VERSION ""

NS_ :

BS_:

BU_: WCM4 WCM3 WCM2 WCM VPM VLM VKM VICM VECM VDM VCU_RTOS_ETH VCU_ENTRY_ETH VCU_AGVM_ETH VCU UVM UPM TIM TEST_TOOL_1 TCP_ETH TCP TCM TCCM SRR_SRR_ETH SRR_SRR SRR_SLR_ETH SRR_SLR SRR_RR SRR_RF_ETH SRR_RF SRR_LR_CR SRR_LF_ETH SRR_LF SIB SDM SCL SBZA_R SBZA_L SBM SAM_RR SAM_RF SAM_LR SAM_LF SAM_BH SADS RadioLow_ETH RadioLow RSI_RTOS_ETH RSI RDCM PTM PLCM PFCM PDR_ETH PDR PCM PA ODS2 ODS NVM MTCM_R MTCM_L MSM_RR MSM_P MSM_LR MSM_D MSB2 MSB1 MRCM_R MRCM_L MFC LRR_RR_ETH LRR_LR_ETH LRR_CF_ETH LRR LRL_CF_ETH LIB_48V LIB1 IPC_INT IPC_GP IPC ICS_Info ICCM HVAC_FP_R HVAC_FP_F HUD_CAN HDLM FPI_RTOS_ETH FPI FOPM FCM_LC FCM EPSb EPS_1 EPSRAb EPSRAa EPS EOCM_HC_Superset EOCM_HCP2 EOCM ELM ECP_X1 ECP_S2 ECP_S ECP_MC ECP_H3 ECP_H2 ECP_H1 ECP_E ECM EBCM DMS DEFC DCM CSM_ETH CSM_AV CSM CGM_OTA_ETH CGM BSM_MH BSM_HEV BSM BCM ARS ARB APA AOS AMP ALC AHS AHL_AFL ADIMb ADIMa ACP2_MCU

BO_ 1416 Isolated_GWCGM_PDU04: 6 CGM
 SG_ TrffcLgtAsstWrnChmEvntStat : 1|2@0+ (1,0) [0|3] "" IPC,IPC_INT,VCU
 SG_ TrffcLgtAsstCstCurrSetVal : 4|3@0+ (1,0) [0|7] "" RadioLow,CSM,CSM_AV,VCU
 SG_ GlrFrHgBmRspTypCstCurSetVal : 7|3@0+ (1,0) [0|7] "" RadioLow,CSM,CSM_AV,VCU
 SG_ GlrFrHgBmRspTypCstAvlFlg7 : 8|1@0+ (1,0) [0|1] "" RadioLow,CSM,CSM_AV,VCU
 SG_ GlrFrHgBmRspTypCstAvlFlg6 : 9|1@0+ (1,0) [0|1] "" RadioLow,CSM,CSM_AV,VCU
 SG_ GlrFrHgBmRspTypCstAvlFlg5 : 10|1@0+ (1,0) [0|1] "" RadioLow,CSM,CSM_AV,VCU
 SG_ GlrFrHgBmRspTypCstAvlFlg4 : 11|1@0+ (1,0) [0|1] "" RadioLow,CSM,CSM_AV,VCU
 SG_ GlrFrHgBmRspTypCstAvlFlg3 : 12|1@0+ (1,0) [0|1] "" RadioLow,CSM,CSM_AV,VCU
 SG_ GlrFrHgBmRspTypCstAvlFlg2 : 13|1@0+ (1,0) [0|1] "" RadioLow,CSM,CSM_AV,VCU
 SG_ GlrFrHgBmRspTypCstAvlFlg1 : 14|1@0+ (1,0) [0|1] "" RadioLow,CSM,CSM_AV,VCU
 SG_ AutoHgBmCtrlIO : 15|1@0+ (1,0) [0|1] "" CSM,CSM_AV,IPC,IPC_INT,VCU
 SG_ TrffcLgtAsstCstAvlFlg7 : 16|1@0+ (1,0) [0|1] "" RadioLow,CSM,CSM_AV,VCU
 SG_ TrffcLgtAsstCstAvlFlg6 : 17|1@0+ (1,0) [0|1] "" RadioLow,CSM,CSM_AV,VCU
 SG_ TrffcLgtAsstCstAvlFlg5 : 18|1@0+ (1,0) [0|1] "" RadioLow,CSM,CSM_AV,VCU
 SG_ TrffcLgtAsstCstAvlFlg4 : 19|1@0+ (1,0) [0|1] "" RadioLow,CSM,CSM_AV,VCU
 SG_ TrffcLgtAsstCstAvlFlg3 : 20|1@0+ (1,0) [0|1] "" RadioLow,CSM,CSM_AV,VCU
 SG_ TrffcLgtAsstCstAvlFlg2 : 21|1@0+ (1,0) [0|1] "" RadioLow,CSM,CSM_AV,VCU
 SG_ TrffcLgtAsstCstAvlFlg1 : 22|1@0+ (1,0) [0|1] "" RadioLow,CSM,CSM_AV,VCU
 SG_ GlrFrHgBmRspTypCstStAvl : 23|1@0+ (1,0) [0|1] "" RadioLow,CSM,CSM_AV,VCU
 SG_ TrffcLgtAsstCstSetAval : 31|1@0+ (1,0) [0|1] "" RadioLow,CSM,CSM_AV,VCU

BO_ 1811 Isolated_GWCGM_PDU05: 8 CGM
 SG_ TSMCurrSpdLim : 7|8@0+ (1,0) [0|255] "" CSM,CSM_AV,IPC,IPC_INT,VCU
 SG_ TSMEurDispSgn2Mn : 9|6@0+ (1,0) [0|54] "" IPC,IPC_INT,VCU
 SG_ TSMEurDispSgn1Mn : 15|6@0+ (1,0) [0|54] "" IPC,IPC_INT,VCU
 SG_ TSMUSAndCADispSgn1Mn : 19|6@0+ (1,0) [0|45] "" CSM,CSM_AV,IPC,IPC_INT,VCU
 SG_ TSMUSAndCADispSgn2Mn : 29|6@0+ (1,0) [0|45] "" CSM,CSM_AV,IPC,IPC_INT,VCU
 SG_ TSMEurDispSgn2AddOn : 35|4@0+ (1,0) [0|15] "" IPC,IPC_INT,VCU
 SG_ TSMEurDispSgn1AddOn : 39|4@0+ (1,0) [0|15] "" IPC,IPC_INT,VCU
 SG_ FrwdVsFlDtcnIndOn : 40|1@0+ (1,0) [0|1] "" CSM,CSM_AV,IPC,IPC_INT,VCU
 SG_ FrwdVsAdvWthrIndOn : 41|1@0+ (1,0) [0|1] "" CSM,CSM_AV,IPC,IPC_INT,VCU
 SG_ TSMUSAndCADispSgn2AddOn : 44|3@0+ (1,0) [0|5] "" CSM,CSM_AV,IPC,IPC_INT,VCU
 SG_ TSMUSAndCADispSgn1AddOn : 47|3@0+ (1,0) [0|5] "" CSM,CSM_AV,IPC,IPC_INT,VCU
 SG_ TrffcLgtAsstHUDWrnIndOn : 48|1@0+ (1,0) [0|1] "" IPC,IPC_INT,VCU
 SG_ TrffcLgtAsstClstrWrnIndOn : 49|1@0+ (1,0) [0|1] "" IPC,IPC_INT,VCU
 SG_ TSMSgnNtfnIndOn : 50|1@0+ (1,0) [0|1] "" IPC,IPC_INT,VCU
 SG_ TSMPDAMnSgnFlshgReq : 51|1@0+ (1,0) [0|1] "" IPC,IPC_INT,VCU
 SG_ TSMNoEntryIndOn : 52|1@0+ (1,0) [0|1] "" IPC,IPC_INT,VCU
 SG_ TSMIcePsblIndOn : 53|1@0+ (1,0) [0|1] "" IPC,IPC_INT,VCU
 SG_ TSMAddTrfSgnAvIndOn : 54|1@0+ (1,0) [0|1] "" IPC,IPC_INT,VCU
 SG_ FrwdVsFllBlckIndOn : 55|1@0+ (1,0) [0|1] "" CSM,CSM_AV,IPC,IPC_INT,VCU
 SG_ TrffcLgtAsstRLADWrnIndOn : 63|1@0+ (1,0) [0|1] "" IPC,IPC_INT,VCU

BO_ 1510 Isolated_GWCGM_PDU06: 6 CGM
 SG_ SBZALCAVisIndStatLt : 7|2@0+ (1,0) [0|2] "" CSM,CSM_AV,VCU

BO_ 1511 Isolated_GWCGM_PDU07: 6 CGM
 SG_ SBZALCAVisIndStatRt : 7|2@0+ (1,0) [0|2] "" CSM,CSM_AV,VCU

BO_ 1429 Isolated_GWCGM_PDU08: 6 CSM
 SG_ HtchVwAutoElecPrkBrkAppReqd : 7|1@0+ (1,0) [0|1] "" Vector__XXX

BO_ 1512 Isolated_GWCGM_PDU10: 6 CGM
 SG_ AutoHgBmActReq : 7|1@0+ (1,0) [0|1] "" CSM,CSM_AV,VCU

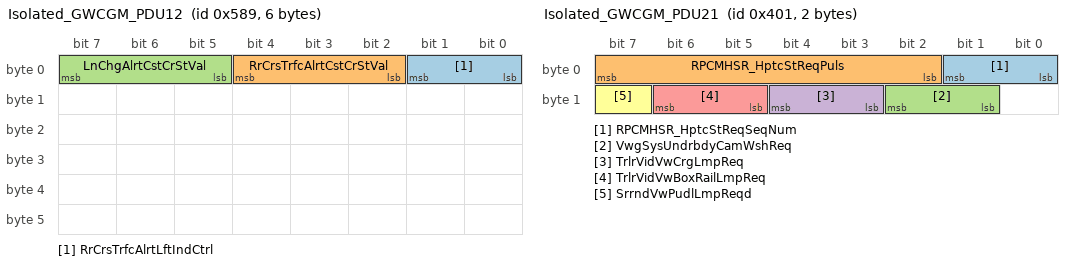
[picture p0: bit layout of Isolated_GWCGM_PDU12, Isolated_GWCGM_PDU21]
BO_ 1417 Isolated_GWCGM_PDU12: 6 CGM
 SG_ RrCrsTrfcAlrtLftIndCtrl : 1|2@0+ (1,0) [0|2] "" RadioLow,CSM,CSM_AV,VCU
 SG_ RrCrsTrfcAlrtCstCrStVal : 4|3@0+ (1,0) [0|7] "" RadioLow,CSM,CSM_AV,VCU
 SG_ LnChgAlrtCstCrStVal : 7|3@0+ (1,0) [0|7] "" RadioLow,TCP,CSM,CSM_AV,VCU

BO_ 1418 Isolated_GWCGM_PDU15: 8 CGM
 SG_ SBZAlrtCstCrStVal : 1|3@0+ (1,0) [0|7] "" RadioLow,CSM,CSM_AV,VCU
 SG_ ByclDtnCstCurrSetVal : 4|3@0+ (1,0) [0|2] "" VCU
 SG_ ByclDtnArbdIndStat : 7|3@0+ (1,0) [0|7] "" VCU
 SG_ ByclDtnCstAvlFlg1 : 8|1@0+ (1,0) [0|1] "" VCU
 SG_ RrCrsTrfcAlrtLtSdChmEvntStat : 10|2@0+ (1,0) [0|2] "" CSM,CSM_AV,IPC,IPC_INT,VCU
 SG_ ByclDtnArbdLvl2ChmEvntStat : 12|2@0+ (1,0) [0|2] "" VCU
 SG_ ByclDtnArbdLvl1ChmEvntStat : 14|2@0+ (1,0) [0|2] "" VCU
 SG_ LnChgAlrtCstAvlFlg1 : 16|1@0+ (1,0) [0|1] "" RadioLow,TCP,CSM,CSM_AV,VCU
 SG_ ByclDtnCstSetAval : 17|1@0+ (1,0) [0|1] "" VCU
 SG_ ByclDtnCstAvlFlg7 : 18|1@0+ (1,0) [0|1] "" VCU
 SG_ ByclDtnCstAvlFlg6 : 19|1@0+ (1,0) [0|1] "" VCU
 SG_ ByclDtnCstAvlFlg5 : 20|1@0+ (1,0) [0|1] "" VCU
 SG_ ByclDtnCstAvlFlg4 : 21|1@0+ (1,0) [0|1] "" VCU
 SG_ ByclDtnCstAvlFlg3 : 22|1@0+ (1,0) [0|1] "" VCU
 SG_ ByclDtnCstAvlFlg2 : 23|1@0+ (1,0) [0|1] "" VCU
 SG_ LnChgAlrtSysOffIndOn : 24|1@0+ (1,0) [0|1] "" TCP,IPC,IPC_INT,VCU
 SG_ LnChgAlrtCstStAvl : 25|1@0+ (1,0) [0|1] "" RadioLow,TCP,CSM,CSM_AV,VCU
 SG_ LnChgAlrtCstAvlFlg7 : 26|1@0+ (1,0) [0|1] "" RadioLow,TCP,CSM,CSM_AV,VCU
 SG_ LnChgAlrtCstAvlFlg6 : 27|1@0+ (1,0) [0|1] "" RadioLow,TCP,CSM,CSM_AV,VCU
 SG_ LnChgAlrtCstAvlFlg5 : 28|1@0+ (1,0) [0|1] "" RadioLow,TCP,CSM,CSM_AV,VCU
 SG_ LnChgAlrtCstAvlFlg4 : 29|1@0+ (1,0) [0|1] "" RadioLow,TCP,CSM,CSM_AV,VCU
 SG_ LnChgAlrtCstAvlFlg3 : 30|1@0+ (1,0) [0|1] "" RadioLow,TCP,CSM,CSM_AV,VCU
 SG_ LnChgAlrtCstAvlFlg2 : 31|1@0+ (1,0) [0|1] "" RadioLow,TCP,CSM,CSM_AV,VCU
 SG_ RrCrsTrfcAlrtCstStAvl : 32|1@0+ (1,0) [0|1] "" RadioLow,CSM,CSM_AV,VCU
 SG_ RrCrsTrfcAlrtCstAvlFlg7 : 33|1@0+ (1,0) [0|1] "" RadioLow,CSM,CSM_AV,VCU
 SG_ RrCrsTrfcAlrtCstAvlFlg6 : 34|1@0+ (1,0) [0|1] "" RadioLow,CSM,CSM_AV,VCU
 SG_ RrCrsTrfcAlrtCstAvlFlg5 : 35|1@0+ (1,0) [0|1] "" RadioLow,CSM,CSM_AV,VCU
 SG_ RrCrsTrfcAlrtCstAvlFlg4 : 36|1@0+ (1,0) [0|1] "" RadioLow,CSM,CSM_AV,VCU
 SG_ RrCrsTrfcAlrtCstAvlFlg3 : 37|1@0+ (1,0) [0|1] "" RadioLow,CSM,CSM_AV,VCU
 SG_ RrCrsTrfcAlrtCstAvlFlg2 : 38|1@0+ (1,0) [0|1] "" RadioLow,CSM,CSM_AV,VCU
 SG_ RrCrsTrfcAlrtCstAvlFlg1 : 39|1@0+ (1,0) [0|1] "" RadioLow,CSM,CSM_AV,VCU
 SG_ RrCrsTrfcBrkgAutoBrkgRelIndOn : 45|1@0+ (1,0) [0|1] "" IPC,IPC_INT,VCU
 SG_ RrCrsTrfcAutoBrkgOffIndOn : 46|1@0+ (1,0) [0|1] "" IPC,IPC_INT,VCU
 SG_ RrCrsTrfcAlrtOffIndOn : 47|1@0+ (1,0) [0|1] "" IPC,IPC_INT,VCU

BO_ 1419 Isolated_GWCGM_PDU17: 6 CGM
 SG_ RrCrsTrfcAlrtRtSdChmEvntStat : 5|2@0+ (1,0) [0|2] "" CSM,CSM_AV,IPC,IPC_INT,VCU
 SG_ RrCrsTrfcAlrtRgIndCtrl : 7|2@0+ (1,0) [0|2] "" RadioLow,CSM,CSM_AV,VCU

BO_ 1025 Isolated_GWCGM_PDU21: 2 VCU
 SG_ RPCMHSR_HptcStReqSeqNum : 1|2@0+ (1,0) [0|3] "Count" CGM
 SG_ RPCMHSR_HptcStReqPuls : 7|6@0+ (1,0) [0|63] "pulses" CGM
 SG_ VwgSysUndrbdyCamWshReq : 10|2@0+ (1,0) [0|2] "" CGM
 SG_ TrlrVidVwCrgLmpReq : 12|2@0+ (1,0) [0|2] "" CGM
 SG_ TrlrVidVwBoxRailLmpReq : 14|2@0+ (1,0) [0|2] "" CGM
 SG_ SrrndVwPudlLmpReqd : 15|1@0+ (1,0) [0|1] "" CGM

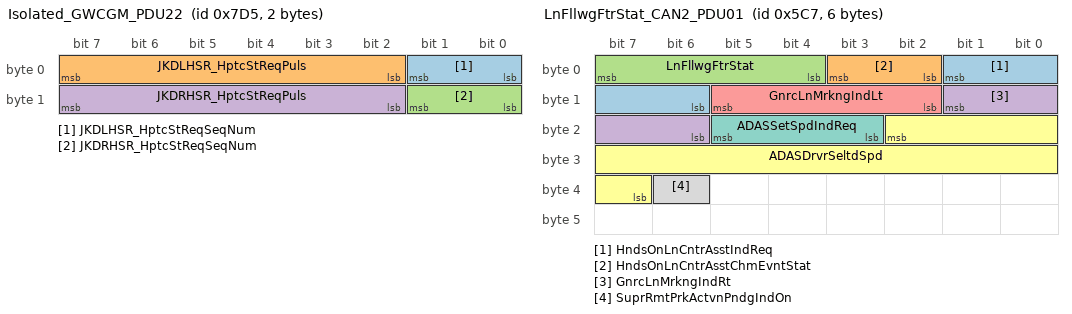
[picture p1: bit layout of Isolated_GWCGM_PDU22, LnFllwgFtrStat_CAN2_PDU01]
BO_ 2005 Isolated_GWCGM_PDU22: 2 VCU
 SG_ JKDLHSR_HptcStReqSeqNum : 1|2@0+ (1,0) [0|3] "counts" CGM
 SG_ JKDLHSR_HptcStReqPuls : 7|6@0+ (1,0) [0|63] "pulses" CGM
 SG_ JKDRHSR_HptcStReqSeqNum : 9|2@0+ (1,0) [0|3] "counts" CGM
 SG_ JKDRHSR_HptcStReqPuls : 15|6@0+ (1,0) [0|63] "pulses" CGM

BO_ 1479 LnFllwgFtrStat_CAN2_PDU01: 6 CGM
 SG_ HndsOnLnCntrAsstIndReq : 1|4@0+ (1,0) [0|7] "" IPC,IPC_INT,VCU
 SG_ HndsOnLnCntrAsstChmEvntStat : 3|2@0+ (1,0) [0|2] "" IPC,IPC_INT,VCU
 SG_ LnFllwgFtrStat : 7|4@0+ (1,0) [0|10] "" TCP
 SG_ GnrcLnMrkngIndRt : 9|4@0+ (1,0) [0|7] "" IPC,IPC_INT,VCU
 SG_ GnrcLnMrkngIndLt : 13|4@0+ (1,0) [0|7] "" IPC,IPC_INT,VCU
 SG_ ADASDrvrSeltdSpd : 18|12@0+ (0.0625,0) [0|255.938] "km/h" VCU
 SG_ ADASSetSpdIndReq : 21|3@0+ (1,0) [0|5] "" VCU
 SG_ SuprRmtPrkActvnPndgIndOn : 38|1@0+ (1,0) [0|1] "" VCU

BO_ 397 MFC_NM_PDU_On_CAN_5_Cluster: 8 MFC
 SG_ ISignal_MFC_CAN_5_Cluster : 23|48@0+ (1,0) [0|281474976710655] "" AMP,CGM,FPI,HVAC_FP_F,HVAC_FP_R,ICS_Info,PDR,PLCM,RSI,RadioLow,TCP,VKM,CSM,CSM_AV,IPC,IPC_INT,VCU,WCM,WCM2,WCM3,WCM4

BO_ 1883 PDU_1048: 8 CGM
 SG_ InvsblTrlrAux1CamPlcmtFdbkPtch : 7|12@0+ (0.1,-180) [-180|229.5] "degrees" CSM,CSM_AV,VCU
 SG_ InvsblTrlrAux1CamPlcmtFdbkRoll : 11|12@0+ (0.1,-180) [-180|229.5] "degrees" CSM,CSM_AV,VCU
 SG_ InvsblTrlrAux1CamPlcmtFdbkX : 31|12@0+ (0.1,-150) [-150|259.5] "cm" CSM,CSM_AV,VCU
 SG_ InvsblTrlrAux1CamPlcmtFdbkY : 35|12@0+ (0.1,-200) [-200|209.5] "cm" CSM,CSM_AV,VCU
 SG_ JckKnfDtnCstAvlFlg1 : 48|1@0+ (1,0) [0|1] "" RadioLow,CSM,CSM_AV,VCU
 SG_ CrgBedVwAutoLgtCstAvlFlg7 : 49|1@0+ (1,0) [0|1] "" RadioLow,CSM,CSM_AV,VCU
 SG_ CrgBedVwAutoLgtCstAvlFlg6 : 50|1@0+ (1,0) [0|1] "" RadioLow,CSM,CSM_AV,VCU
 SG_ CrgBedVwAutoLgtCstAvlFlg5 : 51|1@0+ (1,0) [0|1] "" RadioLow,CSM,CSM_AV,VCU
 SG_ CrgBedVwAutoLgtCstAvlFlg4 : 52|1@0+ (1,0) [0|1] "" RadioLow,CSM,CSM_AV,VCU
 SG_ CrgBedVwAutoLgtCstAvlFlg3 : 53|1@0+ (1,0) [0|1] "" RadioLow,CSM,CSM_AV,VCU
 SG_ CrgBedVwAutoLgtCstAvlFlg2 : 54|1@0+ (1,0) [0|1] "" RadioLow,CSM,CSM_AV,VCU
 SG_ CrgBedVwAutoLgtCstAvlFlg1 : 55|1@0+ (1,0) [0|1] "" RadioLow,CSM,CSM_AV,VCU
 SG_ JckKnfDtnCstAvlFlg7 : 58|1@0+ (1,0) [0|1] "" RadioLow,CSM,CSM_AV,VCU
 SG_ JckKnfDtnCstAvlFlg6 : 59|1@0+ (1,0) [0|1] "" RadioLow,CSM,CSM_AV,VCU
 SG_ JckKnfDtnCstAvlFlg5 : 60|1@0+ (1,0) [0|1] "" RadioLow,CSM,CSM_AV,VCU
 SG_ JckKnfDtnCstAvlFlg4 : 61|1@0+ (1,0) [0|1] "" RadioLow,CSM,CSM_AV,VCU
 SG_ JckKnfDtnCstAvlFlg3 : 62|1@0+ (1,0) [0|1] "" RadioLow,CSM,CSM_AV,VCU
 SG_ JckKnfDtnCstAvlFlg2 : 63|1@0+ (1,0) [0|1] "" RadioLow,CSM,CSM_AV,VCU

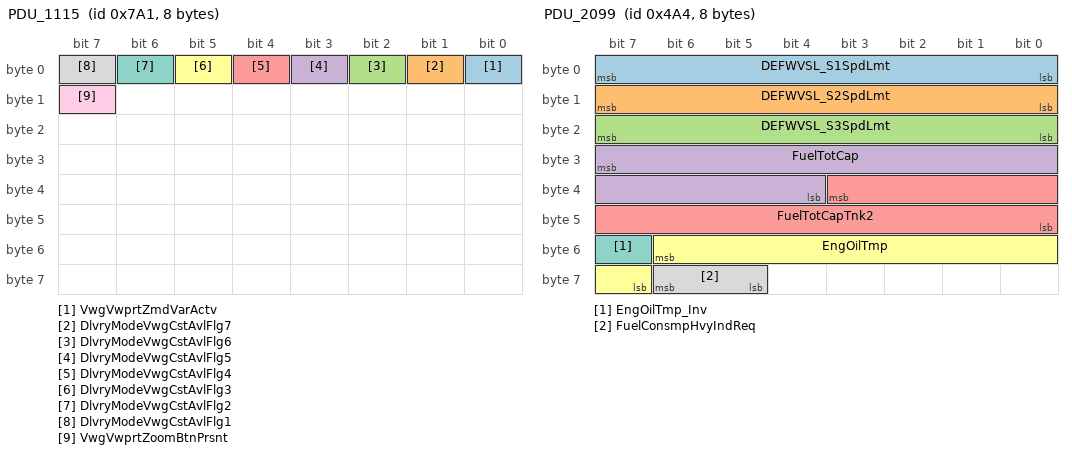
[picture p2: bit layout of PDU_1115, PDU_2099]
BO_ 1953 PDU_1115: 8 CGM
 SG_ VwgVwprtZmdVarActv : 0|1@0+ (1,0) [0|1] "" RadioLow,CSM,CSM_AV,VCU
 SG_ DlvryModeVwgCstAvlFlg7 : 1|1@0+ (1,0) [0|1] "" VCU
 SG_ DlvryModeVwgCstAvlFlg6 : 2|1@0+ (1,0) [0|1] "" VCU
 SG_ DlvryModeVwgCstAvlFlg5 : 3|1@0+ (1,0) [0|1] "" VCU
 SG_ DlvryModeVwgCstAvlFlg4 : 4|1@0+ (1,0) [0|1] "" VCU
 SG_ DlvryModeVwgCstAvlFlg3 : 5|1@0+ (1,0) [0|1] "" VCU
 SG_ DlvryModeVwgCstAvlFlg2 : 6|1@0+ (1,0) [0|1] "" VCU
 SG_ DlvryModeVwgCstAvlFlg1 : 7|1@0+ (1,0) [0|1] "" VCU
 SG_ VwgVwprtZoomBtnPrsnt : 15|1@0+ (1,0) [0|1] "" RadioLow,CSM,CSM_AV,VCU

BO_ 1114 PDU_1116: 8 CGM
 SG_ VwgCtlBtnPrsncBedHtch : 0|1@0+ (1,0) [0|1] "" RadioLow,CSM,CSM_AV,VCU
 SG_ VwgCtlBtnAvlUndrBdyFwdStActv : 1|1@0+ (1,0) [0|1] "" RadioLow,CSM,CSM_AV,VCU
 SG_ VwgCtlBtnAvlUndrBdyFwdRwdStActv : 2|1@0+ (1,0) [0|1] "" RadioLow,CSM,CSM_AV,VCU
 SG_ VwgCtlBtnAvlTopDnVwActv : 3|1@0+ (1,0) [0|1] "" RadioLow,CSM,CSM_AV,VCU
 SG_ DlvryModeVwgCstSetAval : 4|1@0+ (1,0) [0|1] "" VCU
 SG_ DlvryModeVwgCstCurrSetVal : 7|3@0+ (1,0) [0|2] "" VCU
 SG_ VwgCtlBtnPrsncFrtPrspctv : 8|1@0+ (1,0) [0|1] "" RadioLow,CSM,CSM_AV,VCU
 SG_ VwgCtlBtnPrsncFrtOvrhd : 9|1@0+ (1,0) [0|1] "" RadioLow,CSM,CSM_AV,VCU
 SG_ VwgCtlBtnPrsncFrtJnctn : 10|1@0+ (1,0) [0|1] "" RadioLow,CSM,CSM_AV,VCU
 SG_ VwgCtlBtnPrsncDynGdlns : 11|1@0+ (1,0) [0|1] "" RadioLow,CSM,CSM_AV,VCU
 SG_ VwgCtlBtnPrsncCurbOvrhd : 12|1@0+ (1,0) [0|1] "" RadioLow,CSM,CSM_AV,VCU
 SG_ VwgCtlBtnPrsncCurb : 13|1@0+ (1,0) [0|1] "" RadioLow,CSM,CSM_AV,VCU
 SG_ VwgCtlBtnPrsncCrgBed : 14|1@0+ (1,0) [0|1] "" RadioLow,CSM,CSM_AV,VCU
 SG_ VwgCtlBtnPrsncBowl : 15|1@0+ (1,0) [0|1] "" RadioLow,CSM,CSM_AV,VCU
 SG_ VwgCtlBtnPrsncSdRwd : 16|1@0+ (1,0) [0|1] "" RadioLow,CSM,CSM_AV,VCU
 SG_ VwgCtlBtnPrsncSdFwd : 17|1@0+ (1,0) [0|1] "" RadioLow,CSM,CSM_AV,VCU
 SG_ VwgCtlBtnPrsncRrPrspctv : 18|1@0+ (1,0) [0|1] "" RadioLow,CSM,CSM_AV,VCU
 SG_ VwgCtlBtnPrsncRrOvrhd : 19|1@0+ (1,0) [0|1] "" RadioLow,CSM,CSM_AV,VCU
 SG_ VwgCtlBtnPrsncRrJnctn : 20|1@0+ (1,0) [0|1] "" RadioLow,CSM,CSM_AV,VCU
 SG_ VwgCtlBtnPrsncRrHtch : 21|1@0+ (1,0) [0|1] "" RadioLow,CSM,CSM_AV,VCU
 SG_ VwgCtlBtnPrsncJP : 22|1@0+ (1,0) [0|1] "" RadioLow,CSM,CSM_AV,VCU
 SG_ VwgCtlBtnPrsncInvsblTrlr : 23|1@0+ (1,0) [0|1] "" RadioLow,CSM,CSM_AV,VCU
 SG_ VwgCtlBtnPrsncUndrBdyFwdRwdSt : 24|1@0+ (1,0) [0|1] "" RadioLow,CSM,CSM_AV,VCU
 SG_ VwgCtlBtnPrsncUndrBdyFwd : 25|1@0+ (1,0) [0|1] "" RadioLow,CSM,CSM_AV,VCU
 SG_ VwgCtlBtnPrsncTrlrTowMir : 26|1@0+ (1,0) [0|1] "" RadioLow,CSM,CSM_AV,VCU
 SG_ VwgCtlBtnPrsncTrlrGdlns : 27|1@0+ (1,0) [0|1] "" RadioLow,CSM,CSM_AV,VCU
 SG_ VwgCtlBtnPrsncTrlrAux1Cmbd : 28|1@0+ (1,0) [0|1] "" RadioLow,CSM,CSM_AV,VCU
 SG_ VwgCtlBtnPrsncTrlrAux1 : 29|1@0+ (1,0) [0|1] "" RadioLow,CSM,CSM_AV,VCU
 SG_ VwgCtlBtnPrsncTransparentHood : 30|1@0+ (1,0) [0|1] "" RadioLow,CSM,CSM_AV,VCU
 SG_ VwgCtlBtnPrsncTopDnSrrndVw : 31|1@0+ (1,0) [0|1] "" RadioLow,CSM,CSM_AV,VCU
 SG_ TrlrCamCalPrgs : 33|7@0+ (1,0) [0|127] "" CSM,CSM_AV,VCU
 SG_ VwgVwprtStsTopDnVwActv : 34|1@0+ (1,0) [0|1] "" RadioLow,CSM,CSM_AV,VCU
 SG_ VwgVwprtNtfnActv : 35|1@0+ (1,0) [0|1] "" RadioLow,CSM,CSM_AV,VCU
 SG_ VwgCtlBtnPrsncTrlrAux2 : 36|1@0+ (1,0) [0|1] "" RadioLow,CSM,CSM_AV,VCU
 SG_ VwgCtlBtnPrsncZmdBowl : 37|1@0+ (1,0) [0|1] "" RadioLow,CSM,CSM_AV,VCU
 SG_ VwgCtlBtnPrsncUndrBdyRwd : 38|1@0+ (1,0) [0|1] "" RadioLow,CSM,CSM_AV,VCU
 SG_ VwgCtlBtnPrsncUndrBdyFwdSt : 39|1@0+ (1,0) [0|1] "" RadioLow,CSM,CSM_AV,VCU
 SG_ TrlrJckKnfVisAlrtReq : 41|2@0+ (1,0) [0|3] "" CSM,CSM_AV,VCU
 SG_ TrlrCamCalPrgs_Inv : 42|1@0+ (1,0) [0|1] "" CSM,CSM_AV,VCU

BO_ 1984 PDU_1117: 8 CGM
 SG_ DMPDAutoClsTmLFCstSetAval : 0|1@0+ (1,0) [0|1] "" VCU
 SG_ DMPDAutoClsTmLFCstAvlFlg7 : 1|1@0+ (1,0) [0|1] "" VCU
 SG_ DMPDAutoClsTmLFCstAvlFlg6 : 2|1@0+ (1,0) [0|1] "" VCU
 SG_ DMPDAutoClsTmLFCstAvlFlg5 : 3|1@0+ (1,0) [0|1] "" VCU
 SG_ DMPDAutoClsTmLFCstAvlFlg4 : 4|1@0+ (1,0) [0|1] "" VCU
 SG_ DMPDAutoClsTmLFCstAvlFlg3 : 5|1@0+ (1,0) [0|1] "" VCU
 SG_ DMPDAutoClsTmLFCstAvlFlg2 : 6|1@0+ (1,0) [0|1] "" VCU
 SG_ DMPDAutoClsTmLFCstAvlFlg1 : 7|1@0+ (1,0) [0|1] "" VCU
 SG_ DMPDClsOutofPrkLFCstSetAval : 8|1@0+ (1,0) [0|1] "" VCU
 SG_ DMPDClsOutofPrkLFCstAvlFlg7 : 9|1@0+ (1,0) [0|1] "" VCU
 SG_ DMPDClsOutofPrkLFCstAvlFlg6 : 10|1@0+ (1,0) [0|1] "" VCU
 SG_ DMPDClsOutofPrkLFCstAvlFlg5 : 11|1@0+ (1,0) [0|1] "" VCU
 SG_ DMPDClsOutofPrkLFCstAvlFlg4 : 12|1@0+ (1,0) [0|1] "" VCU
 SG_ DMPDClsOutofPrkLFCstAvlFlg3 : 13|1@0+ (1,0) [0|1] "" VCU
 SG_ DMPDClsOutofPrkLFCstAvlFlg2 : 14|1@0+ (1,0) [0|1] "" VCU
 SG_ DMPDClsOutofPrkLFCstAvlFlg1 : 15|1@0+ (1,0) [0|1] "" VCU
 SG_ DMPDDOBlkhdDrOpnLFCstSetAval : 16|1@0+ (1,0) [0|1] "" VCU
 SG_ DMPDDOBlkhdDrOpnLFCstAvlFlg7 : 17|1@0+ (1,0) [0|1] "" VCU
 SG_ DMPDDOBlkhdDrOpnLFCstAvlFlg6 : 18|1@0+ (1,0) [0|1] "" VCU
 SG_ DMPDDOBlkhdDrOpnLFCstAvlFlg5 : 19|1@0+ (1,0) [0|1] "" VCU
 SG_ DMPDDOBlkhdDrOpnLFCstAvlFlg4 : 20|1@0+ (1,0) [0|1] "" VCU
 SG_ DMPDDOBlkhdDrOpnLFCstAvlFlg3 : 21|1@0+ (1,0) [0|1] "" VCU
 SG_ DMPDDOBlkhdDrOpnLFCstAvlFlg2 : 22|1@0+ (1,0) [0|1] "" VCU
 SG_ DMPDDOBlkhdDrOpnLFCstAvlFlg1 : 23|1@0+ (1,0) [0|1] "" VCU
 SG_ SCAOOAByKeyFobLFCstSetAval : 24|1@0+ (1,0) [0|1] "" VCU
 SG_ SCAOOAByKeyFobLFCstAvlFlg7 : 25|1@0+ (1,0) [0|1] "" VCU
 SG_ SCAOOAByKeyFobLFCstAvlFlg6 : 26|1@0+ (1,0) [0|1] "" VCU
 SG_ SCAOOAByKeyFobLFCstAvlFlg5 : 27|1@0+ (1,0) [0|1] "" VCU
 SG_ SCAOOAByKeyFobLFCstAvlFlg4 : 28|1@0+ (1,0) [0|1] "" VCU
 SG_ SCAOOAByKeyFobLFCstAvlFlg3 : 29|1@0+ (1,0) [0|1] "" VCU
 SG_ SCAOOAByKeyFobLFCstAvlFlg2 : 30|1@0+ (1,0) [0|1] "" VCU
 SG_ SCAOOAByKeyFobLFCstAvlFlg1 : 31|1@0+ (1,0) [0|1] "" VCU
 SG_ SCAOOAByVirtKeyLFCstSetAval : 32|1@0+ (1,0) [0|1] "" VCU
 SG_ SCAOOAByVirtKeyLFCstAvlFlg7 : 33|1@0+ (1,0) [0|1] "" VCU
 SG_ SCAOOAByVirtKeyLFCstAvlFlg6 : 34|1@0+ (1,0) [0|1] "" VCU
 SG_ SCAOOAByVirtKeyLFCstAvlFlg5 : 35|1@0+ (1,0) [0|1] "" VCU
 SG_ SCAOOAByVirtKeyLFCstAvlFlg4 : 36|1@0+ (1,0) [0|1] "" VCU
 SG_ SCAOOAByVirtKeyLFCstAvlFlg3 : 37|1@0+ (1,0) [0|1] "" VCU
 SG_ SCAOOAByVirtKeyLFCstAvlFlg2 : 38|1@0+ (1,0) [0|1] "" VCU
 SG_ SCAOOAByVirtKeyLFCstAvlFlg1 : 39|1@0+ (1,0) [0|1] "" VCU
 SG_ SCAPDBrktoClsLFCstSetAval : 40|1@0+ (1,0) [0|1] "" VCU
 SG_ SCAPDBrktoClsLFCstAvlFlg7 : 41|1@0+ (1,0) [0|1] "" VCU
 SG_ SCAPDBrktoClsLFCstAvlFlg6 : 42|1@0+ (1,0) [0|1] "" VCU
 SG_ SCAPDBrktoClsLFCstAvlFlg5 : 43|1@0+ (1,0) [0|1] "" VCU
 SG_ SCAPDBrktoClsLFCstAvlFlg4 : 44|1@0+ (1,0) [0|1] "" VCU
 SG_ SCAPDBrktoClsLFCstAvlFlg3 : 45|1@0+ (1,0) [0|1] "" VCU
 SG_ SCAPDBrktoClsLFCstAvlFlg2 : 46|1@0+ (1,0) [0|1] "" VCU
 SG_ SCAPDBrktoClsLFCstAvlFlg1 : 47|1@0+ (1,0) [0|1] "" VCU
 SG_ SCAPDOpnMaxTrvlCstSetAval : 48|1@0+ (1,0) [0|1] "" VCU
 SG_ SCAPDOpnMaxTrvlCstAvlFlg7 : 49|1@0+ (1,0) [0|1] "" VCU
 SG_ SCAPDOpnMaxTrvlCstAvlFlg6 : 50|1@0+ (1,0) [0|1] "" VCU
 SG_ SCAPDOpnMaxTrvlCstAvlFlg5 : 51|1@0+ (1,0) [0|1] "" VCU
 SG_ SCAPDOpnMaxTrvlCstAvlFlg4 : 52|1@0+ (1,0) [0|1] "" VCU
 SG_ SCAPDOpnMaxTrvlCstAvlFlg3 : 53|1@0+ (1,0) [0|1] "" VCU
 SG_ SCAPDOpnMaxTrvlCstAvlFlg2 : 54|1@0+ (1,0) [0|1] "" VCU
 SG_ SCAPDOpnMaxTrvlCstAvlFlg1 : 55|1@0+ (1,0) [0|1] "" VCU
 SG_ DMPDClsOutofPrkLFCstCurrSetVal : 59|3@0+ (1,0) [0|2] "" VCU
 SG_ DMPDAutoClsTmLFCstCurrSetVal : 62|3@0+ (1,0) [0|3] "" VCU
 SG_ SCAPwrDrMtnLFVirtCtlAval : 63|1@0+ (1,0) [0|1] "" VCU

BO_ 1060 PDU_1118: 8 CGM
 SG_ PwrSdClsrLFBlckdIndOn : 0|1@0+ (1,0) [0|1] "" VCU
 SG_ PwrSdClsrLFServIndOn : 15|1@0+ (1,0) [0|1] "" VCU

BO_ 1059 PDU_1119: 8 CGM
 SG_ PwrSdClsrLRBlckdIndOn : 0|1@0+ (1,0) [0|1] "" VCU
 SG_ PwrSdClsrLRServIndOn : 15|1@0+ (1,0) [0|1] "" VCU

BO_ 1188 PDU_2099: 8 CGM
 SG_ DEFWVSL_S1SpdLmt : 7|8@0+ (1,0) [0|255] "km / h" IPC,IPC_INT,VCU
 SG_ DEFWVSL_S2SpdLmt : 15|8@0+ (1,0) [0|255] "km / h" IPC,IPC_INT,VCU
 SG_ DEFWVSL_S3SpdLmt : 23|8@0+ (1,0) [0|255] "km / h" IPC,IPC_INT,VCU
 SG_ FuelTotCap : 31|12@0+ (0.125,0) [0|511.875] "liters" TCP,CSM,CSM_AV,IPC,IPC_INT,VCU
 SG_ FuelTotCapTnk2 : 35|12@0+ (0.125,0) [0|511.875] "liters" CSM,CSM_AV,IPC,IPC_INT,VCU
 SG_ EngOilTmp : 54|8@0+ (1,-40) [-40|215] "deg C" PDR,TCP,CSM,CSM_AV,IPC,IPC_INT,VCU
 SG_ EngOilTmp_Inv : 55|1@0+ (1,0) [0|1] "" PDR,CSM,CSM_AV,IPC,IPC_INT,VCU
 SG_ FuelConsmpHvyIndReq : 62|2@0+ (1,0) [0|2] "" IPC,IPC_INT,VCU

BO_ 1792 PDU_2100: 8 CGM
 SG_ DslExFldTpWrngIndRq : 3|4@0+ (1,0) [0|15] "" IPC,IPC_INT,VCU
 SG_ DslExFldCnWrngIndRq : 7|4@0+ (1,0) [0|15] "" IPC,IPC_INT,VCU
 SG_ DslExhFldQlyWrngIReq : 11|4@0+ (1,0) [0|15] "" IPC,IPC_INT,VCU
 SG_ DslExNxEmWrngIndRq : 15|4@0+ (1,0) [0|15] "" IPC,IPC_INT,VCU
 SG_ DslExhFldRmnDist : 23|15@0+ (2,0) [0|65534] "km" TCP,CSM,CSM_AV,IPC,IPC_INT,VCU
 SG_ DslExhFldRmnDist_Inv : 24|1@0+ (1,0) [0|1] "" TCP,CSM,CSM_AV,IPC,IPC_INT,VCU
 SG_ DslExhFluidDistTIndcmt : 35|15@0+ (2,0) [0|65534] "km" IPC,IPC_INT,VCU
 SG_ DslExhFldWrngIdRqER : 39|4@0+ (1,0) [0|15] "" TCP,IPC,IPC_INT,VCU
 SG_ ASIRI_Ind05 : 48|1@0+ (1,0) [0|1] "" TCP,CSM,CSM_AV,VCU
 SG_ ASIRI_Ind04 : 49|1@0+ (1,0) [0|1] "" TCP,CSM,CSM_AV,VCU
 SG_ ASIRI_Ind03 : 50|1@0+ (1,0) [0|1] "" TCP,CSM,CSM_AV,VCU
 SG_ ASIRI_Ind02 : 51|1@0+ (1,0) [0|1] "" TCP,CSM,CSM_AV,VCU
 SG_ ASIRI_Ind01 : 52|1@0+ (1,0) [0|1] "" TCP,CSM,CSM_AV,VCU
 SG_ FstIdlModeIndReq : 57|2@0+ (1,0) [0|3] "" IPC,IPC_INT,VCU
 SG_ CkFlFilrCapIO : 58|1@0+ (1,0) [0|1] "" CSM,CSM_AV,IPC,IPC_INT,VCU
 SG_ CbnHtrWrmUpIndOn : 59|1@0+ (1,0) [0|1] "" IPC,IPC_INT,VCU
 SG_ AppCltchAutSrtIO : 60|1@0+ (1,0) [0|1] "" CSM,CSM_AV,IPC,IPC_INT,VCU
 SG_ ASIRI_Ind08 : 61|1@0+ (1,0) [0|1] "" TCP,CSM,CSM_AV,VCU
 SG_ ASIRI_Ind07 : 62|1@0+ (1,0) [0|1] "" TCP,CSM,CSM_AV,VCU
 SG_ ASIRI_Ind06 : 63|1@0+ (1,0) [0|1] "" TCP,CSM,CSM_AV,VCU

BO_ 1273 PDU_2101: 8 CGM
 SG_ PTOSet1SpdCstCurrSetVal : 3|4@0+ (1,0) [0|15] "" RadioLow,CSM,CSM_AV,VCU
 SG_ PTOEngRunTmrCstCurrSetVal : 7|4@0+ (1,0) [0|15] "" RadioLow,CSM,CSM_AV,VCU
 SG_ MnlTrnsIndReq : 8|3@0+ (1,0) [0|3] "" IPC,IPC_INT,VCU
 SG_ EngAirFiltMonSts : 11|3@0+ (1,0) [0|5] "" CSM,CSM_AV,IPC,IPC_INT,VCU
 SG_ PTOSet2SpdCstCurrSetVal : 15|4@0+ (1,0) [0|15] "" RadioLow,CSM,CSM_AV,VCU
 SG_ PTOTpStpSpdCstCurrSetVal : 18|3@0+ (1,0) [0|7] "" RadioLow,CSM,CSM_AV,VCU
 SG_ PTOStndbySpdCstCurrSetVal : 21|3@0+ (1,0) [0|7] "" RadioLow,CSM,CSM_AV,VCU
 SG_ EngHtStpEngIO : 24|1@0+ (1,0) [0|1] "" TCP,CSM,CSM_AV,IPC,IPC_INT,VCU
 SG_ EngHtFlEnrchmntIO : 25|1@0+ (1,0) [0|1] "" TCP,CSM,CSM_AV,IPC,IPC_INT,VCU
 SG_ PTOModeCstCurrSetVal : 27|2@0+ (1,0) [0|2] "" RadioLow,CSM,CSM_AV,VCU
 SG_ PTOEngmntStsInd : 29|2@0+ (1,0) [0|3] "" IPC,IPC_INT,VCU
 SG_ PTOEngSpdTypCstCurrSetVal : 31|2@0+ (1,0) [0|2] "" RadioLow,CSM,CSM_AV,VCU
 SG_ EngWtrInFlIO : 32|1@0+ (1,0) [0|1] "" TCP,CSM,CSM_AV,IPC,IPC_INT,VCU
 SG_ EngSpdLmtnMdAct : 33|1@0+ (1,0) [0|1] "" CSM,CSM_AV,IPC,IPC_INT,VCU
 SG_ EngShtdwnPndgIO : 34|1@0+ (1,0) [0|1] "" TCP,CSM,CSM_AV,IPC,IPC_INT,VCU
 SG_ EngOilStrvtnIO : 35|1@0+ (1,0) [0|1] "" CSM,CSM_AV,IPC,IPC_INT,VCU
 SG_ EngOilPrsLwIO : 36|1@0+ (1,0) [0|1] "" TCP,CSM,CSM_AV,IPC,IPC_INT,VCU
 SG_ EngOilLvlLwIO : 37|1@0+ (1,0) [0|1] "" RadioLow,TCP,VKM,CSM,CSM_AV,IPC,IPC_INT,VCU
 SG_ EngOilHotIO : 38|1@0+ (1,0) [0|1] "" CSM,CSM_AV,IPC,IPC_INT,VCU
 SG_ EngOilChngIO : 39|1@0+ (1,0) [0|1] "" RadioLow,TCP,VKM,CSM,CSM_AV,IPC,IPC_INT,VCU
 SG_ PTOMblModeTransInGrIndOn : 40|1@0+ (1,0) [0|1] "" IPC,IPC_INT,VCU
 SG_ PTOEngUpnBrkRelIndOn : 41|1@0+ (1,0) [0|1] "" IPC,IPC_INT,VCU
 SG_ PTOEngSpdTypCstSetAval : 42|1@0+ (1,0) [0|1] "" RadioLow,CSM,CSM_AV,VCU
 SG_ PTOEngRunTmrCstSetAval : 43|1@0+ (1,0) [0|1] "" RadioLow,CSM,CSM_AV,VCU
 SG_ PTODisengCruzCtlIndOn : 44|1@0+ (1,0) [0|1] "" IPC,IPC_INT,VCU
 SG_ PTOAccelUpnBrkRelIndOn : 45|1@0+ (1,0) [0|1] "" IPC,IPC_INT,VCU
 SG_ PTExPrtclFltrWrnIO : 46|1@0+ (1,0) [0|1] "" TCP,CSM,CSM_AV,IPC,IPC_INT,VCU
 SG_ PTExPrtclFltrWrn2IO : 47|1@0+ (1,0) [0|1] "" TCP,CSM,CSM_AV,IPC,IPC_INT,VCU
 SG_ PTOSet2SpdCstSetAval : 48|1@0+ (1,0) [0|1] "" RadioLow,CSM,CSM_AV,VCU
 SG_ PTOSet1SpdCstSetAval : 49|1@0+ (1,0) [0|1] "" RadioLow,CSM,CSM_AV,VCU
 SG_ PTOServIndOn : 50|1@0+ (1,0) [0|1] "" IPC,IPC_INT,VCU
 SG_ PTORelBrkPedIndOn : 51|1@0+ (1,0) [0|1] "" IPC,IPC_INT,VCU
 SG_ PTORelAccelPedIndOn : 52|1@0+ (1,0) [0|1] "" IPC,IPC_INT,VCU
 SG_ PTORdcEngSpdIndOn : 53|1@0+ (1,0) [0|1] "" IPC,IPC_INT,VCU
 SG_ PTOPrssAndRelBrkPedIndOn : 54|1@0+ (1,0) [0|1] "" IPC,IPC_INT,VCU
 SG_ PTOModeCstSetAval : 55|1@0+ (1,0) [0|1] "" RadioLow,CSM,CSM_AV,VCU
 SG_ TrnsSkpShftIO : 57|1@0+ (1,0) [0|1] "" CSM,CSM_AV,IPC,IPC_INT,VCU
 SG_ ServFuelSysTrnsfrPmpIO : 58|1@0+ (1,0) [0|1] "" IPC,IPC_INT,VCU
 SG_ PTWrmgWtToShftIO : 59|1@0+ (1,0) [0|1] "" CSM,CSM_AV,VCU
 SG_ PTOTransInGrIndOn : 60|1@0+ (1,0) [0|1] "" IPC,IPC_INT,VCU
 SG_ PTOTpStpSpdCstSetAval : 61|1@0+ (1,0) [0|1] "" RadioLow,CSM,CSM_AV,VCU
 SG_ PTOStndbySpdCstSetAval : 62|1@0+ (1,0) [0|1] "" RadioLow,CSM,CSM_AV,VCU
 SG_ PTOSetPrkBrkIndOn : 63|1@0+ (1,0) [0|1] "" IPC,IPC_INT,VCU

BO_ 1187 PDU_2107: 6 CGM
 SG_ OTARC_RejCrdntnECP_X1 : 0|1@0+ (1,0) [0|1] "" HVAC_FP_F
 SG_ OTARC_RejCrdntnECP_S : 1|1@0+ (1,0) [0|1] "" HVAC_FP_F
 SG_ OTARC_RejCrdntnECP_MC : 2|1@0+ (1,0) [0|1] "" HVAC_FP_F
 SG_ OTARC_RejCrdntnECM : 3|1@0+ (1,0) [0|1] "" HVAC_FP_F
 SG_ OTARC_RejCrdntnEBCM : 4|1@0+ (1,0) [0|1] "" HVAC_FP_F
 SG_ OTARC_RejCrdntnBSM_MH : 5|1@0+ (1,0) [0|1] "" HVAC_FP_F
 SG_ OTARC_RejCrdntnBSM : 6|1@0+ (1,0) [0|1] "" HVAC_FP_F
 SG_ OTARC_RejCrdntnBCM : 7|1@0+ (1,0) [0|1] "" HVAC_FP_F
 SG_ OTARC_RejCrdntnLIB_48V : 8|1@0+ (1,0) [0|1] "" HVAC_FP_F
 SG_ OTARC_RejCrdntnECP_E : 9|1@0+ (1,0) [0|1] "" HVAC_FP_F
 SG_ OTARC_RejCrdntnVECM : 10|1@0+ (1,0) [0|1] "" HVAC_FP_F
 SG_ OTARC_RejCrdntnECP_S2 : 11|1@0+ (1,0) [0|1] "" HVAC_FP_F
 SG_ OTARC_RejCrdntnVICM : 12|1@0+ (1,0) [0|1] "" HVAC_FP_F
 SG_ OTARC_RejCrdntnSBM : 13|1@0+ (1,0) [0|1] "" HVAC_FP_F
 SG_ OTARC_RejCrdntnCGM : 14|1@0+ (1,0) [0|1] "" HVAC_FP_F
 SG_ OTARC_RejCrdntnECP_X2 : 15|1@0+ (1,0) [0|1] "" HVAC_FP_F
 SG_ OTARC_RejCrdntnECU_27 : 16|1@0+ (1,0) [0|1] "" HVAC_FP_F
 SG_ OTARC_RejCrdntnECU_26 : 17|1@0+ (1,0) [0|1] "" HVAC_FP_F
 SG_ OTARC_RejCrdntnECU_25 : 18|1@0+ (1,0) [0|1] "" HVAC_FP_F
 SG_ OTARC_RejCrdntnECU_24 : 19|1@0+ (1,0) [0|1] "" HVAC_FP_F
 SG_ OTARC_RejCrdntnECU_23 : 20|1@0+ (1,0) [0|1] "" HVAC_FP_F
 SG_ OTARC_RejCrdntnECU_22 : 21|1@0+ (1,0) [0|1] "" HVAC_FP_F
 SG_ OTARC_RejCrdntnECU_21 : 22|1@0+ (1,0) [0|1] "" HVAC_FP_F
 SG_ OTARC_RejCrdntnECU_20 : 23|1@0+ (1,0) [0|1] "" HVAC_FP_F
 SG_ OTARC_RejCrdntnTCM : 24|1@0+ (1,0) [0|1] "" HVAC_FP_F
 SG_ OTARC_RejCrdntnICCM : 25|1@0+ (1,0) [0|1] "" HVAC_FP_F
 SG_ OTARC_RejCrdntnFICM : 26|1@0+ (1,0) [0|1] "" HVAC_FP_F
 SG_ OTARC_RejCrdntnECU_32 : 27|1@0+ (1,0) [0|1] "" HVAC_FP_F
 SG_ OTARC_RejCrdntnECU_31 : 28|1@0+ (1,0) [0|1] "" HVAC_FP_F
 SG_ OTARC_RejCrdntnECU_30 : 29|1@0+ (1,0) [0|1] "" HVAC_FP_F
 SG_ OTARC_RejCrdntnECU_29 : 30|1@0+ (1,0) [0|1] "" HVAC_FP_F
 SG_ OTARC_RejCrdntnECU_28 : 31|1@0+ (1,0) [0|1] "" HVAC_FP_F

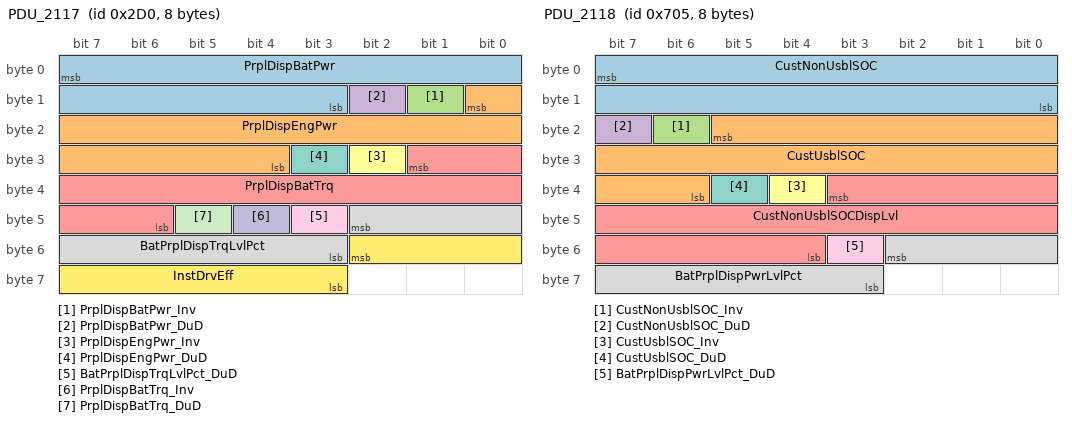
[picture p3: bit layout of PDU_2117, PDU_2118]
BO_ 720 PDU_2117: 8 CGM
 SG_ PrplDispBatPwr : 7|13@0+ (0.5,-1000) [-1000|3095.5] "" PDR,CSM,CSM_AV,IPC,IPC_INT,VCU
 SG_ PrplDispEngPwr : 8|13@0+ (0.5,-325) [-325|3770.5] "" PDR,CSM,CSM_AV,VCU
 SG_ PrplDispBatPwr_Inv : 9|1@0+ (1,0) [0|1] "" CSM,CSM_AV,IPC,IPC_INT,VCU
 SG_ PrplDispBatPwr_DuD : 10|1@0+ (1,0) [0|1] "" CSM,CSM_AV,IPC,IPC_INT,VCU
 SG_ PrplDispBatTrq : 25|12@0+ (0.5,-848) [-848|1199.5] "Nm" PDR,CSM,CSM_AV,VCU
 SG_ PrplDispEngPwr_Inv : 26|1@0+ (1,0) [0|1] "" CSM,CSM_AV,VCU
 SG_ PrplDispEngPwr_DuD : 27|1@0+ (1,0) [0|1] "" CSM,CSM_AV,VCU
 SG_ BatPrplDispTrqLvlPct : 42|8@0- (1,0) [-128|127] "%" CSM,CSM_AV,VCU
 SG_ BatPrplDispTrqLvlPct_DuD : 43|1@0+ (1,0) [0|1] "" CSM,CSM_AV,VCU
 SG_ PrplDispBatTrq_Inv : 44|1@0+ (1,0) [0|1] "" CSM,CSM_AV,VCU
 SG_ PrplDispBatTrq_DuD : 45|1@0+ (1,0) [0|1] "" CSM,CSM_AV,VCU
 SG_ InstDrvEff : 50|8@0- (0.78125,0) [-100|99.2188] "%" CSM,CSM_AV,IPC,IPC_INT,VCU

BO_ 1797 PDU_2118: 8 CGM
 SG_ CustNonUsblSOC : 7|16@0+ (0.00152588,0) [0|99.9985] "%" CSM,CSM_AV,IPC,IPC_INT,VCU
 SG_ CustUsblSOC : 21|16@0+ (0.00152588,0) [0|99.9985] "%" FPI,PDR,RSI,TCP,CSM,CSM_AV,IPC,IPC_INT,VCU
 SG_ CustNonUsblSOC_Inv : 22|1@0+ (1,0) [0|1] "" CSM,CSM_AV,IPC,IPC_INT,VCU
 SG_ CustNonUsblSOC_DuD : 23|1@0+ (1,0) [0|1] "" CSM,CSM_AV,IPC,IPC_INT,VCU
 SG_ CustNonUsblSOCDispLvl : 35|16@0+ (0.00152588,0) [0|99.9985] "%" IPC,IPC_INT,VCU
 SG_ CustUsblSOC_Inv : 36|1@0+ (1,0) [0|1] "" FPI,RSI,CSM,CSM_AV,IPC,IPC_INT,VCU
 SG_ CustUsblSOC_DuD : 37|1@0+ (1,0) [0|1] "" FPI,PDR,RSI,CSM,CSM_AV,IPC,IPC_INT,VCU
 SG_ BatPrplDispPwrLvlPct : 50|8@0- (1,0) [-128|127] "%" PDR,CSM,CSM_AV,IPC,IPC_INT,VCU
 SG_ BatPrplDispPwrLvlPct_DuD : 51|1@0+ (1,0) [0|1] "" CSM,CSM_AV,IPC,IPC_INT,VCU

BO_ 1497 PDU_2119: 8 CGM
 SG_ EAWDMPTR_Secs : 0|6@0+ (1,0) [0|63] "seconds" CSM,CSM_AV,VCU
 SG_ EAWDMPTR_Mins : 7|7@0+ (1,0) [0|127] "minutes" CSM,CSM_AV,VCU
 SG_ ElecMtrATach : 10|9@0- (100,0) [-25600|25500] "rpm" CSM,CSM_AV,VCU
 SG_ ElecMtrATach_Inv : 16|1@0+ (1,0) [0|1] "" CSM,CSM_AV,VCU
 SG_ ElecMtrATach_DuD : 17|1@0+ (1,0) [0|1] "" CSM,CSM_AV,VCU
 SG_ HiVltgBatAvgTemp_DuD : 24|1@0+ (1,0) [0|1] "" CSM,CSM_AV,IPC,IPC_INT,VCU
 SG_ HiVltgBatAvgTemp : 31|7@0+ (1,-40) [-40|87] "deg C" PDR,TCP,CSM,CSM_AV,IPC,IPC_INT,VCU
 SG_ DischrgPwrLtdDispPct : 38|8@0- (1,0) [-128|127] "%" IPC,IPC_INT,VCU
 SG_ HiVltgBatAvgTemp_Inv : 39|1@0+ (1,0) [0|1] "" PDR,CSM,CSM_AV,IPC,IPC_INT,VCU
 SG_ EngPrplDispPwrLvlPct : 45|7@0+ (1,0) [0|127] "%" PDR,CSM,CSM_AV,IPC,IPC_INT,VCU
 SG_ EngPrplDispPwrLvlPct_DuD : 46|1@0+ (1,0) [0|1] "" CSM,CSM_AV,VCU
 SG_ EstdEleclPrplCpblty : 54|7@0+ (1,0) [0|127] "%" CSM,CSM_AV,IPC,IPC_INT,VCU
 SG_ EngRnngDueToVehSpdIndOn : 58|1@0+ (1,0) [0|1] "" IPC,IPC_INT,VCU
 SG_ ElecAllWhlDrvIndOn : 59|1@0+ (1,0) [0|1] "" PDR,IPC,IPC_INT,VCU
 SG_ DischrgPwrLtdIndOn : 60|1@0+ (1,0) [0|1] "" IPC,IPC_INT,VCU
 SG_ DischrgPwrLtdDispPctVsbl : 61|1@0+ (1,0) [0|1] "" IPC,IPC_INT,VCU
 SG_ HiVltgBatLmtnDueToTempInd : 63|2@0+ (1,0) [0|2] "" IPC,IPC_INT,VCU

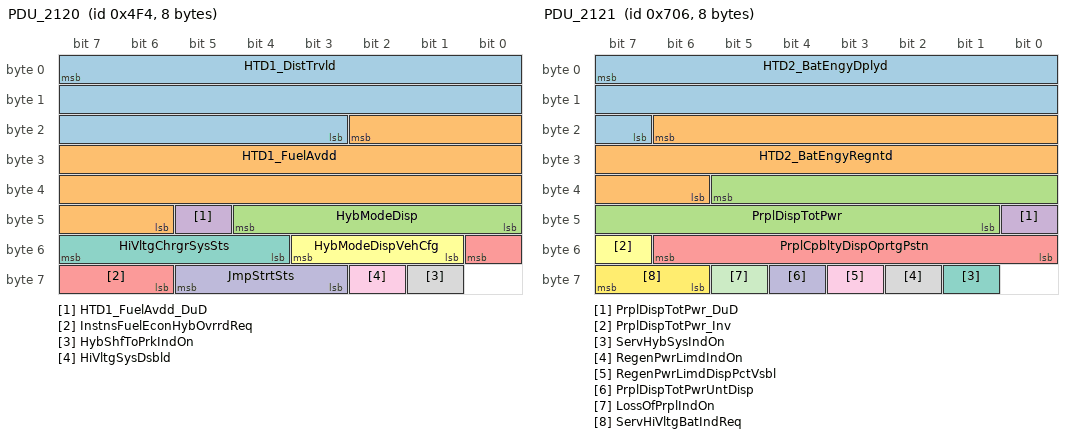
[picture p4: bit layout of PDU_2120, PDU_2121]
BO_ 1268 PDU_2120: 8 CGM
 SG_ HTD1_DistTrvld : 7|21@0+ (0.1,0) [0|209715] "Km" CSM,CSM_AV,VCU
 SG_ HTD1_FuelAvdd : 18|21@0+ (0.0378541,0) [0|79385.8] "liters" CSM,CSM_AV,VCU
 SG_ HybModeDisp : 44|5@0+ (1,0) [0|16] "" CSM,CSM_AV,VCU
 SG_ HTD1_FuelAvdd_DuD : 45|1@0+ (1,0) [0|1] "" CSM,CSM_AV,VCU
 SG_ InstnsFuelEconHybOvrrdReq : 48|3@0+ (1,0) [0|4] "" IPC,IPC_INT,VCU
 SG_ HybModeDispVehCfg : 51|3@0+ (1,0) [0|4] "" CSM,CSM_AV,VCU
 SG_ HiVltgChrgrSysSts : 55|4@0+ (1,0) [0|11] "" FPI,RSI,TCP,VKM,CSM,CSM_AV,IPC,IPC_INT,VCU
 SG_ HybShfToPrkIndOn : 57|1@0+ (1,0) [0|1] "" IPC,IPC_INT,VCU
 SG_ HiVltgSysDsbld : 58|1@0+ (1,0) [0|1] "" TCP
 SG_ JmpStrtSts : 61|3@0+ (1,0) [0|4] "" IPC,IPC_INT,VCU

BO_ 1798 PDU_2121: 8 CGM
 SG_ HTD2_BatEngyDplyd : 7|17@0+ (0.1,0) [0|13107.1] "kWh" CSM,CSM_AV,VCU
 SG_ HTD2_BatEngyRegntd : 22|17@0+ (0.1,0) [0|13107.1] "kWh" CSM,CSM_AV,VCU
 SG_ PrplDispTotPwr : 37|13@0+ (0.5,-1000) [-1000|3095.5] "" PDR,CSM,CSM_AV,IPC,IPC_INT,VCU
 SG_ PrplDispTotPwr_DuD : 40|1@0+ (1,0) [0|1] "" IPC,IPC_INT,VCU
 SG_ PrplCpbltyDispOprtgPstn : 54|7@0+ (1,0) [0|127] "%" CSM,CSM_AV,IPC,IPC_INT,VCU
 SG_ PrplDispTotPwr_Inv : 55|1@0+ (1,0) [0|1] "" IPC,IPC_INT,VCU
 SG_ ServHybSysIndOn : 57|1@0+ (1,0) [0|1] "" IPC,IPC_INT,VCU
 SG_ RegenPwrLimdIndOn : 58|1@0+ (1,0) [0|1] "" PDR,IPC,IPC_INT,VCU
 SG_ RegenPwrLimdDispPctVsbl : 59|1@0+ (1,0) [0|1] "" PDR,IPC,IPC_INT,VCU
 SG_ PrplDispTotPwrUntDisp : 60|1@0+ (1,0) [0|1] "" PDR,CSM,CSM_AV,IPC,IPC_INT,VCU
 SG_ LossOfPrplIndOn : 61|1@0+ (1,0) [0|1] "" IPC,IPC_INT,VCU
 SG_ ServHiVltgBatIndReq : 63|2@0+ (1,0) [0|2] "" IPC,IPC_INT,VCU

BO_ 1267 PDU_2124: 8 CGM
 SG_ BrkPadLifeFrtDistRmn : 7|8@0+ (100,0) [0|25500] "counts" CSM,CSM_AV,IPC,IPC_INT,VCU
 SG_ BrkPadLifeRrDistRmn : 13|8@0+ (100,0) [0|25500] "counts" CSM,CSM_AV,IPC,IPC_INT,VCU
 SG_ BrkPadLifeFrtDistWrnIndReq : 15|2@0+ (1,0) [0|2] "" IPC,IPC_INT,VCU
 SG_ ESCSpdLtdCntdwnVal : 16|6@0+ (1,0) [0|63] "Trips" IPC,IPC_INT,VCU
 SG_ BrkPadLifeStsIndReq : 19|3@0+ (1,0) [0|6] "" PDR,TCP,CSM,CSM_AV,IPC,IPC_INT,VCU
 SG_ BrkPadLifeRrDistWrnIndReq : 21|2@0+ (1,0) [0|2] "" IPC,IPC_INT,VCU
 SG_ ESCVehTopSpdLimDispVal : 24|7@0+ (1,0) [0|127] "kph" IPC,IPC_INT,VCU
 SG_ ESCSpdLtdIndReq : 26|2@0+ (1,0) [0|2] "" IPC,IPC_INT,VCU
 SG_ HillDscntCtlRdcVehSpdIndOn : 32|1@0+ (1,0) [0|1] "" IPC,IPC_INT,VCU
 SG_ HillDscntCtlDispActvIndOn : 33|1@0+ (1,0) [0|1] "" IPC,IPC_INT,VCU
 SG_ HillDscntCtlTgtSetSpd : 47|10@0+ (0.1,0) [0|102.3] "km/h" IPC,IPC_INT,VCU
 SG_ BrkPadLifeFrtCnfrmRplcmtIndOn : 48|1@0+ (1,0) [0|1] "" IPC,IPC_INT,VCU
 SG_ BrkOvrhtdIndOn : 49|1@0+ (1,0) [0|1] "" IPC,IPC_INT,VCU
 SG_ AllWhlDrvRcmndIndOn : 50|1@0+ (1,0) [0|1] "" IPC,IPC_INT,VCU
 SG_ CrwlModeDndRsnIndReq : 53|3@0+ (1,0) [0|4] "" IPC,IPC_INT,VCU
 SG_ BrksOvrht : 59|1@0+ (1,0) [0|1] "" TCP,CSM,CSM_AV,VCU
 SG_ BrkSysTwoFtdDrvDtdIndOn : 60|1@0+ (1,0) [0|1] "" IPC,IPC_INT,VCU
 SG_ BrkSysHillStrtAsstAvl : 61|1@0+ (1,0) [0|1] "" CSM,CSM_AV,VCU
 SG_ BrkPadWrnIO : 62|1@0+ (1,0) [0|1] "" TCP,CSM,CSM_AV,IPC,IPC_INT,VCU
 SG_ BrkPadLifeRrCnfrmRplcmtIndOn : 63|1@0+ (1,0) [0|1] "" IPC,IPC_INT,VCU

BO_ 1799 PDU_2125: 8 CGM
 SG_ LnchCtlWhlSlSts : 1|5@0+ (1,0) [0|21] "" IPC,IPC_INT,VCU
 SG_ LnchCtlEngRPMSts : 7|6@0+ (1,0) [0|38] "" IPC,IPC_INT,VCU
 SG_ LnchCtlBrkPresVal : 8|4@0+ (10,0) [0|150] "%" IPC,IPC_INT,VCU
 SG_ DrvModeVisScreenSts : 12|4@0+ (1,0) [0|13] "" RadioLow,CSM,CSM_AV,VCU
 SG_ EngSndPerfModeReq : 16|3@0+ (1,0) [0|7] "" AMP,VCU
 SG_ LnchCtlLineLckTmrVal : 20|4@0+ (1,0) [0|15] "sec" IPC,IPC_INT,VCU
 SG_ PerfTracMgmtMode : 26|3@0+ (1,0) [0|7] "" PDR,IPC,IPC_INT,VCU
 SG_ HillDscntCtlSysSts : 29|3@0+ (1,0) [0|4] "" CSM,CSM_AV,IPC,IPC_INT,VCU
 SG_ SprtModeDrvlineVisDispVal : 33|3@0+ (1,0) [0|7] "" RadioLow,CSM,CSM_AV,VCU
 SG_ SprtModeBrkPedVisDispVal : 36|3@0+ (1,0) [0|7] "" RadioLow,CSM,CSM_AV,VCU
 SG_ SprtModeActvAeroVisDispVal : 39|3@0+ (1,0) [0|7] "" RadioLow,CSM,CSM_AV,VCU
 SG_ SprtModeRideHghtVisDispVal : 40|3@0+ (1,0) [0|7] "" RadioLow,CSM,CSM_AV,VCU
 SG_ SprtModePwrtrnVisDispVal : 43|3@0+ (1,0) [0|7] "" RadioLow,CSM,CSM_AV,VCU
 SG_ SprtModeESCVisDispVal : 46|3@0+ (1,0) [0|7] "" RadioLow,CSM,CSM_AV,VCU
 SG_ SprtModeSpnsnVisDispVal : 50|3@0+ (1,0) [0|7] "" RadioLow,CSM,CSM_AV,VCU
 SG_ SprtModeSndVisDispVal : 53|3@0+ (1,0) [0|7] "" RadioLow,CSM,CSM_AV,VCU
 SG_ ShfToPrkBfrExtIndOn : 56|1@0+ (1,0) [0|1] "" IPC,IPC_INT,VCU
 SG_ HillDscntCtlVirtSwAvl : 57|1@0+ (1,0) [0|1] "" VCU
 SG_ WthrSnwModeStrgVisDispVal : 60|3@0+ (1,0) [0|7] "" RadioLow,CSM,CSM_AV,VCU
 SG_ SprtModeStrgVisDispVal : 63|3@0+ (1,0) [0|7] "" RadioLow,CSM,CSM_AV,VCU

BO_ 1266 PDU_2126: 8 CGM
 SG_ TkModeBrkPedVisDispVal : 1|3@0+ (1,0) [0|7] "" RadioLow,CSM,CSM_AV,VCU
 SG_ TkModeActvAeroVisDispVal : 4|3@0+ (1,0) [0|7] "" RadioLow,CSM,CSM_AV,VCU
 SG_ TireTrdTempSts : 7|3@0+ (1,0) [0|5] "" VKM,CSM,CSM_AV,IPC,IPC_INT,VCU
 SG_ TkModePwrtrnVisDispVal : 8|3@0+ (1,0) [0|7] "" RadioLow,CSM,CSM_AV,VCU
 SG_ TkModeESCVisDispVal : 11|3@0+ (1,0) [0|7] "" RadioLow,CSM,CSM_AV,VCU
 SG_ TkModeDrvlineVisDispVal : 14|3@0+ (1,0) [0|7] "" RadioLow,CSM,CSM_AV,VCU
 SG_ TkModeSndVisDispVal : 18|3@0+ (1,0) [0|7] "" RadioLow,CSM,CSM_AV,VCU
 SG_ TkModeRideHghtVisDispVal : 21|3@0+ (1,0) [0|7] "" RadioLow,CSM,CSM_AV,VCU
 SG_ TourModeActvAeroVisDispVal : 25|3@0+ (1,0) [0|7] "" RadioLow,CSM,CSM_AV,VCU
 SG_ TkModeStrgVisDispVal : 28|3@0+ (1,0) [0|7] "" RadioLow,CSM,CSM_AV,VCU
 SG_ TkModeSpnsnVisDispVal : 31|3@0+ (1,0) [0|7] "" RadioLow,CSM,CSM_AV,VCU
 SG_ TourModeESCVisDispVal : 32|3@0+ (1,0) [0|7] "" RadioLow,CSM,CSM_AV,VCU
 SG_ TourModeDrvlineVisDispVal : 35|3@0+ (1,0) [0|7] "" RadioLow,CSM,CSM_AV,VCU
 SG_ TourModeBrkPedVisDispVal : 38|3@0+ (1,0) [0|7] "" RadioLow,CSM,CSM_AV,VCU
 SG_ TourModeRideHghtVisDispVal : 42|3@0+ (1,0) [0|7] "" RadioLow,CSM,CSM_AV,VCU
 SG_ TourModePwrtrnVisDispVal : 45|3@0+ (1,0) [0|7] "" RadioLow,CSM,CSM_AV,VCU
 SG_ TourModeStrgVisDispVal : 49|3@0+ (1,0) [0|7] "" RadioLow,CSM,CSM_AV,VCU
 SG_ TourModeSpnsnVisDispVal : 52|3@0+ (1,0) [0|7] "" RadioLow,CSM,CSM_AV,VCU
 SG_ TourModeSndVisDispVal : 55|3@0+ (1,0) [0|7] "" RadioLow,CSM,CSM_AV,VCU
 SG_ TrlrStbAsstActIO : 56|1@0+ (1,0) [0|1] "" IPC,IPC_INT,VCU
 SG_ TrcCntrlOnIO : 57|1@0+ (1,0) [0|1] "" TCP,CSM,CSM_AV,IPC,IPC_INT,VCU
 SG_ TrcCntrlOffIO : 58|1@0+ (1,0) [0|1] "" TCP,CSM,CSM_AV,IPC,IPC_INT,VCU
 SG_ TnDrvTrCtrlOffUnvIndOn : 59|1@0+ (1,0) [0|1] "" IPC,IPC_INT,VCU
 SG_ SrBkLwBkFlDrVisMsgRqOn : 60|1@0+ (1,0) [0|1] "" TCP,IPC,IPC_INT,VCU
 SG_ TrcStbScrConfig : 62|2@0+ (1,0) [0|3] "" IPC,IPC_INT,VCU

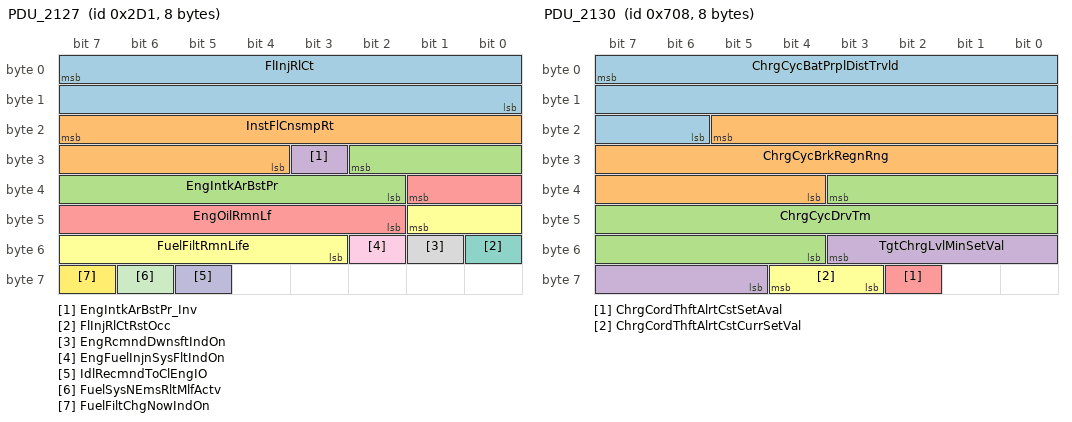
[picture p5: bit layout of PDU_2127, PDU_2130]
BO_ 721 PDU_2127: 8 CGM
 SG_ FlInjRlCt : 7|16@0+ (3.05176e-05,0) [0|1.99997] "liters" TCP,CSM,CSM_AV,IPC,IPC_INT,VCU
 SG_ InstFlCnsmpRt : 23|12@0+ (0.025,0) [0|102.375] "ltrs/hr" CSM,CSM_AV,IPC,IPC_INT,VCU
 SG_ EngIntkArBstPr : 26|9@0+ (1,-110) [-110|401] "kPa" PDR,CSM,CSM_AV,IPC,IPC_INT,VCU
 SG_ EngIntkArBstPr_Inv : 27|1@0+ (1,0) [0|1] "" PDR,CSM,CSM_AV,IPC,IPC_INT,VCU
 SG_ EngOilRmnLf : 33|8@0+ (0.392157,0) [0|100] "%" RadioLow,TCP,VKM,CSM,CSM_AV,IPC,IPC_INT,VCU
 SG_ FuelFiltRmnLife : 41|7@0+ (1,0) [0|127] "%" CSM,CSM_AV,IPC,IPC_INT,VCU
 SG_ FlInjRlCtRstOcc : 48|1@0+ (1,0) [0|1] "" TCP,CSM,CSM_AV,IPC,IPC_INT,VCU
 SG_ EngRcmndDwnsftIndOn : 49|1@0+ (1,0) [0|1] "" IPC,IPC_INT,VCU
 SG_ EngFuelInjnSysFltIndOn : 50|1@0+ (1,0) [0|1] "" IPC,IPC_INT,VCU
 SG_ IdlRecmndToClEngIO : 61|1@0+ (1,0) [0|1] "" IPC,IPC_INT,VCU
 SG_ FuelSysNEmsRltMlfActv : 62|1@0+ (1,0) [0|1] "" IPC,IPC_INT,VCU
 SG_ FuelFiltChgNowIndOn : 63|1@0+ (1,0) [0|1] "" IPC,IPC_INT,VCU

BO_ 1800 PDU_2130: 8 CGM
 SG_ ChrgCycBatPrplDistTrvld : 7|18@0+ (0.1,0) [0|26214.3] "km" CSM,CSM_AV,IPC,IPC_INT,VCU
 SG_ ChrgCycBrkRegnRng : 21|18@0+ (0.1,0) [0|26214.3] "km" CSM,CSM_AV,IPC,IPC_INT,VCU
 SG_ ChrgCycDrvTm : 35|16@0+ (1,0) [0|65535] "min" CSM,CSM_AV,IPC,IPC_INT,VCU
 SG_ TgtChrgLvlMinSetVal : 51|7@0+ (1,0) [0|127] "%" CSM,CSM_AV,VCU
 SG_ ChrgCordThftAlrtCstSetAval : 58|1@0+ (1,0) [0|1] "" CSM,CSM_AV,VCU
 SG_ ChrgCordThftAlrtCstCurrSetVal : 60|2@0+ (1,0) [0|2] "" CSM,CSM_AV,VCU

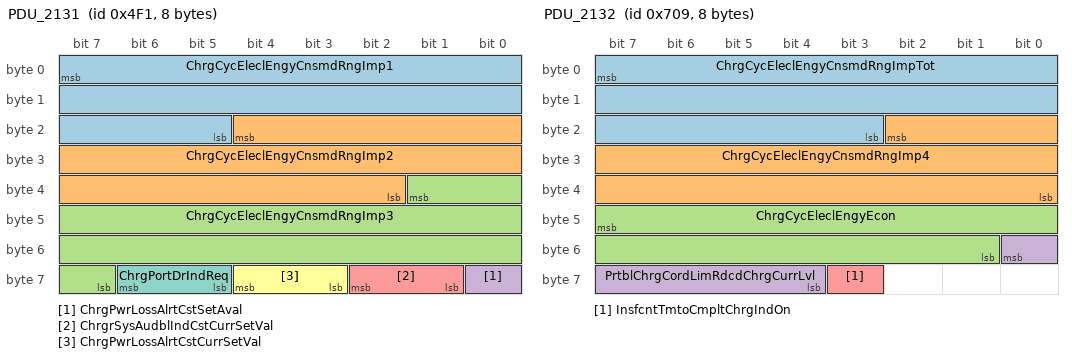
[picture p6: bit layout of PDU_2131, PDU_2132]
BO_ 1265 PDU_2131: 8 CGM
 SG_ ChrgCycEleclEngyCnsmdRngImp1 : 7|19@0- (0.1,0) [-26214.4|26214.3] "km" CSM,CSM_AV,IPC,IPC_INT,VCU
 SG_ ChrgCycEleclEngyCnsmdRngImp2 : 20|19@0- (0.1,0) [-26214.4|26214.3] "km" CSM,CSM_AV,IPC,IPC_INT,VCU
 SG_ ChrgCycEleclEngyCnsmdRngImp3 : 33|19@0- (0.1,0) [-26214.4|26214.3] "km" CSM,CSM_AV,IPC,IPC_INT,VCU
 SG_ ChrgPwrLossAlrtCstSetAval : 56|1@0+ (1,0) [0|1] "" CSM,CSM_AV,VCU
 SG_ ChrgrSysAudblIndCstCurrSetVal : 58|2@0+ (1,0) [0|2] "" CSM,CSM_AV,VCU
 SG_ ChrgPwrLossAlrtCstCurrSetVal : 60|2@0+ (1,0) [0|2] "" CSM,CSM_AV,VCU
 SG_ ChrgPortDrIndReq : 62|2@0+ (1,0) [0|3] "" TCP,IPC,IPC_INT,VCU

BO_ 1801 PDU_2132: 8 CGM
 SG_ ChrgCycEleclEngyCnsmdRngImpTot : 7|21@0- (0.1,0) [-104858|104858] "km" CSM,CSM_AV,IPC,IPC_INT,VCU
 SG_ ChrgCycEleclEngyCnsmdRngImp4 : 18|19@0- (0.1,0) [-26214.4|26214.3] "km" CSM,CSM_AV,IPC,IPC_INT,VCU
 SG_ ChrgCycEleclEngyEcon : 47|15@0- (0.1,0) [-1638.4|1638.3] "" CSM,CSM_AV,IPC,IPC_INT,VCU
 SG_ PrtblChrgCordLimRdcdChrgCurrLvl : 48|5@0+ (1,0) [0|31] "A" CSM,CSM_AV,VCU
 SG_ InsfcntTmtoCmpltChrgIndOn : 59|1@0+ (1,0) [0|1] "" CSM,CSM_AV,VCU

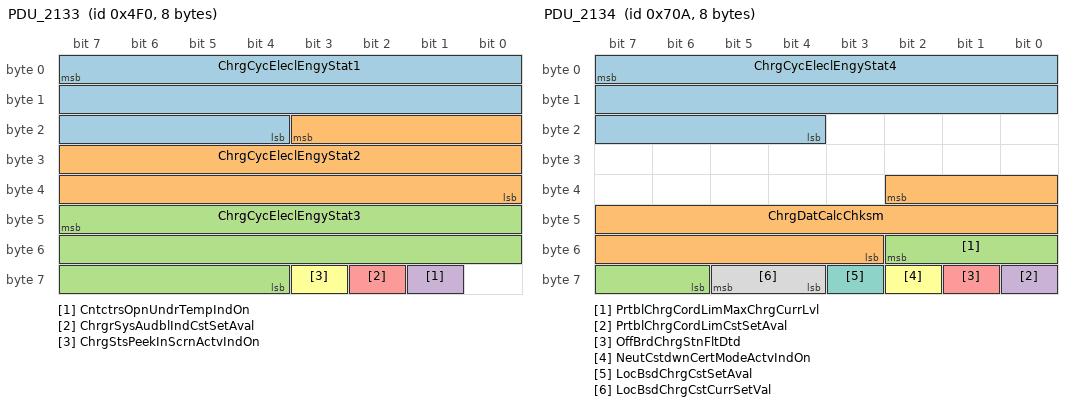
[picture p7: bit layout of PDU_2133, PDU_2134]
BO_ 1264 PDU_2133: 8 CGM
 SG_ ChrgCycEleclEngyStat1 : 7|20@0+ (0.01,0) [0|10485.8] "kWh" CSM,CSM_AV,VCU
 SG_ ChrgCycEleclEngyStat2 : 19|20@0+ (0.01,0) [0|10485.8] "kWh" CSM,CSM_AV,VCU
 SG_ ChrgCycEleclEngyStat3 : 47|20@0+ (0.01,0) [0|10485.8] "kWh" CSM,CSM_AV,VCU
 SG_ CntctrsOpnUndrTempIndOn : 57|1@0+ (1,0) [0|1] "" IPC,IPC_INT,VCU
 SG_ ChrgrSysAudblIndCstSetAval : 58|1@0+ (1,0) [0|1] "" CSM,CSM_AV,VCU
 SG_ ChrgStsPeekInScrnActvIndOn : 59|1@0+ (1,0) [0|1] "" IPC,IPC_INT,VCU

BO_ 1802 PDU_2134: 8 CGM
 SG_ ChrgCycEleclEngyStat4 : 7|20@0+ (0.01,0) [0|10485.8] "kWh" CSM,CSM_AV,VCU
 SG_ ChrgDatCalcChksm : 34|16@0+ (1,0) [0|65535] "" CSM,CSM_AV,VCU
 SG_ PrtblChrgCordLimMaxChrgCurrLvl : 50|5@0+ (1,0) [0|31] "A" CSM,CSM_AV,VCU
 SG_ PrtblChrgCordLimCstSetAval : 56|1@0+ (1,0) [0|1] "" CSM,CSM_AV,VCU
 SG_ OffBrdChrgStnFltDtd : 57|1@0+ (1,0) [0|1] "" IPC,IPC_INT,VCU
 SG_ NeutCstdwnCertModeActvIndOn : 58|1@0+ (1,0) [0|1] "" IPC,IPC_INT,VCU
 SG_ LocBsdChrgCstSetAval : 59|1@0+ (1,0) [0|1] "" CSM,CSM_AV,VCU
 SG_ LocBsdChrgCstCurrSetVal : 61|2@0+ (1,0) [0|2] "" TCP,CSM,CSM_AV,VCU

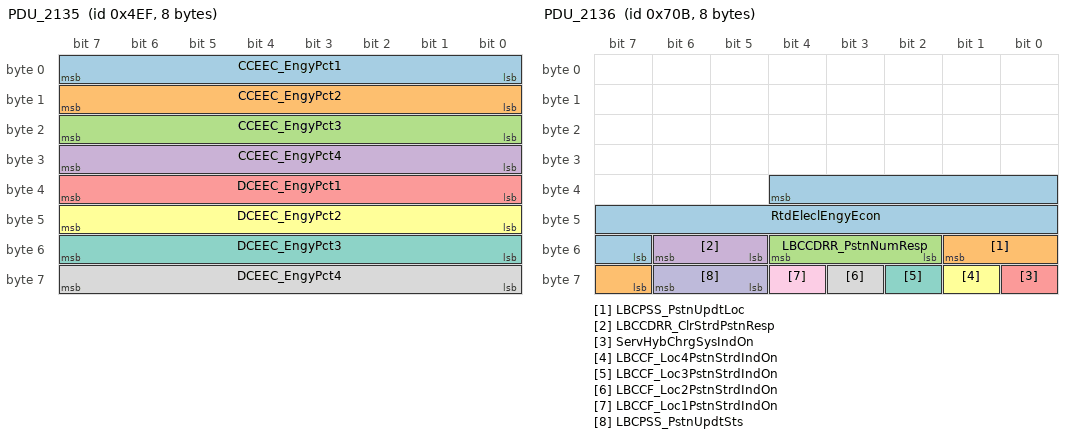
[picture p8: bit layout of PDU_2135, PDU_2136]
BO_ 1263 PDU_2135: 8 CGM
 SG_ CCEEC_EngyPct1 : 7|8@0+ (0.392157,0) [0|100] "%" CSM,CSM_AV,IPC,IPC_INT,VCU
 SG_ CCEEC_EngyPct2 : 15|8@0+ (0.392157,0) [0|100] "%" CSM,CSM_AV,IPC,IPC_INT,VCU
 SG_ CCEEC_EngyPct3 : 23|8@0+ (0.392157,0) [0|100] "%" CSM,CSM_AV,IPC,IPC_INT,VCU
 SG_ CCEEC_EngyPct4 : 31|8@0+ (0.392157,0) [0|100] "%" CSM,CSM_AV,IPC,IPC_INT,VCU
 SG_ DCEEC_EngyPct1 : 39|8@0+ (0.392157,0) [0|100] "%" FPI,RSI,CSM,CSM_AV,IPC,IPC_INT,VCU
 SG_ DCEEC_EngyPct2 : 47|8@0+ (0.392157,0) [0|100] "%" FPI,RSI,CSM,CSM_AV,IPC,IPC_INT,VCU
 SG_ DCEEC_EngyPct3 : 55|8@0+ (0.392157,0) [0|100] "%" CSM,CSM_AV,IPC,IPC_INT,VCU
 SG_ DCEEC_EngyPct4 : 63|8@0+ (0.392157,0) [0|100] "%" FPI,RSI,CSM,CSM_AV,IPC,IPC_INT,VCU

BO_ 1803 PDU_2136: 8 CGM
 SG_ RtdEleclEngyEcon : 36|14@0+ (0.1,0) [0|1638.3] "" CSM,CSM_AV,VCU
 SG_ LBCPSS_PstnUpdtLoc : 49|3@0+ (1,0) [0|4] "" CSM,CSM_AV,VCU
 SG_ LBCCDRR_PstnNumResp : 52|3@0+ (1,0) [0|4] "" CSM,CSM_AV,VCU
 SG_ LBCCDRR_ClrStrdPstnResp : 54|2@0+ (1,0) [0|2] "" CSM,CSM_AV,VCU
 SG_ ServHybChrgSysIndOn : 56|1@0+ (1,0) [0|1] "" IPC,IPC_INT,VCU
 SG_ LBCCF_Loc4PstnStrdIndOn : 57|1@0+ (1,0) [0|1] "" CSM,CSM_AV,VCU
 SG_ LBCCF_Loc3PstnStrdIndOn : 58|1@0+ (1,0) [0|1] "" CSM,CSM_AV,VCU
 SG_ LBCCF_Loc2PstnStrdIndOn : 59|1@0+ (1,0) [0|1] "" CSM,CSM_AV,VCU
 SG_ LBCCF_Loc1PstnStrdIndOn : 60|1@0+ (1,0) [0|1] "" CSM,CSM_AV,VCU
 SG_ LBCPSS_PstnUpdtSts : 62|2@0+ (1,0) [0|2] "" CSM,CSM_AV,VCU

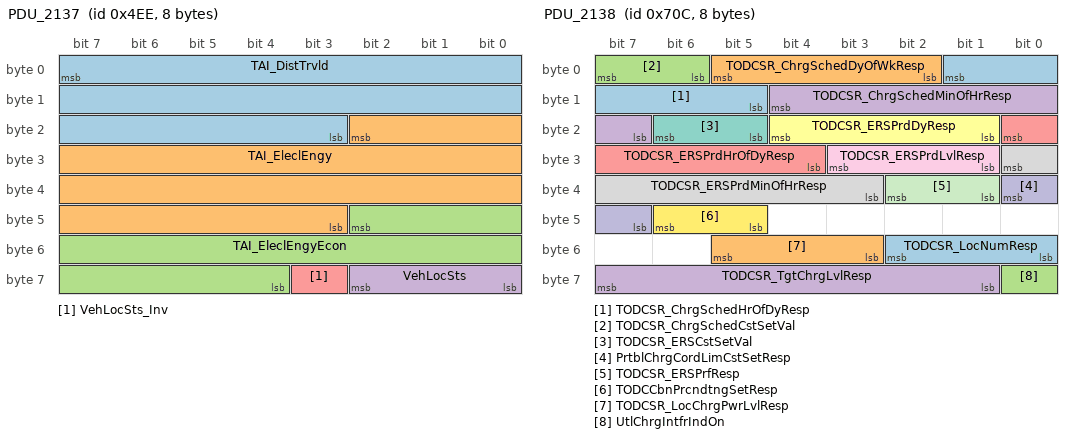
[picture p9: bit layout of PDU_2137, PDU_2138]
BO_ 1262 PDU_2137: 8 CGM
 SG_ TAI_DistTrvld : 7|21@0+ (0.1,0) [0|209715] "km" FPI,RSI,IPC,IPC_INT,VCU
 SG_ TAI_EleclEngy : 18|24@0+ (0.1,0) [0|1.67772e+006] "kWh" IPC,IPC_INT,VCU
 SG_ TAI_EleclEngyEcon : 42|15@0- (0.1,0) [-1638.4|1638.3] "" FPI,RSI,IPC,IPC_INT,VCU
 SG_ VehLocSts : 58|3@0+ (1,0) [0|4] "" TCP,CSM,CSM_AV,VCU
 SG_ VehLocSts_Inv : 59|1@0+ (1,0) [0|1] "" CSM,CSM_AV,VCU

BO_ 1804 PDU_2138: 8 CGM
 SG_ TODCSR_ChrgSchedHrOfDyResp : 1|5@0+ (1,0) [0|31] "h" CSM,CSM_AV,VCU
 SG_ TODCSR_ChrgSchedDyOfWkResp : 5|4@0+ (1,0) [0|10] "" CSM,CSM_AV,VCU
 SG_ TODCSR_ChrgSchedCstSetVal : 7|2@0+ (1,0) [0|2] "" CSM,CSM_AV,VCU
 SG_ TODCSR_ChrgSchedMinOfHrResp : 12|6@0+ (1,0) [0|63] "min" CSM,CSM_AV,VCU
 SG_ TODCSR_ERSPrdHrOfDyResp : 16|5@0+ (1,0) [0|31] "h" CSM,CSM_AV,VCU
 SG_ TODCSR_ERSPrdDyResp : 20|4@0+ (1,0) [0|10] "" CSM,CSM_AV,VCU
 SG_ TODCSR_ERSCstSetVal : 22|2@0+ (1,0) [0|2] "" CSM,CSM_AV,VCU
 SG_ TODCSR_ERSPrdMinOfHrResp : 24|6@0+ (1,0) [0|63] "min" CSM,CSM_AV,VCU
 SG_ TODCSR_ERSPrdLvlResp : 27|3@0+ (1,0) [0|5] "" CSM,CSM_AV,VCU
 SG_ PrtblChrgCordLimCstSetResp : 32|2@0+ (1,0) [0|2] "" CSM,CSM_AV,VCU
 SG_ TODCSR_ERSPrfResp : 34|2@0+ (1,0) [0|3] "" CSM,CSM_AV,VCU
 SG_ TODCCbnPrcndtngSetResp : 46|2@0+ (1,0) [0|2] "" CSM,CSM_AV,VCU
 SG_ TODCSR_LocNumResp : 50|3@0+ (1,0) [0|5] "" CSM,CSM_AV,VCU
 SG_ TODCSR_LocChrgPwrLvlResp : 53|3@0+ (1,0) [0|4] "" CSM,CSM_AV,VCU
 SG_ UtlChrgIntfrIndOn : 56|1@0+ (1,0) [0|1] "" IPC,IPC_INT,VCU
 SG_ TODCSR_TgtChrgLvlResp : 63|7@0+ (1,0) [0|127] "%" CSM,CSM_AV,VCU

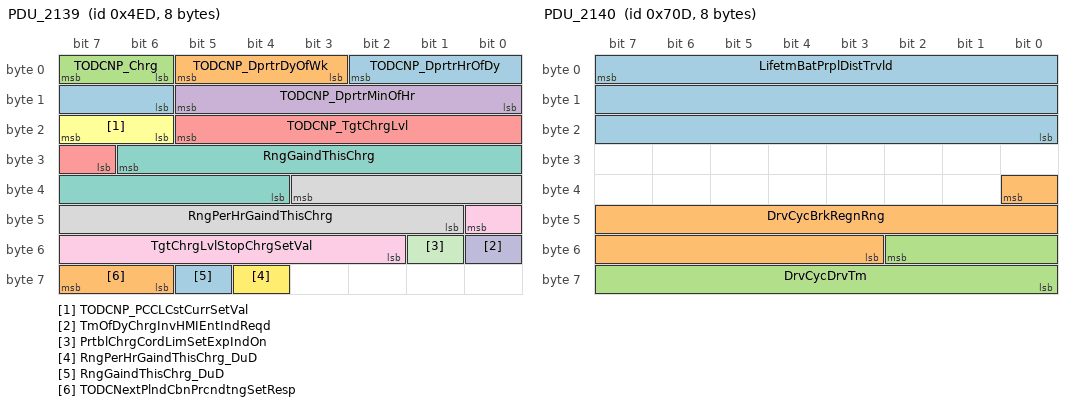
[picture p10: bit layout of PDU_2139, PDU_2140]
BO_ 1261 PDU_2139: 8 CGM
 SG_ TODCNP_DprtrHrOfDy : 2|5@0+ (1,0) [0|31] "h" CSM,CSM_AV,IPC,IPC_INT,VCU
 SG_ TODCNP_DprtrDyOfWk : 5|3@0+ (1,0) [0|7] "" CSM,CSM_AV,IPC,IPC_INT,VCU
 SG_ TODCNP_Chrg : 7|2@0+ (1,0) [0|3] "" TCP,CSM,CSM_AV,IPC,IPC_INT,VCU
 SG_ TODCNP_DprtrMinOfHr : 13|6@0+ (1,0) [0|63] "min" CSM,CSM_AV,IPC,IPC_INT,VCU
 SG_ TODCNP_TgtChrgLvl : 21|7@0+ (1,0) [0|127] "%" TCP,CSM,CSM_AV,IPC,IPC_INT,VCU
 SG_ TODCNP_PCCLCstCurrSetVal : 23|2@0+ (1,0) [0|2] "" TCP,CSM,CSM_AV,IPC,IPC_INT,VCU
 SG_ RngGaindThisChrg : 30|11@0+ (1,0) [0|2047] "km" CSM,CSM_AV,IPC,IPC_INT,VCU
 SG_ RngPerHrGaindThisChrg : 35|11@0+ (1,0) [0|2047] "km/h" CSM,CSM_AV,IPC,IPC_INT,VCU
 SG_ TgtChrgLvlStopChrgSetVal : 40|7@0+ (1,0) [0|127] "%" CSM,CSM_AV,VCU
 SG_ TmOfDyChrgInvHMIEntIndReqd : 48|1@0+ (1,0) [0|1] "" CSM,CSM_AV,VCU
 SG_ PrtblChrgCordLimSetExpIndOn : 49|1@0+ (1,0) [0|1] "" CSM,CSM_AV,VCU
 SG_ RngPerHrGaindThisChrg_DuD : 60|1@0+ (1,0) [0|1] "" CSM,CSM_AV,IPC,IPC_INT,VCU
 SG_ RngGaindThisChrg_DuD : 61|1@0+ (1,0) [0|1] "" CSM,CSM_AV,IPC,IPC_INT,VCU
 SG_ TODCNextPlndCbnPrcndtngSetResp : 63|2@0+ (1,0) [0|2] "" CSM,CSM_AV,VCU

BO_ 1805 PDU_2140: 8 CGM
 SG_ LifetmBatPrplDistTrvld : 7|24@0+ (0.1,0) [0|1.67772e+006] "km" CSM,CSM_AV,VCU
 SG_ DrvCycBrkRegnRng : 32|14@0+ (0.1,0) [0|1638.3] "km" CSM,CSM_AV,IPC,IPC_INT,VCU
 SG_ DrvCycDrvTm : 50|11@0+ (1,0) [0|2047] "min" CSM,CSM_AV,IPC,IPC_INT,VCU

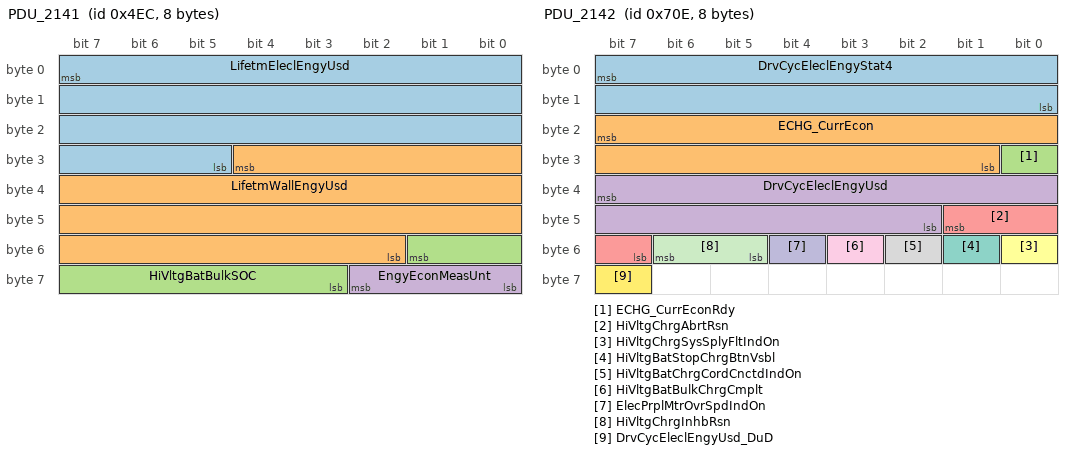
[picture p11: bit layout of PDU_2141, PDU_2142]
BO_ 1260 PDU_2141: 8 CGM
 SG_ LifetmEleclEngyUsd : 7|27@0+ (0.1,0) [0|1.34218e+007] "kWh" CSM,CSM_AV,VCU
 SG_ LifetmWallEngyUsd : 28|27@0+ (0.1,0) [0|1.34218e+007] "kWh" TCP,CSM,CSM_AV,VCU
 SG_ HiVltgBatBulkSOC : 49|7@0+ (1,0) [0|127] "%" CSM,CSM_AV,IPC,IPC_INT,VCU
 SG_ EngyEconMeasUnt : 58|3@0+ (1,0) [0|5] "" FPI,RSI,TCP,CSM,CSM_AV,IPC,IPC_INT,VCU

BO_ 1806 PDU_2142: 8 CGM
 SG_ DrvCycEleclEngyStat4 : 7|16@0+ (0.01,0) [0|655.35] "kWh" FPI,RSI,CSM,CSM_AV,VCU
 SG_ ECHG_CurrEcon : 23|15@0- (0.1,0) [-1638.4|1638.3] "" CSM,CSM_AV,VCU
 SG_ ECHG_CurrEconRdy : 24|1@0+ (1,0) [0|1] "" CSM,CSM_AV,VCU
 SG_ DrvCycEleclEngyUsd : 39|14@0+ (0.1,0) [0|1638.3] "kWh" FPI,RSI,CSM,CSM_AV,IPC,IPC_INT,VCU
 SG_ HiVltgChrgAbrtRsn : 41|3@0+ (1,0) [0|6] "" TCP,CSM,CSM_AV,IPC,IPC_INT,VCU
 SG_ HiVltgChrgSysSplyFltIndOn : 48|1@0+ (1,0) [0|1] "" IPC,IPC_INT,VCU
 SG_ HiVltgBatStopChrgBtnVsbl : 49|1@0+ (1,0) [0|1] "" CSM,CSM_AV,VCU
 SG_ HiVltgBatChrgCordCnctdIndOn : 50|1@0+ (1,0) [0|1] "" TCP,VKM,IPC,IPC_INT,VCU
 SG_ HiVltgBatBulkChrgCmplt : 51|1@0+ (1,0) [0|1] "" CSM,CSM_AV,IPC,IPC_INT,VCU
 SG_ ElecPrplMtrOvrSpdIndOn : 52|1@0+ (1,0) [0|1] "" IPC,IPC_INT,VCU
 SG_ HiVltgChrgInhbRsn : 54|2@0+ (1,0) [0|3] "" TCP,CSM,CSM_AV,IPC,IPC_INT,VCU
 SG_ DrvCycEleclEngyUsd_DuD : 63|1@0+ (1,0) [0|1] "" FPI,RSI,CSM,CSM_AV,IPC,IPC_INT,VCU

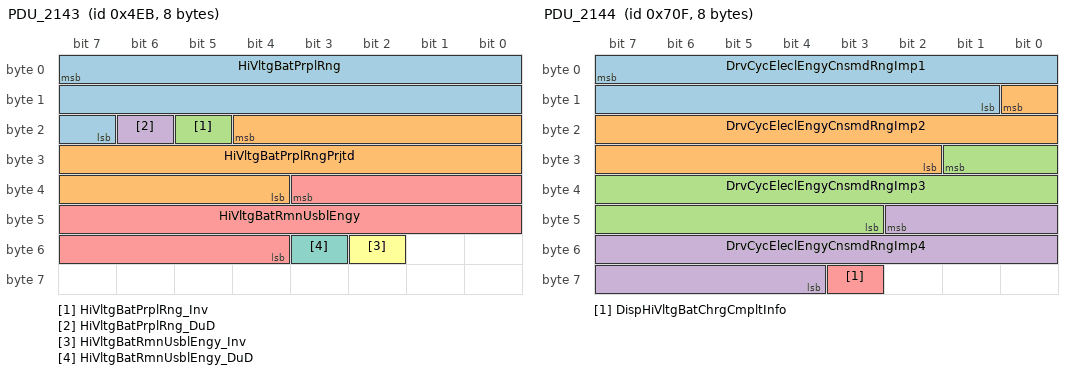
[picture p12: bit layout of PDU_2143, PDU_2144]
BO_ 1259 PDU_2143: 8 CGM
 SG_ HiVltgBatPrplRng : 7|17@0+ (0.015625,0) [0|2047.98] "km" FPI,RSI,TCP,VKM,CSM,CSM_AV,IPC,IPC_INT,VCU
 SG_ HiVltgBatPrplRngPrjtd : 20|17@0+ (0.015625,0) [0|2047.98] "km" CSM,CSM_AV,VCU
 SG_ HiVltgBatPrplRng_Inv : 21|1@0+ (1,0) [0|1] "" FPI,RSI,TCP,VKM,CSM,CSM_AV,IPC,IPC_INT,VCU
 SG_ HiVltgBatPrplRng_DuD : 22|1@0+ (1,0) [0|1] "" FPI,RSI,VKM,CSM,CSM_AV,IPC,IPC_INT,VCU
 SG_ HiVltgBatRmnUsblEngy : 35|16@0+ (0.01,0) [0|655.35] "kWh" TCP,CSM,CSM_AV,VCU
 SG_ HiVltgBatRmnUsblEngy_Inv : 50|1@0+ (1,0) [0|1] "" CSM,CSM_AV,VCU
 SG_ HiVltgBatRmnUsblEngy_DuD : 51|1@0+ (1,0) [0|1] "" CSM,CSM_AV,VCU

BO_ 1807 PDU_2144: 8 CGM
 SG_ DrvCycEleclEngyCnsmdRngImp1 : 7|15@0- (0.1,0) [-1638.4|1638.3] "km" CSM,CSM_AV,IPC,IPC_INT,VCU
 SG_ DrvCycEleclEngyCnsmdRngImp2 : 8|15@0- (0.1,0) [-1638.4|1638.3] "km" CSM,CSM_AV,IPC,IPC_INT,VCU
 SG_ DrvCycEleclEngyCnsmdRngImp3 : 25|15@0- (0.1,0) [-1638.4|1638.3] "km" CSM,CSM_AV,IPC,IPC_INT,VCU
 SG_ DrvCycEleclEngyCnsmdRngImp4 : 42|15@0- (0.1,0) [-1638.4|1638.3] "km" CSM,CSM_AV,IPC,IPC_INT,VCU
 SG_ DispHiVltgBatChrgCmpltInfo : 59|1@0+ (1,0) [0|1] "" CSM,CSM_AV,IPC,IPC_INT,VCU

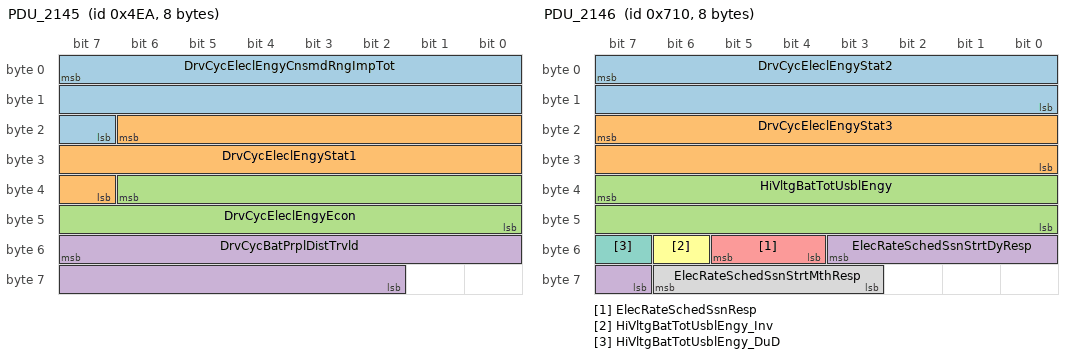
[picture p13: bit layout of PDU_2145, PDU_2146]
BO_ 1258 PDU_2145: 8 CGM
 SG_ DrvCycEleclEngyCnsmdRngImpTot : 7|17@0- (0.1,0) [-6553.6|6553.5] "km" CSM,CSM_AV,IPC,IPC_INT,VCU
 SG_ DrvCycEleclEngyStat1 : 22|16@0+ (0.01,0) [0|655.35] "kWh" FPI,RSI,CSM,CSM_AV,VCU
 SG_ DrvCycEleclEngyEcon : 38|15@0- (0.1,0) [-1638.4|1638.3] "" TCP,CSM,CSM_AV,IPC,IPC_INT,VCU
 SG_ DrvCycBatPrplDistTrvld : 55|14@0+ (0.1,0) [0|1638.3] "km" FPI,RSI,CSM,CSM_AV,IPC,IPC_INT,VCU

BO_ 1808 PDU_2146: 8 CGM
 SG_ DrvCycEleclEngyStat2 : 7|16@0+ (0.01,0) [0|655.35] "kWh" FPI,RSI,CSM,CSM_AV,VCU
 SG_ DrvCycEleclEngyStat3 : 23|16@0+ (0.01,0) [0|655.35] "kWh" CSM,CSM_AV,VCU
 SG_ HiVltgBatTotUsblEngy : 39|16@0+ (0.01,0) [0|655.35] "kWh" TCP,CSM,CSM_AV,VCU
 SG_ ElecRateSchedSsnStrtDyResp : 51|5@0+ (1,0) [0|31] "day" CSM,CSM_AV,VCU
 SG_ ElecRateSchedSsnResp : 53|2@0+ (1,0) [0|3] "" CSM,CSM_AV,VCU
 SG_ HiVltgBatTotUsblEngy_Inv : 54|1@0+ (1,0) [0|1] "" CSM,CSM_AV,VCU
 SG_ HiVltgBatTotUsblEngy_DuD : 55|1@0+ (1,0) [0|1] "" CSM,CSM_AV,VCU
 SG_ ElecRateSchedSsnStrtMthResp : 62|4@0+ (1,0) [0|12] "" CSM,CSM_AV,VCU

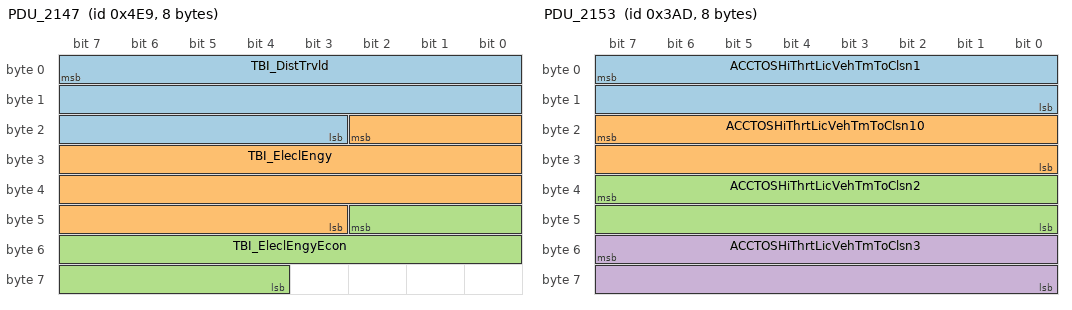
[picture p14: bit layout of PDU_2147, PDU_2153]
BO_ 1257 PDU_2147: 8 CGM
 SG_ TBI_DistTrvld : 7|21@0+ (0.1,0) [0|209715] "km" FPI,RSI,IPC,IPC_INT,VCU
 SG_ TBI_EleclEngy : 18|24@0+ (0.1,0) [0|1.67772e+006] "kWh" IPC,IPC_INT,VCU
 SG_ TBI_EleclEngyEcon : 42|15@0- (0.1,0) [-1638.4|1638.3] "" FPI,RSI,IPC,IPC_INT,VCU

BO_ 941 PDU_2153: 8 CGM
 SG_ ACCTOSHiThrtLicVehTmToClsn1 : 7|16@0+ (0.001,0) [0|65.535] "s" TCP
 SG_ ACCTOSHiThrtLicVehTmToClsn10 : 23|16@0+ (0.001,0) [0|65.535] "s" TCP
 SG_ ACCTOSHiThrtLicVehTmToClsn2 : 39|16@0+ (0.001,0) [0|65.535] "s" TCP
 SG_ ACCTOSHiThrtLicVehTmToClsn3 : 55|16@0+ (0.001,0) [0|65.535] "s" TCP

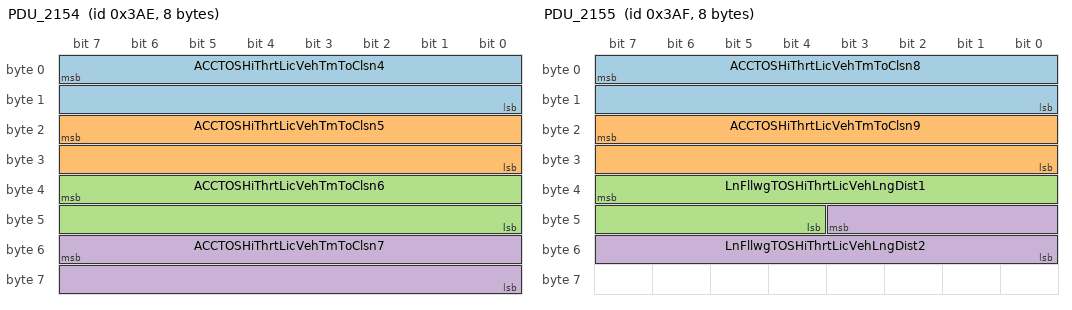
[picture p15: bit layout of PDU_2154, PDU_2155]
BO_ 942 PDU_2154: 8 CGM
 SG_ ACCTOSHiThrtLicVehTmToClsn4 : 7|16@0+ (0.001,0) [0|65.535] "s" TCP
 SG_ ACCTOSHiThrtLicVehTmToClsn5 : 23|16@0+ (0.001,0) [0|65.535] "s" TCP
 SG_ ACCTOSHiThrtLicVehTmToClsn6 : 39|16@0+ (0.001,0) [0|65.535] "s" TCP
 SG_ ACCTOSHiThrtLicVehTmToClsn7 : 55|16@0+ (0.001,0) [0|65.535] "s" TCP

BO_ 943 PDU_2155: 8 CGM
 SG_ ACCTOSHiThrtLicVehTmToClsn8 : 7|16@0+ (0.001,0) [0|65.535] "s" TCP
 SG_ ACCTOSHiThrtLicVehTmToClsn9 : 23|16@0+ (0.001,0) [0|65.535] "s" TCP
 SG_ LnFllwgTOSHiThrtLicVehLngDist1 : 39|12@0- (0.125,0) [-256|255.875] "m" TCP
 SG_ LnFllwgTOSHiThrtLicVehLngDist2 : 43|12@0- (0.125,0) [-256|255.875] "m" TCP

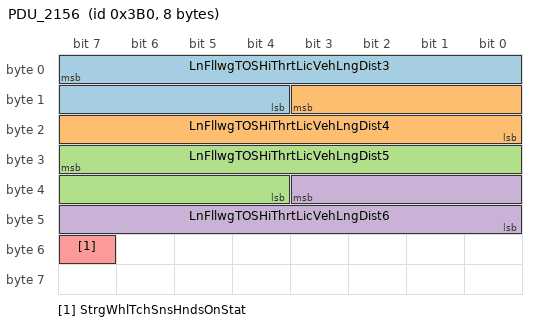
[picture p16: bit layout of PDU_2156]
BO_ 944 PDU_2156: 8 CGM
 SG_ LnFllwgTOSHiThrtLicVehLngDist3 : 7|12@0- (0.125,0) [-256|255.875] "m" TCP
 SG_ LnFllwgTOSHiThrtLicVehLngDist4 : 11|12@0- (0.125,0) [-256|255.875] "m" TCP
 SG_ LnFllwgTOSHiThrtLicVehLngDist5 : 31|12@0- (0.125,0) [-256|255.875] "m" TCP
 SG_ LnFllwgTOSHiThrtLicVehLngDist6 : 35|12@0- (0.125,0) [-256|255.875] "m" TCP
 SG_ StrgWhlTchSnsHndsOnStat : 55|1@0+ (1,0) [0|1] "" TCP

BA_DEF_ SG_  "SignalType" STRING ;
BA_DEF_ SG_  "SignalLongName" STRING ;
BA_DEF_ BO_  "GenMsgCycleTime" INT 0 10000;
BA_DEF_ BO_  "GenMsgSendType" ENUM "cyclicX","spontanX","cyclicIfActiveX","spontanWithDelay","cyclicAndSpontanX","cyclicAndSpontanWithDelay","spontanWithRepetition","cyclicIfActiveAndSpontanWD";
BA_DEF_DEF_  "SignalType" "";
BA_DEF_DEF_  "SignalLongName" "";
BA_DEF_DEF_  "GenMsgCycleTime" 0;
BA_DEF_DEF_  "GenMsgSendType" "cyclicX";
BA_ "GenMsgCycleTime" BO_ 1416 1000;
BA_ "GenMsgCycleTime" BO_ 1811 1000;
BA_ "GenMsgCycleTime" BO_ 1510 1000;
BA_ "GenMsgCycleTime" BO_ 1511 1000;
BA_ "GenMsgCycleTime" BO_ 1429 1000;
BA_ "GenMsgCycleTime" BO_ 1512 1000;
BA_ "GenMsgCycleTime" BO_ 1417 1000;
BA_ "GenMsgCycleTime" BO_ 1418 1000;
BA_ "GenMsgCycleTime" BO_ 1419 1000;
BA_ "GenMsgCycleTime" BO_ 1025 100;
BA_ "GenMsgCycleTime" BO_ 2005 1000;
BA_ "GenMsgCycleTime" BO_ 1479 1000;
BA_ "GenMsgCycleTime" BO_ 1883 1000;
BA_ "GenMsgCycleTime" BO_ 1953 1000;
BA_ "GenMsgCycleTime" BO_ 1114 1000;
BA_ "GenMsgCycleTime" BO_ 1984 1000;
BA_ "GenMsgCycleTime" BO_ 1060 1000;
BA_ "GenMsgCycleTime" BO_ 1059 1000;
BA_ "GenMsgCycleTime" BO_ 1188 1000;
BA_ "GenMsgCycleTime" BO_ 1792 1000;
BA_ "GenMsgCycleTime" BO_ 1273 1000;
BA_ "GenMsgCycleTime" BO_ 1187 1000;
BA_ "GenMsgCycleTime" BO_ 720 100;
BA_ "GenMsgCycleTime" BO_ 1797 1000;
BA_ "GenMsgCycleTime" BO_ 1497 1000;
BA_ "GenMsgCycleTime" BO_ 1268 1000;
BA_ "GenMsgCycleTime" BO_ 1798 1000;
BA_ "GenMsgCycleTime" BO_ 1267 1000;
BA_ "GenMsgCycleTime" BO_ 1799 1000;
BA_ "GenMsgCycleTime" BO_ 1266 1000;
BA_ "GenMsgCycleTime" BO_ 721 100;
BA_ "GenMsgCycleTime" BO_ 1800 1000;
BA_ "GenMsgCycleTime" BO_ 1265 1000;
BA_ "GenMsgCycleTime" BO_ 1801 1000;
BA_ "GenMsgCycleTime" BO_ 1264 1000;
BA_ "GenMsgCycleTime" BO_ 1802 1000;
BA_ "GenMsgCycleTime" BO_ 1263 1000;
BA_ "GenMsgCycleTime" BO_ 1803 1000;
BA_ "GenMsgCycleTime" BO_ 1262 1000;
BA_ "GenMsgCycleTime" BO_ 1804 1000;
BA_ "GenMsgCycleTime" BO_ 1261 1000;
BA_ "GenMsgCycleTime" BO_ 1805 1000;
BA_ "GenMsgCycleTime" BO_ 1260 1000;
BA_ "GenMsgCycleTime" BO_ 1806 1000;
BA_ "GenMsgCycleTime" BO_ 1259 1000;
BA_ "GenMsgCycleTime" BO_ 1807 1000;
BA_ "GenMsgCycleTime" BO_ 1258 1000;
BA_ "GenMsgCycleTime" BO_ 1808 1000;
BA_ "GenMsgCycleTime" BO_ 1257 1000;
BA_ "GenMsgCycleTime" BO_ 941 500;
BA_ "GenMsgCycleTime" BO_ 942 500;
BA_ "GenMsgCycleTime" BO_ 943 500;
BA_ "GenMsgCycleTime" BO_ 944 500;
BA_ "SignalType" SG_ 1416 TrffcLgtAsstWrnChmEvntStat "ENM";
BA_ "SignalLongName" SG_ 1416 TrffcLgtAsstWrnChmEvntStat "Traffic Light Assist Warning Chime Event State";
BA_ "SignalType" SG_ 1416 TrffcLgtAsstCstCurrSetVal "ENM";
BA_ "SignalLongName" SG_ 1416 TrffcLgtAsstCstCurrSetVal "Traffic Light Assist Customization Current Setting Value";
BA_ "SignalType" SG_ 1416 GlrFrHgBmRspTypCstCurSetVal "ENM";
BA_ "SignalLongName" SG_ 1416 GlrFrHgBmRspTypCstCurSetVal "Glare Free High Beam Response Type Customization Current Setting Value";
BA_ "SignalType" SG_ 1416 GlrFrHgBmRspTypCstAvlFlg7 "ENM";
BA_ "SignalLongName" SG_ 1416 GlrFrHgBmRspTypCstAvlFlg7 "Glare Free High Beam Response Type Customization Availability Flag7";
BA_ "SignalType" SG_ 1416 GlrFrHgBmRspTypCstAvlFlg6 "ENM";
BA_ "SignalLongName" SG_ 1416 GlrFrHgBmRspTypCstAvlFlg6 "Glare Free High Beam Response Type Customization Availability Flag6";
BA_ "SignalType" SG_ 1416 GlrFrHgBmRspTypCstAvlFlg5 "ENM";
BA_ "SignalLongName" SG_ 1416 GlrFrHgBmRspTypCstAvlFlg5 "Glare Free High Beam Response Type Customization Availability Flag5";
BA_ "SignalType" SG_ 1416 GlrFrHgBmRspTypCstAvlFlg4 "ENM";
BA_ "SignalLongName" SG_ 1416 GlrFrHgBmRspTypCstAvlFlg4 "Glare Free High Beam Response Type Customization Availability Flag4";
BA_ "SignalType" SG_ 1416 GlrFrHgBmRspTypCstAvlFlg3 "ENM";
BA_ "SignalLongName" SG_ 1416 GlrFrHgBmRspTypCstAvlFlg3 "Glare Free High Beam Response Type Customization Availability Flag3";
BA_ "SignalType" SG_ 1416 GlrFrHgBmRspTypCstAvlFlg2 "ENM";
BA_ "SignalLongName" SG_ 1416 GlrFrHgBmRspTypCstAvlFlg2 "Glare Free High Beam Response Type Customization Availability Flag2";
BA_ "SignalType" SG_ 1416 GlrFrHgBmRspTypCstAvlFlg1 "ENM";
BA_ "SignalLongName" SG_ 1416 GlrFrHgBmRspTypCstAvlFlg1 "Glare Free High Beam Response Type Customization Availability Flag1";
BA_ "SignalType" SG_ 1416 AutoHgBmCtrlIO "ENM";
BA_ "SignalLongName" SG_ 1416 AutoHgBmCtrlIO "Auto High Beam Control Indication On";
BA_ "SignalType" SG_ 1416 TrffcLgtAsstCstAvlFlg7 "ENM";
BA_ "SignalLongName" SG_ 1416 TrffcLgtAsstCstAvlFlg7 "Traffic Light Assist Customization Availability Flag 7";
BA_ "SignalType" SG_ 1416 TrffcLgtAsstCstAvlFlg6 "ENM";
BA_ "SignalLongName" SG_ 1416 TrffcLgtAsstCstAvlFlg6 "Traffic Light Assist Customization Availability Flag 6";
BA_ "SignalType" SG_ 1416 TrffcLgtAsstCstAvlFlg5 "ENM";
BA_ "SignalLongName" SG_ 1416 TrffcLgtAsstCstAvlFlg5 "Traffic Light Assist Customization Availability Flag 5";
BA_ "SignalType" SG_ 1416 TrffcLgtAsstCstAvlFlg4 "ENM";
BA_ "SignalLongName" SG_ 1416 TrffcLgtAsstCstAvlFlg4 "Traffic Light Assist Customization Availability Flag 4";
BA_ "SignalType" SG_ 1416 TrffcLgtAsstCstAvlFlg3 "ENM";
BA_ "SignalLongName" SG_ 1416 TrffcLgtAsstCstAvlFlg3 "Traffic Light Assist Customization Availability Flag 3";
BA_ "SignalType" SG_ 1416 TrffcLgtAsstCstAvlFlg2 "ENM";
BA_ "SignalLongName" SG_ 1416 TrffcLgtAsstCstAvlFlg2 "Traffic Light Assist Customization Availability Flag 2";
BA_ "SignalType" SG_ 1416 TrffcLgtAsstCstAvlFlg1 "ENM";
BA_ "SignalLongName" SG_ 1416 TrffcLgtAsstCstAvlFlg1 "Traffic Light Assist Customization Availability Flag 1";
BA_ "SignalType" SG_ 1416 GlrFrHgBmRspTypCstStAvl "ENM";
BA_ "SignalLongName" SG_ 1416 GlrFrHgBmRspTypCstStAvl "Glare Free High Beam Response Type Customization Setting Available";
BA_ "SignalType" SG_ 1416 TrffcLgtAsstCstSetAval "ENM";
BA_ "SignalLongName" SG_ 1416 TrffcLgtAsstCstSetAval "Traffic Light Assist Customization Setting Available";
BA_ "SignalLongName" SG_ 1811 TSMCurrSpdLim "Traffic Sign Memory Current Speed Limit";
BA_ "SignalType" SG_ 1811 TSMEurDispSgn2Mn "ENM";
BA_ "SignalLongName" SG_ 1811 TSMEurDispSgn2Mn "Traffic Sign Memory Europe Display Europe Sign 2 Main";
BA_ "SignalType" SG_ 1811 TSMEurDispSgn1Mn "ENM";
BA_ "SignalLongName" SG_ 1811 TSMEurDispSgn1Mn "Traffic Sign Memory Europe Display Sign 1 Main";
BA_ "SignalType" SG_ 1811 TSMUSAndCADispSgn1Mn "ENM";
BA_ "SignalLongName" SG_ 1811 TSMUSAndCADispSgn1Mn "Traffic Sign Memory US and Canada Display Sign 1 Main";
BA_ "SignalType" SG_ 1811 TSMUSAndCADispSgn2Mn "ENM";
BA_ "SignalLongName" SG_ 1811 TSMUSAndCADispSgn2Mn "Traffic Sign Memory US and Canada Display Sign 2 Main";
BA_ "SignalType" SG_ 1811 TSMEurDispSgn2AddOn "ENM";
BA_ "SignalLongName" SG_ 1811 TSMEurDispSgn2AddOn "Traffic Sign Memory Display Sign 2 Add-On";
BA_ "SignalType" SG_ 1811 TSMEurDispSgn1AddOn "ENM";
BA_ "SignalLongName" SG_ 1811 TSMEurDispSgn1AddOn "Traffic Sign Memory Europe Display Sign 1 Add-On";
BA_ "SignalType" SG_ 1811 FrwdVsFlDtcnIndOn "ENM";
BA_ "SignalLongName" SG_ 1811 FrwdVsFlDtcnIndOn "Front Vision Failure Detection Indication On";
BA_ "SignalType" SG_ 1811 FrwdVsAdvWthrIndOn "ENM";
BA_ "SignalLongName" SG_ 1811 FrwdVsAdvWthrIndOn "Front Vision Adverse Weather Indication On";
BA_ "SignalType" SG_ 1811 TSMUSAndCADispSgn2AddOn "ENM";
BA_ "SignalLongName" SG_ 1811 TSMUSAndCADispSgn2AddOn "Traffic Sign Memory US and Canada Display Sign 2 Add On";
BA_ "SignalType" SG_ 1811 TSMUSAndCADispSgn1AddOn "ENM";
BA_ "SignalLongName" SG_ 1811 TSMUSAndCADispSgn1AddOn "Traffic Sign Memory US and Canada Display Sign 1 Add On";
BA_ "SignalType" SG_ 1811 TrffcLgtAsstHUDWrnIndOn "ENM";
BA_ "SignalLongName" SG_ 1811 TrffcLgtAsstHUDWrnIndOn "Traffic Light Assist Heads up Display Warning Indication On";
BA_ "SignalType" SG_ 1811 TrffcLgtAsstClstrWrnIndOn "ENM";
BA_ "SignalLongName" SG_ 1811 TrffcLgtAsstClstrWrnIndOn "Traffic Light Assist Cluster Warning Indication On";
BA_ "SignalType" SG_ 1811 TSMSgnNtfnIndOn "ENM";
BA_ "SignalLongName" SG_ 1811 TSMSgnNtfnIndOn "Traffic Sign Memory Sign Notification Indication On";
BA_ "SignalType" SG_ 1811 TSMPDAMnSgnFlshgReq "ENM";
BA_ "SignalLongName" SG_ 1811 TSMPDAMnSgnFlshgReq "Traffic Sign Memory PDA Main Sign Flashing Request";
BA_ "SignalType" SG_ 1811 TSMNoEntryIndOn "ENM";
BA_ "SignalLongName" SG_ 1811 TSMNoEntryIndOn "Traffic Sign Memory No Entry Indication On";
BA_ "SignalType" SG_ 1811 TSMIcePsblIndOn "ENM";
BA_ "SignalLongName" SG_ 1811 TSMIcePsblIndOn "Traffic Sign Memory Ice Possible Indication On";
BA_ "SignalType" SG_ 1811 TSMAddTrfSgnAvIndOn "ENM";
BA_ "SignalLongName" SG_ 1811 TSMAddTrfSgnAvIndOn "Traffic Sign Memory Additional Traffic Signs Available Indication On";
BA_ "SignalType" SG_ 1811 FrwdVsFllBlckIndOn "ENM";
BA_ "SignalLongName" SG_ 1811 FrwdVsFllBlckIndOn "Front Vision Full Blockage Indication On";
BA_ "SignalType" SG_ 1811 TrffcLgtAsstRLADWrnIndOn "ENM";
BA_ "SignalLongName" SG_ 1811 TrffcLgtAsstRLADWrnIndOn "Traffic Light Assist Reflective Light Auxiliary Display Warning Indication On";
BA_ "SignalType" SG_ 1510 SBZALCAVisIndStatLt "ENM";
BA_ "SignalLongName" SG_ 1510 SBZALCAVisIndStatLt "SBZA - LCA Visual Indication State Left";
BA_ "SignalType" SG_ 1511 SBZALCAVisIndStatRt "ENM";
BA_ "SignalLongName" SG_ 1511 SBZALCAVisIndStatRt "SBZA - LCA Visual Indication State Right";
BA_ "SignalType" SG_ 1429 HtchVwAutoElecPrkBrkAppReqd "ENM";
BA_ "SignalLongName" SG_ 1429 HtchVwAutoElecPrkBrkAppReqd "Hitch View Autonomous Electric Park Brake Apply Requested";
BA_ "SignalType" SG_ 1512 AutoHgBmActReq "ENM";
BA_ "SignalLongName" SG_ 1512 AutoHgBmActReq "Auto High Beam Activation Request";
BA_ "SignalType" SG_ 1417 RrCrsTrfcAlrtLftIndCtrl "ENM";
BA_ "SignalLongName" SG_ 1417 RrCrsTrfcAlrtLftIndCtrl "Rear Cross Traffic Alert Left Indication Control";
BA_ "SignalType" SG_ 1417 RrCrsTrfcAlrtCstCrStVal "ENM";
BA_ "SignalLongName" SG_ 1417 RrCrsTrfcAlrtCstCrStVal "Rear Cross Traffic Alert Customization Current Setting Value";
BA_ "SignalType" SG_ 1417 LnChgAlrtCstCrStVal "ENM";
BA_ "SignalLongName" SG_ 1417 LnChgAlrtCstCrStVal "Lane Change Alert Customization Current Setting Value";
BA_ "SignalType" SG_ 1418 SBZAlrtCstCrStVal "ENM";
BA_ "SignalLongName" SG_ 1418 SBZAlrtCstCrStVal "Side Blind Zone Alert Customization Current Setting Value";
BA_ "SignalType" SG_ 1418 ByclDtnCstCurrSetVal "ENM";
BA_ "SignalLongName" SG_ 1418 ByclDtnCstCurrSetVal "Bicycle Detection Customization Current Setting Value";
BA_ "SignalType" SG_ 1418 ByclDtnArbdIndStat "ENM";
BA_ "SignalLongName" SG_ 1418 ByclDtnArbdIndStat "Bicycle Detection Arbitrated Indication State";
BA_ "SignalType" SG_ 1418 ByclDtnCstAvlFlg1 "ENM";
BA_ "SignalLongName" SG_ 1418 ByclDtnCstAvlFlg1 "Bicycle Detection Customization Availability Flag 1";
BA_ "SignalType" SG_ 1418 RrCrsTrfcAlrtLtSdChmEvntStat "ENM";
BA_ "SignalLongName" SG_ 1418 RrCrsTrfcAlrtLtSdChmEvntStat "Rear Cross Traffic Alert Left Side Chime Event State";
BA_ "SignalType" SG_ 1418 ByclDtnArbdLvl2ChmEvntStat "ENM";
BA_ "SignalLongName" SG_ 1418 ByclDtnArbdLvl2ChmEvntStat "Bicycle Detection Arbitrated Level 2 Chime Event State";
BA_ "SignalType" SG_ 1418 ByclDtnArbdLvl1ChmEvntStat "ENM";
BA_ "SignalLongName" SG_ 1418 ByclDtnArbdLvl1ChmEvntStat "Bicycle Detection Arbitrated Level 1 Chime Event State";
BA_ "SignalType" SG_ 1418 LnChgAlrtCstAvlFlg1 "ENM";
BA_ "SignalLongName" SG_ 1418 LnChgAlrtCstAvlFlg1 "Lane Change Alert Customization Availability Flag 1";
BA_ "SignalType" SG_ 1418 ByclDtnCstSetAval "ENM";
BA_ "SignalLongName" SG_ 1418 ByclDtnCstSetAval "Bicycle Detection Customization Setting Available";
BA_ "SignalType" SG_ 1418 ByclDtnCstAvlFlg7 "ENM";
BA_ "SignalLongName" SG_ 1418 ByclDtnCstAvlFlg7 "Bicycle Detection Customization Availability Flag 7";
BA_ "SignalType" SG_ 1418 ByclDtnCstAvlFlg6 "ENM";
BA_ "SignalLongName" SG_ 1418 ByclDtnCstAvlFlg6 "Bicycle Detection Customization Availability Flag 6";
BA_ "SignalType" SG_ 1418 ByclDtnCstAvlFlg5 "ENM";
BA_ "SignalLongName" SG_ 1418 ByclDtnCstAvlFlg5 "Bicycle Detection Customization Availability Flag 5";
BA_ "SignalType" SG_ 1418 ByclDtnCstAvlFlg4 "ENM";
BA_ "SignalLongName" SG_ 1418 ByclDtnCstAvlFlg4 "Bicycle Detection Customization Availability Flag 4";
BA_ "SignalType" SG_ 1418 ByclDtnCstAvlFlg3 "ENM";
BA_ "SignalLongName" SG_ 1418 ByclDtnCstAvlFlg3 "Bicycle Detection Customization Availability Flag 3";
BA_ "SignalType" SG_ 1418 ByclDtnCstAvlFlg2 "ENM";
BA_ "SignalLongName" SG_ 1418 ByclDtnCstAvlFlg2 "Bicycle Detection Customization Availability Flag 2";
BA_ "SignalType" SG_ 1418 LnChgAlrtSysOffIndOn "ENM";
BA_ "SignalLongName" SG_ 1418 LnChgAlrtSysOffIndOn "Lane Change Alert System Off Indication On";
BA_ "SignalType" SG_ 1418 LnChgAlrtCstStAvl "ENM";
BA_ "SignalLongName" SG_ 1418 LnChgAlrtCstStAvl "Lane Change Alert Customization Setting Available";
BA_ "SignalType" SG_ 1418 LnChgAlrtCstAvlFlg7 "ENM";
BA_ "SignalLongName" SG_ 1418 LnChgAlrtCstAvlFlg7 "Lane Change Alert Customization Availability Flag 7";
BA_ "SignalType" SG_ 1418 LnChgAlrtCstAvlFlg6 "ENM";
BA_ "SignalLongName" SG_ 1418 LnChgAlrtCstAvlFlg6 "Lane Change Alert Customization Availability Flag 6";
BA_ "SignalType" SG_ 1418 LnChgAlrtCstAvlFlg5 "ENM";
BA_ "SignalLongName" SG_ 1418 LnChgAlrtCstAvlFlg5 "Lane Change Alert Customization Availability Flag 5";
BA_ "SignalType" SG_ 1418 LnChgAlrtCstAvlFlg4 "ENM";
BA_ "SignalLongName" SG_ 1418 LnChgAlrtCstAvlFlg4 "Lane Change Alert Customization Availability Flag 4";
BA_ "SignalType" SG_ 1418 LnChgAlrtCstAvlFlg3 "ENM";
BA_ "SignalLongName" SG_ 1418 LnChgAlrtCstAvlFlg3 "Lane Change Alert Customization Availability Flag 3";
BA_ "SignalType" SG_ 1418 LnChgAlrtCstAvlFlg2 "ENM";
BA_ "SignalLongName" SG_ 1418 LnChgAlrtCstAvlFlg2 "Lane Change Alert Customization Availability Flag 2";
BA_ "SignalType" SG_ 1418 RrCrsTrfcAlrtCstStAvl "ENM";
BA_ "SignalLongName" SG_ 1418 RrCrsTrfcAlrtCstStAvl "Rear Cross Traffic Alert Customization Setting Available";
BA_ "SignalType" SG_ 1418 RrCrsTrfcAlrtCstAvlFlg7 "ENM";
BA_ "SignalLongName" SG_ 1418 RrCrsTrfcAlrtCstAvlFlg7 "Rear Cross Traffic Alert Customization Availability Flag 7";
BA_ "SignalType" SG_ 1418 RrCrsTrfcAlrtCstAvlFlg6 "ENM";
BA_ "SignalLongName" SG_ 1418 RrCrsTrfcAlrtCstAvlFlg6 "Rear Cross Traffic Alert Customization Availability Flag 6";
BA_ "SignalType" SG_ 1418 RrCrsTrfcAlrtCstAvlFlg5 "ENM";
BA_ "SignalLongName" SG_ 1418 RrCrsTrfcAlrtCstAvlFlg5 "Rear Cross Traffic Alert Customization Availability Flag 5";
BA_ "SignalType" SG_ 1418 RrCrsTrfcAlrtCstAvlFlg4 "ENM";
BA_ "SignalLongName" SG_ 1418 RrCrsTrfcAlrtCstAvlFlg4 "Rear Cross Traffic Alert Customization Availability Flag 4";
BA_ "SignalType" SG_ 1418 RrCrsTrfcAlrtCstAvlFlg3 "ENM";
BA_ "SignalLongName" SG_ 1418 RrCrsTrfcAlrtCstAvlFlg3 "Rear Cross Traffic Alert Customization Availability Flag 3";
BA_ "SignalType" SG_ 1418 RrCrsTrfcAlrtCstAvlFlg2 "ENM";
BA_ "SignalLongName" SG_ 1418 RrCrsTrfcAlrtCstAvlFlg2 "Rear Cross Traffic Alert Customization Availability Flag 2";
BA_ "SignalType" SG_ 1418 RrCrsTrfcAlrtCstAvlFlg1 "ENM";
BA_ "SignalLongName" SG_ 1418 RrCrsTrfcAlrtCstAvlFlg1 "Rear Cross Traffic Alert Customization Availability Flag 1";
BA_ "SignalType" SG_ 1418 RrCrsTrfcBrkgAutoBrkgRelIndOn "ENM";
BA_ "SignalLongName" SG_ 1418 RrCrsTrfcBrkgAutoBrkgRelIndOn "Rear Cross Traffic Braking Autonomous Braking Release Indication On";
BA_ "SignalType" SG_ 1418 RrCrsTrfcAutoBrkgOffIndOn "ENM";
BA_ "SignalLongName" SG_ 1418 RrCrsTrfcAutoBrkgOffIndOn "Rear Cross Traffic Auto Braking Off Indication On";
BA_ "SignalType" SG_ 1418 RrCrsTrfcAlrtOffIndOn "ENM";
BA_ "SignalLongName" SG_ 1418 RrCrsTrfcAlrtOffIndOn "Rear Cross Traffic Alert System Off Indication On";
BA_ "SignalType" SG_ 1419 RrCrsTrfcAlrtRtSdChmEvntStat "ENM";
BA_ "SignalLongName" SG_ 1419 RrCrsTrfcAlrtRtSdChmEvntStat "Rear Cross Traffic Alert Right Side Chime Event State";
BA_ "SignalType" SG_ 1419 RrCrsTrfcAlrtRgIndCtrl "ENM";
BA_ "SignalLongName" SG_ 1419 RrCrsTrfcAlrtRgIndCtrl "Rear Cross Traffic Alert Right Indication Control";
BA_ "SignalLongName" SG_ 1025 RPCMHSR_HptcStReqSeqNum "Rear Pedestrian Collision Mitigation Haptic Seat Request : Haptic Seat Request Sequence Number";
BA_ "SignalLongName" SG_ 1025 RPCMHSR_HptcStReqPuls "Rear Pedestrian Collision Mitigation Haptic Seat Request : Haptic Seat Request Pulses";
BA_ "SignalType" SG_ 1025 VwgSysUndrbdyCamWshReq "ENM";
BA_ "SignalLongName" SG_ 1025 VwgSysUndrbdyCamWshReq "Viewing System Underbody Camera Wash Request";
BA_ "SignalType" SG_ 1025 TrlrVidVwCrgLmpReq "ENM";
BA_ "SignalLongName" SG_ 1025 TrlrVidVwCrgLmpReq "Trailering Video Viewing Cargo Lamp Request";
BA_ "SignalType" SG_ 1025 TrlrVidVwBoxRailLmpReq "ENM";
BA_ "SignalLongName" SG_ 1025 TrlrVidVwBoxRailLmpReq "Trailering Video Viewing Box Rail Lamp Request";
BA_ "SignalType" SG_ 1025 SrrndVwPudlLmpReqd "ENM";
BA_ "SignalLongName" SG_ 1025 SrrndVwPudlLmpReqd "Surround View Puddle Lamp Requested";
BA_ "SignalLongName" SG_ 2005 JKDLHSR_HptcStReqSeqNum "Jack Knife Detection Left Haptic Seat Request : Haptic Seat Request Sequence Number";
BA_ "SignalLongName" SG_ 2005 JKDLHSR_HptcStReqPuls "Jack Knife Detection Left Haptic Seat Request : Haptic Seat Request Pulses";
BA_ "SignalLongName" SG_ 2005 JKDRHSR_HptcStReqSeqNum "Jack Knife Detection Right Haptic Seat Request : Haptic Seat Request Sequence Number";
BA_ "SignalLongName" SG_ 2005 JKDRHSR_HptcStReqPuls "Jack Knife Detection Right Haptic Seat Request : Haptic Seat Request Pulses";
BA_ "SignalType" SG_ 1479 HndsOnLnCntrAsstIndReq "ENM";
BA_ "SignalLongName" SG_ 1479 HndsOnLnCntrAsstIndReq "Hands On Lane Centering Assist Information : Hands On Lane Centering Assist Indication Request";
BA_ "SignalType" SG_ 1479 HndsOnLnCntrAsstChmEvntStat "ENM";
BA_ "SignalLongName" SG_ 1479 HndsOnLnCntrAsstChmEvntStat "Hands On Lane Centering Assist Chime Event State";
BA_ "SignalType" SG_ 1479 LnFllwgFtrStat "ENM";
BA_ "SignalLongName" SG_ 1479 LnFllwgFtrStat "Lane Following Feature State";
BA_ "SignalType" SG_ 1479 GnrcLnMrkngIndRt "ENM";
BA_ "SignalLongName" SG_ 1479 GnrcLnMrkngIndRt "Hands On Lane Centering Assist Information : Generic Lane Marking Indication Right";
BA_ "SignalType" SG_ 1479 GnrcLnMrkngIndLt "ENM";
BA_ "SignalLongName" SG_ 1479 GnrcLnMrkngIndLt "Hands On Lane Centering Assist Information : Generic Lane Marking Indication Left";
BA_ "SignalLongName" SG_ 1479 ADASDrvrSeltdSpd "Advanced Driver Assist Systems Speed Information : Advanced Driver Assist Systems Driver Selected Speed";
BA_ "SignalType" SG_ 1479 ADASSetSpdIndReq "ENM";
BA_ "SignalLongName" SG_ 1479 ADASSetSpdIndReq "Advanced Driver Assist Systems Speed Information : Advanced Driver Assist Systems Set Speed Indication Request";
BA_ "SignalType" SG_ 1479 SuprRmtPrkActvnPndgIndOn "ENM";
BA_ "SignalLongName" SG_ 1479 SuprRmtPrkActvnPndgIndOn "Supervised Remote Parking Activation Pending Indication On";
BA_ "SignalLongName" SG_ 1883 InvsblTrlrAux1CamPlcmtFdbkPtch "Invisible Trailer Aux1 Camera Placement Feedback Pitch";
BA_ "SignalLongName" SG_ 1883 InvsblTrlrAux1CamPlcmtFdbkRoll "Invisible Trailer Aux1 Camera Placement Feedback Roll";
BA_ "SignalLongName" SG_ 1883 InvsblTrlrAux1CamPlcmtFdbkX "Invisible Trailer Aux1 Camera Placement Feedback X";
BA_ "SignalLongName" SG_ 1883 InvsblTrlrAux1CamPlcmtFdbkY "Invisible Trailer Aux1 Camera Placement Feedback Y";
BA_ "SignalType" SG_ 1883 JckKnfDtnCstAvlFlg1 "ENM";
BA_ "SignalLongName" SG_ 1883 JckKnfDtnCstAvlFlg1 "Jack Knife Detection Customization Availability Flag 1";
BA_ "SignalType" SG_ 1883 CrgBedVwAutoLgtCstAvlFlg7 "ENM";
BA_ "SignalLongName" SG_ 1883 CrgBedVwAutoLgtCstAvlFlg7 "Cargo Bed View Auto Lighting Customization Availability Flag 7";
BA_ "SignalType" SG_ 1883 CrgBedVwAutoLgtCstAvlFlg6 "ENM";
BA_ "SignalLongName" SG_ 1883 CrgBedVwAutoLgtCstAvlFlg6 "Cargo Bed View Auto Lighting Customization Availability Flag 6";
BA_ "SignalType" SG_ 1883 CrgBedVwAutoLgtCstAvlFlg5 "ENM";
BA_ "SignalLongName" SG_ 1883 CrgBedVwAutoLgtCstAvlFlg5 "Cargo Bed View Auto Lighting Customization Availability Flag 5";
BA_ "SignalType" SG_ 1883 CrgBedVwAutoLgtCstAvlFlg4 "ENM";
BA_ "SignalLongName" SG_ 1883 CrgBedVwAutoLgtCstAvlFlg4 "Cargo Bed View Auto Lighting Customization Availability Flag 4";
BA_ "SignalType" SG_ 1883 CrgBedVwAutoLgtCstAvlFlg3 "ENM";
BA_ "SignalLongName" SG_ 1883 CrgBedVwAutoLgtCstAvlFlg3 "Cargo Bed View Auto Lighting Customization Availability Flag 3";
BA_ "SignalType" SG_ 1883 CrgBedVwAutoLgtCstAvlFlg2 "ENM";
BA_ "SignalLongName" SG_ 1883 CrgBedVwAutoLgtCstAvlFlg2 "Cargo Bed View Auto Lighting Customization Availability Flag 2";
BA_ "SignalType" SG_ 1883 CrgBedVwAutoLgtCstAvlFlg1 "ENM";
BA_ "SignalLongName" SG_ 1883 CrgBedVwAutoLgtCstAvlFlg1 "Cargo Bed View Auto Lighting Customization Availability Flag 1";
BA_ "SignalType" SG_ 1883 JckKnfDtnCstAvlFlg7 "ENM";
BA_ "SignalLongName" SG_ 1883 JckKnfDtnCstAvlFlg7 "Jack Knife Detection Customization Availability Flag 7";
BA_ "SignalType" SG_ 1883 JckKnfDtnCstAvlFlg6 "ENM";
BA_ "SignalLongName" SG_ 1883 JckKnfDtnCstAvlFlg6 "Jack Knife Detection Customization Availability Flag 6";
BA_ "SignalType" SG_ 1883 JckKnfDtnCstAvlFlg5 "ENM";
BA_ "SignalLongName" SG_ 1883 JckKnfDtnCstAvlFlg5 "Jack Knife Detection Customization Availability Flag 5";
BA_ "SignalType" SG_ 1883 JckKnfDtnCstAvlFlg4 "ENM";
BA_ "SignalLongName" SG_ 1883 JckKnfDtnCstAvlFlg4 "Jack Knife Detection Customization Availability Flag 4";
BA_ "SignalType" SG_ 1883 JckKnfDtnCstAvlFlg3 "ENM";
BA_ "SignalLongName" SG_ 1883 JckKnfDtnCstAvlFlg3 "Jack Knife Detection Customization Availability Flag 3";
BA_ "SignalType" SG_ 1883 JckKnfDtnCstAvlFlg2 "ENM";
BA_ "SignalLongName" SG_ 1883 JckKnfDtnCstAvlFlg2 "Jack Knife Detection Customization Availability Flag 2";
BA_ "SignalType" SG_ 1953 VwgVwprtZmdVarActv "ENM";
BA_ "SignalLongName" SG_ 1953 VwgVwprtZmdVarActv "Viewing Viewport Zoomed Variant Active";
BA_ "SignalType" SG_ 1953 DlvryModeVwgCstAvlFlg7 "ENM";
BA_ "SignalLongName" SG_ 1953 DlvryModeVwgCstAvlFlg7 "Delivery Mode Viewing Customization Availability Flag 7";
BA_ "SignalType" SG_ 1953 DlvryModeVwgCstAvlFlg6 "ENM";
BA_ "SignalLongName" SG_ 1953 DlvryModeVwgCstAvlFlg6 "Delivery Mode Viewing Customization Availability Flag 6";
BA_ "SignalType" SG_ 1953 DlvryModeVwgCstAvlFlg5 "ENM";
BA_ "SignalLongName" SG_ 1953 DlvryModeVwgCstAvlFlg5 "Delivery Mode Viewing Customization Availability Flag 5";
BA_ "SignalType" SG_ 1953 DlvryModeVwgCstAvlFlg4 "ENM";
BA_ "SignalLongName" SG_ 1953 DlvryModeVwgCstAvlFlg4 "Delivery Mode Viewing Customization Availability Flag 4";
BA_ "SignalType" SG_ 1953 DlvryModeVwgCstAvlFlg3 "ENM";
BA_ "SignalLongName" SG_ 1953 DlvryModeVwgCstAvlFlg3 "Delivery Mode Viewing Customization Availability Flag 3";
BA_ "SignalType" SG_ 1953 DlvryModeVwgCstAvlFlg2 "ENM";
BA_ "SignalLongName" SG_ 1953 DlvryModeVwgCstAvlFlg2 "Delivery Mode Viewing Customization Availability Flag 2";
BA_ "SignalType" SG_ 1953 DlvryModeVwgCstAvlFlg1 "ENM";
BA_ "SignalLongName" SG_ 1953 DlvryModeVwgCstAvlFlg1 "Delivery Mode Viewing Customization Availability Flag 1";
BA_ "SignalType" SG_ 1953 VwgVwprtZoomBtnPrsnt "ENM";
BA_ "SignalLongName" SG_ 1953 VwgVwprtZoomBtnPrsnt "Viewing Viewport Zoom Button Present";
BA_ "SignalType" SG_ 1114 VwgCtlBtnPrsncBedHtch "ENM";
BA_ "SignalLongName" SG_ 1114 VwgCtlBtnPrsncBedHtch "Viewing Control Button Presence Bed Hitch";
BA_ "SignalType" SG_ 1114 VwgCtlBtnAvlUndrBdyFwdStActv "ENM";
BA_ "SignalLongName" SG_ 1114 VwgCtlBtnAvlUndrBdyFwdStActv "Viewing Control Button Availability Underbody Forward Split Active";
BA_ "SignalType" SG_ 1114 VwgCtlBtnAvlUndrBdyFwdRwdStActv "ENM";
BA_ "SignalLongName" SG_ 1114 VwgCtlBtnAvlUndrBdyFwdRwdStActv "Viewing Control Button Availability Underbody Forward Rearward Split Active";
BA_ "SignalType" SG_ 1114 VwgCtlBtnAvlTopDnVwActv "ENM";
BA_ "SignalLongName" SG_ 1114 VwgCtlBtnAvlTopDnVwActv "Viewing Control Button Availability Top Down View Active";
BA_ "SignalType" SG_ 1114 DlvryModeVwgCstSetAval "ENM";
BA_ "SignalLongName" SG_ 1114 DlvryModeVwgCstSetAval "Delivery Mode Viewing Customization Setting Available";
BA_ "SignalType" SG_ 1114 DlvryModeVwgCstCurrSetVal "ENM";
BA_ "SignalLongName" SG_ 1114 DlvryModeVwgCstCurrSetVal "Delivery Mode Viewing Customization Current Setting Value";
BA_ "SignalType" SG_ 1114 VwgCtlBtnPrsncFrtPrspctv "ENM";
BA_ "SignalLongName" SG_ 1114 VwgCtlBtnPrsncFrtPrspctv "Viewing Control Button Presence Front Perspective";
BA_ "SignalType" SG_ 1114 VwgCtlBtnPrsncFrtOvrhd "ENM";
BA_ "SignalLongName" SG_ 1114 VwgCtlBtnPrsncFrtOvrhd "Viewing Control Button Presence Front Overhead";
BA_ "SignalType" SG_ 1114 VwgCtlBtnPrsncFrtJnctn "ENM";
BA_ "SignalLongName" SG_ 1114 VwgCtlBtnPrsncFrtJnctn "Viewing Control Button Presence Front Junction";
BA_ "SignalType" SG_ 1114 VwgCtlBtnPrsncDynGdlns "ENM";
BA_ "SignalLongName" SG_ 1114 VwgCtlBtnPrsncDynGdlns "Viewing Control Button Presence Dynamic Guidelines";
BA_ "SignalType" SG_ 1114 VwgCtlBtnPrsncCurbOvrhd "ENM";
BA_ "SignalLongName" SG_ 1114 VwgCtlBtnPrsncCurbOvrhd "Viewing Control Button Presence Curb Overhead";
BA_ "SignalType" SG_ 1114 VwgCtlBtnPrsncCurb "ENM";
BA_ "SignalLongName" SG_ 1114 VwgCtlBtnPrsncCurb "Viewing Control Button Presence Curb";
BA_ "SignalType" SG_ 1114 VwgCtlBtnPrsncCrgBed "ENM";
BA_ "SignalLongName" SG_ 1114 VwgCtlBtnPrsncCrgBed "Viewing Control Button Presence Cargo Bed";
BA_ "SignalType" SG_ 1114 VwgCtlBtnPrsncBowl "ENM";
BA_ "SignalLongName" SG_ 1114 VwgCtlBtnPrsncBowl "Viewing Control Button Presence Bowl";
BA_ "SignalType" SG_ 1114 VwgCtlBtnPrsncSdRwd "ENM";
BA_ "SignalLongName" SG_ 1114 VwgCtlBtnPrsncSdRwd "Viewing Control Button Presence Side Rearward";
BA_ "SignalType" SG_ 1114 VwgCtlBtnPrsncSdFwd "ENM";
BA_ "SignalLongName" SG_ 1114 VwgCtlBtnPrsncSdFwd "Viewing Control Button Presence Side Forward";
BA_ "SignalType" SG_ 1114 VwgCtlBtnPrsncRrPrspctv "ENM";
BA_ "SignalLongName" SG_ 1114 VwgCtlBtnPrsncRrPrspctv "Viewing Control Button Presence Rear Perspective";
BA_ "SignalType" SG_ 1114 VwgCtlBtnPrsncRrOvrhd "ENM";
BA_ "SignalLongName" SG_ 1114 VwgCtlBtnPrsncRrOvrhd "Viewing Control Button Presence Rear Overhead";
BA_ "SignalType" SG_ 1114 VwgCtlBtnPrsncRrJnctn "ENM";
BA_ "SignalLongName" SG_ 1114 VwgCtlBtnPrsncRrJnctn "Viewing Control Button Presence Rear Junction";
BA_ "SignalType" SG_ 1114 VwgCtlBtnPrsncRrHtch "ENM";
BA_ "SignalLongName" SG_ 1114 VwgCtlBtnPrsncRrHtch "Viewing Control Button Presence Rear Hitch";
BA_ "SignalType" SG_ 1114 VwgCtlBtnPrsncJP "ENM";
BA_ "SignalLongName" SG_ 1114 VwgCtlBtnPrsncJP "Viewing Control Button Presence Japan";
BA_ "SignalType" SG_ 1114 VwgCtlBtnPrsncInvsblTrlr "ENM";
BA_ "SignalLongName" SG_ 1114 VwgCtlBtnPrsncInvsblTrlr "Viewing Control Button Presence Invisible Trailer";
BA_ "SignalType" SG_ 1114 VwgCtlBtnPrsncUndrBdyFwdRwdSt "ENM";
BA_ "SignalLongName" SG_ 1114 VwgCtlBtnPrsncUndrBdyFwdRwdSt "Viewing Control Button Presence Underbody Forward Rearward Split";
BA_ "SignalType" SG_ 1114 VwgCtlBtnPrsncUndrBdyFwd "ENM";
BA_ "SignalLongName" SG_ 1114 VwgCtlBtnPrsncUndrBdyFwd "Viewing Control Button Presence Underbody Forward";
BA_ "SignalType" SG_ 1114 VwgCtlBtnPrsncTrlrTowMir "ENM";
BA_ "SignalLongName" SG_ 1114 VwgCtlBtnPrsncTrlrTowMir "Viewing Control Button Presence Trailer Towing Mirror";
BA_ "SignalType" SG_ 1114 VwgCtlBtnPrsncTrlrGdlns "ENM";
BA_ "SignalLongName" SG_ 1114 VwgCtlBtnPrsncTrlrGdlns "Viewing Control Button Presence Trailering Guidelines";
BA_ "SignalType" SG_ 1114 VwgCtlBtnPrsncTrlrAux1Cmbd "ENM";
BA_ "SignalLongName" SG_ 1114 VwgCtlBtnPrsncTrlrAux1Cmbd "Viewing Control Button Presence Trailer Aux1 Combined";
BA_ "SignalType" SG_ 1114 VwgCtlBtnPrsncTrlrAux1 "ENM";
BA_ "SignalLongName" SG_ 1114 VwgCtlBtnPrsncTrlrAux1 "Viewing Control Button Presence Trailer Aux1";
BA_ "SignalType" SG_ 1114 VwgCtlBtnPrsncTransparentHood "ENM";
BA_ "SignalLongName" SG_ 1114 VwgCtlBtnPrsncTransparentHood "Viewing Control Button Presence Transparent Hood";
BA_ "SignalType" SG_ 1114 VwgCtlBtnPrsncTopDnSrrndVw "ENM";
BA_ "SignalLongName" SG_ 1114 VwgCtlBtnPrsncTopDnSrrndVw "Viewing Control Button Presence Top Down Surround View";
BA_ "SignalLongName" SG_ 1114 TrlrCamCalPrgs "Trailering Video Viewing Camera Information : Trailer Camera Calibration Progress";
BA_ "SignalType" SG_ 1114 VwgVwprtStsTopDnVwActv "ENM";
BA_ "SignalLongName" SG_ 1114 VwgVwprtStsTopDnVwActv "Viewing Viewport Status Top Down View Active";
BA_ "SignalType" SG_ 1114 VwgVwprtNtfnActv "ENM";
BA_ "SignalLongName" SG_ 1114 VwgVwprtNtfnActv "Viewing Viewport Notification Active";
BA_ "SignalType" SG_ 1114 VwgCtlBtnPrsncTrlrAux2 "ENM";
BA_ "SignalLongName" SG_ 1114 VwgCtlBtnPrsncTrlrAux2 "Viewing Control Button Presence Trailer Aux2";
BA_ "SignalType" SG_ 1114 VwgCtlBtnPrsncZmdBowl "ENM";
BA_ "SignalLongName" SG_ 1114 VwgCtlBtnPrsncZmdBowl "Viewing Control Button Presence Zoomed Bowl";
BA_ "SignalType" SG_ 1114 VwgCtlBtnPrsncUndrBdyRwd "ENM";
BA_ "SignalLongName" SG_ 1114 VwgCtlBtnPrsncUndrBdyRwd "Viewing Control Button Presence Underbody Rearward";
BA_ "SignalType" SG_ 1114 VwgCtlBtnPrsncUndrBdyFwdSt "ENM";
BA_ "SignalLongName" SG_ 1114 VwgCtlBtnPrsncUndrBdyFwdSt "Viewing Control Button Presence Underbody Forward Split";
BA_ "SignalType" SG_ 1114 TrlrJckKnfVisAlrtReq "ENM";
BA_ "SignalLongName" SG_ 1114 TrlrJckKnfVisAlrtReq "Trailer Jack Knife Visual Alert Request";
BA_ "SignalType" SG_ 1114 TrlrCamCalPrgs_Inv "ENM";
BA_ "SignalLongName" SG_ 1114 TrlrCamCalPrgs_Inv "Trailering Video Viewing Camera Information : Trailer Camera Calibration Progress Invalid";
BA_ "SignalType" SG_ 1984 DMPDAutoClsTmLFCstSetAval "ENM";
BA_ "SignalLongName" SG_ 1984 DMPDAutoClsTmLFCstSetAval "Delivery Mode Power Door Auto Close Time Left Front Customization Setting Available";
BA_ "SignalType" SG_ 1984 DMPDAutoClsTmLFCstAvlFlg7 "ENM";
BA_ "SignalLongName" SG_ 1984 DMPDAutoClsTmLFCstAvlFlg7 "Delivery Mode Power Door Auto Close Time Left Front Customization Availability Flag 7";
BA_ "SignalType" SG_ 1984 DMPDAutoClsTmLFCstAvlFlg6 "ENM";
BA_ "SignalLongName" SG_ 1984 DMPDAutoClsTmLFCstAvlFlg6 "Delivery Mode Power Door Auto Close Time Left Front Customization Availability Flag 6";
BA_ "SignalType" SG_ 1984 DMPDAutoClsTmLFCstAvlFlg5 "ENM";
BA_ "SignalLongName" SG_ 1984 DMPDAutoClsTmLFCstAvlFlg5 "Delivery Mode Power Door Auto Close Time Left Front Customization Availability Flag 5";
BA_ "SignalType" SG_ 1984 DMPDAutoClsTmLFCstAvlFlg4 "ENM";
BA_ "SignalLongName" SG_ 1984 DMPDAutoClsTmLFCstAvlFlg4 "Delivery Mode Power Door Auto Close Time Left Front Customization Availability Flag 4";
BA_ "SignalType" SG_ 1984 DMPDAutoClsTmLFCstAvlFlg3 "ENM";
BA_ "SignalLongName" SG_ 1984 DMPDAutoClsTmLFCstAvlFlg3 "Delivery Mode Power Door Auto Close Time Left Front Customization Availability Flag 3";
BA_ "SignalType" SG_ 1984 DMPDAutoClsTmLFCstAvlFlg2 "ENM";
BA_ "SignalLongName" SG_ 1984 DMPDAutoClsTmLFCstAvlFlg2 "Delivery Mode Power Door Auto Close Time Left Front Customization Availability Flag 2";
BA_ "SignalType" SG_ 1984 DMPDAutoClsTmLFCstAvlFlg1 "ENM";
BA_ "SignalLongName" SG_ 1984 DMPDAutoClsTmLFCstAvlFlg1 "Delivery Mode Power Door Auto Close Time Left Front Customization Availability Flag 1";
BA_ "SignalType" SG_ 1984 DMPDClsOutofPrkLFCstSetAval "ENM";
BA_ "SignalLongName" SG_ 1984 DMPDClsOutofPrkLFCstSetAval "Delivery Mode Power Door Close Out of Park Left Front Customization Setting Available";
BA_ "SignalType" SG_ 1984 DMPDClsOutofPrkLFCstAvlFlg7 "ENM";
BA_ "SignalLongName" SG_ 1984 DMPDClsOutofPrkLFCstAvlFlg7 "Delivery Mode Power Door Close Out of Park Left Front Customization Availability Flag 7";
BA_ "SignalType" SG_ 1984 DMPDClsOutofPrkLFCstAvlFlg6 "ENM";
BA_ "SignalLongName" SG_ 1984 DMPDClsOutofPrkLFCstAvlFlg6 "Delivery Mode Power Door Close Out of Park Left Front Customization Availability Flag 6";
BA_ "SignalType" SG_ 1984 DMPDClsOutofPrkLFCstAvlFlg5 "ENM";
BA_ "SignalLongName" SG_ 1984 DMPDClsOutofPrkLFCstAvlFlg5 "Delivery Mode Power Door Close Out of Park Left Front Customization Availability Flag 5";
BA_ "SignalType" SG_ 1984 DMPDClsOutofPrkLFCstAvlFlg4 "ENM";
BA_ "SignalLongName" SG_ 1984 DMPDClsOutofPrkLFCstAvlFlg4 "Delivery Mode Power Door Close Out of Park Left Front Customization Availability Flag 4";
BA_ "SignalType" SG_ 1984 DMPDClsOutofPrkLFCstAvlFlg3 "ENM";
BA_ "SignalLongName" SG_ 1984 DMPDClsOutofPrkLFCstAvlFlg3 "Delivery Mode Power Door Close Out of Park Left Front Customization Availability Flag 3";
BA_ "SignalType" SG_ 1984 DMPDClsOutofPrkLFCstAvlFlg2 "ENM";
BA_ "SignalLongName" SG_ 1984 DMPDClsOutofPrkLFCstAvlFlg2 "Delivery Mode Power Door Close Out of Park Left Front Customization Availability Flag 2";
BA_ "SignalType" SG_ 1984 DMPDClsOutofPrkLFCstAvlFlg1 "ENM";
BA_ "SignalLongName" SG_ 1984 DMPDClsOutofPrkLFCstAvlFlg1 "Delivery Mode Power Door Close Out of Park Left Front Customization Availability Flag 1";
BA_ "SignalType" SG_ 1984 DMPDDOBlkhdDrOpnLFCstSetAval "ENM";
BA_ "SignalLongName" SG_ 1984 DMPDDOBlkhdDrOpnLFCstSetAval "Delivery Mode Power Door Delayed Open after Bulkhead Door Open Left Front Customization Setting Available";
BA_ "SignalType" SG_ 1984 DMPDDOBlkhdDrOpnLFCstAvlFlg7 "ENM";
BA_ "SignalLongName" SG_ 1984 DMPDDOBlkhdDrOpnLFCstAvlFlg7 "Delivery Mode Power Door Delayed Open after Bulkhead Door Open Left Front Customization Availability Flag 7";
BA_ "SignalType" SG_ 1984 DMPDDOBlkhdDrOpnLFCstAvlFlg6 "ENM";
BA_ "SignalLongName" SG_ 1984 DMPDDOBlkhdDrOpnLFCstAvlFlg6 "Delivery Mode Power Door Delayed Open after Bulkhead Door Open Left Front Customization Availability Flag 6";
BA_ "SignalType" SG_ 1984 DMPDDOBlkhdDrOpnLFCstAvlFlg5 "ENM";
BA_ "SignalLongName" SG_ 1984 DMPDDOBlkhdDrOpnLFCstAvlFlg5 "Delivery Mode Power Door Delayed Open after Bulkhead Door Open Left Front Customization Availability Flag 5";
BA_ "SignalType" SG_ 1984 DMPDDOBlkhdDrOpnLFCstAvlFlg4 "ENM";
BA_ "SignalLongName" SG_ 1984 DMPDDOBlkhdDrOpnLFCstAvlFlg4 "Delivery Mode Power Door Delayed Open after Bulkhead Door Open Left Front Customization Availability Flag 4";
BA_ "SignalType" SG_ 1984 DMPDDOBlkhdDrOpnLFCstAvlFlg3 "ENM";
BA_ "SignalLongName" SG_ 1984 DMPDDOBlkhdDrOpnLFCstAvlFlg3 "Delivery Mode Power Door Delayed Open after Bulkhead Door Open Left Front Customization Availability Flag 3";
BA_ "SignalType" SG_ 1984 DMPDDOBlkhdDrOpnLFCstAvlFlg2 "ENM";
BA_ "SignalLongName" SG_ 1984 DMPDDOBlkhdDrOpnLFCstAvlFlg2 "Delivery Mode Power Door Delayed Open after Bulkhead Door Open Left Front Customization Availability Flag 2";
BA_ "SignalType" SG_ 1984 DMPDDOBlkhdDrOpnLFCstAvlFlg1 "ENM";
BA_ "SignalLongName" SG_ 1984 DMPDDOBlkhdDrOpnLFCstAvlFlg1 "Delivery Mode Power Door Delayed Open after Bulkhead Door Open Left Front Customization Availability Flag 1";
BA_ "SignalType" SG_ 1984 SCAOOAByKeyFobLFCstSetAval "ENM";
BA_ "SignalLongName" SG_ 1984 SCAOOAByKeyFobLFCstSetAval "Side Closure Access Open On Approach By Key Fob Left Front Customization Setting Available";
BA_ "SignalType" SG_ 1984 SCAOOAByKeyFobLFCstAvlFlg7 "ENM";
BA_ "SignalLongName" SG_ 1984 SCAOOAByKeyFobLFCstAvlFlg7 "Side Closure Access Open On Approach By Key Fob Left Front Customization Availability Flag 7";
BA_ "SignalType" SG_ 1984 SCAOOAByKeyFobLFCstAvlFlg6 "ENM";
BA_ "SignalLongName" SG_ 1984 SCAOOAByKeyFobLFCstAvlFlg6 "Side Closure Access Open On Approach By Key Fob Left Front Customization Availability Flag 6";
BA_ "SignalType" SG_ 1984 SCAOOAByKeyFobLFCstAvlFlg5 "ENM";
BA_ "SignalLongName" SG_ 1984 SCAOOAByKeyFobLFCstAvlFlg5 "Side Closure Access Open On Approach By Key Fob Left Front Customization Availability Flag 5";
BA_ "SignalType" SG_ 1984 SCAOOAByKeyFobLFCstAvlFlg4 "ENM";
BA_ "SignalLongName" SG_ 1984 SCAOOAByKeyFobLFCstAvlFlg4 "Side Closure Access Open On Approach By Key Fob Left Front Customization Availability Flag 4";
BA_ "SignalType" SG_ 1984 SCAOOAByKeyFobLFCstAvlFlg3 "ENM";
BA_ "SignalLongName" SG_ 1984 SCAOOAByKeyFobLFCstAvlFlg3 "Side Closure Access Open On Approach By Key Fob Left Front Customization Availability Flag 3";
BA_ "SignalType" SG_ 1984 SCAOOAByKeyFobLFCstAvlFlg2 "ENM";
BA_ "SignalLongName" SG_ 1984 SCAOOAByKeyFobLFCstAvlFlg2 "Side Closure Access Open On Approach By Key Fob Left Front Customization Availability Flag 2";
BA_ "SignalType" SG_ 1984 SCAOOAByKeyFobLFCstAvlFlg1 "ENM";
BA_ "SignalLongName" SG_ 1984 SCAOOAByKeyFobLFCstAvlFlg1 "Side Closure Access Open On Approach By Key Fob Left Front Customization Availability Flag 1";
BA_ "SignalType" SG_ 1984 SCAOOAByVirtKeyLFCstSetAval "ENM";
BA_ "SignalLongName" SG_ 1984 SCAOOAByVirtKeyLFCstSetAval "Side Closure Access Open On Approach By Virtual Key Left Front Customization Setting Available";
BA_ "SignalType" SG_ 1984 SCAOOAByVirtKeyLFCstAvlFlg7 "ENM";
BA_ "SignalLongName" SG_ 1984 SCAOOAByVirtKeyLFCstAvlFlg7 "Side Closure Access Open On Approach By Virtual Key Left Front Customization Availability Flag 7";
BA_ "SignalType" SG_ 1984 SCAOOAByVirtKeyLFCstAvlFlg6 "ENM";
BA_ "SignalLongName" SG_ 1984 SCAOOAByVirtKeyLFCstAvlFlg6 "Side Closure Access Open On Approach By Virtual Key Left Front Customization Availability Flag 6";
BA_ "SignalType" SG_ 1984 SCAOOAByVirtKeyLFCstAvlFlg5 "ENM";
BA_ "SignalLongName" SG_ 1984 SCAOOAByVirtKeyLFCstAvlFlg5 "Side Closure Access Open On Approach By Virtual Key Left Front Customization Availability Flag 5";
BA_ "SignalType" SG_ 1984 SCAOOAByVirtKeyLFCstAvlFlg4 "ENM";
BA_ "SignalLongName" SG_ 1984 SCAOOAByVirtKeyLFCstAvlFlg4 "Side Closure Access Open On Approach By Virtual Key Left Front Customization Availability Flag 4";
BA_ "SignalType" SG_ 1984 SCAOOAByVirtKeyLFCstAvlFlg3 "ENM";
BA_ "SignalLongName" SG_ 1984 SCAOOAByVirtKeyLFCstAvlFlg3 "Side Closure Access Open On Approach By Virtual Key Left Front Customization Availability Flag 3";
BA_ "SignalType" SG_ 1984 SCAOOAByVirtKeyLFCstAvlFlg2 "ENM";
BA_ "SignalLongName" SG_ 1984 SCAOOAByVirtKeyLFCstAvlFlg2 "Side Closure Access Open On Approach By Virtual Key Left Front Customization Availability Flag 2";
BA_ "SignalType" SG_ 1984 SCAOOAByVirtKeyLFCstAvlFlg1 "ENM";
BA_ "SignalLongName" SG_ 1984 SCAOOAByVirtKeyLFCstAvlFlg1 "Side Closure Access Open On Approach By Virtual Key Left Front Customization Availability Flag 1";
BA_ "SignalType" SG_ 1984 SCAPDBrktoClsLFCstSetAval "ENM";
BA_ "SignalLongName" SG_ 1984 SCAPDBrktoClsLFCstSetAval "Side Closure Access Power Door Brake to Close Left Front Customization Setting Available";
BA_ "SignalType" SG_ 1984 SCAPDBrktoClsLFCstAvlFlg7 "ENM";
BA_ "SignalLongName" SG_ 1984 SCAPDBrktoClsLFCstAvlFlg7 "Side Closure Access Power Door Brake to Close Left Front Customization Availability Flag 7";
BA_ "SignalType" SG_ 1984 SCAPDBrktoClsLFCstAvlFlg6 "ENM";
BA_ "SignalLongName" SG_ 1984 SCAPDBrktoClsLFCstAvlFlg6 "Side Closure Access Power Door Brake to Close Left Front Customization Availability Flag 6";
BA_ "SignalType" SG_ 1984 SCAPDBrktoClsLFCstAvlFlg5 "ENM";
BA_ "SignalLongName" SG_ 1984 SCAPDBrktoClsLFCstAvlFlg5 "Side Closure Access Power Door Brake to Close Left Front Customization Availability Flag 5";
BA_ "SignalType" SG_ 1984 SCAPDBrktoClsLFCstAvlFlg4 "ENM";
BA_ "SignalLongName" SG_ 1984 SCAPDBrktoClsLFCstAvlFlg4 "Side Closure Access Power Door Brake to Close Left Front Customization Availability Flag 4";
BA_ "SignalType" SG_ 1984 SCAPDBrktoClsLFCstAvlFlg3 "ENM";
BA_ "SignalLongName" SG_ 1984 SCAPDBrktoClsLFCstAvlFlg3 "Side Closure Access Power Door Brake to Close Left Front Customization Availability Flag 3";
BA_ "SignalType" SG_ 1984 SCAPDBrktoClsLFCstAvlFlg2 "ENM";
BA_ "SignalLongName" SG_ 1984 SCAPDBrktoClsLFCstAvlFlg2 "Side Closure Access Power Door Brake to Close Left Front Customization Availability Flag 2";
BA_ "SignalType" SG_ 1984 SCAPDBrktoClsLFCstAvlFlg1 "ENM";
BA_ "SignalLongName" SG_ 1984 SCAPDBrktoClsLFCstAvlFlg1 "Side Closure Access Power Door Brake to Close Left Front Customization Availability Flag 1";
BA_ "SignalType" SG_ 1984 SCAPDOpnMaxTrvlCstSetAval "ENM";
BA_ "SignalLongName" SG_ 1984 SCAPDOpnMaxTrvlCstSetAval "Side Closure Access Power Door Open Maximum Travel Customization Setting Available";
BA_ "SignalType" SG_ 1984 SCAPDOpnMaxTrvlCstAvlFlg7 "ENM";
BA_ "SignalLongName" SG_ 1984 SCAPDOpnMaxTrvlCstAvlFlg7 "Side Closure Access Power Door Open Maximum Travel Customization Availability Flag 7";
BA_ "SignalType" SG_ 1984 SCAPDOpnMaxTrvlCstAvlFlg6 "ENM";
BA_ "SignalLongName" SG_ 1984 SCAPDOpnMaxTrvlCstAvlFlg6 "Side Closure Access Power Door Open Maximum Travel Customization Availability Flag 6";
BA_ "SignalType" SG_ 1984 SCAPDOpnMaxTrvlCstAvlFlg5 "ENM";
BA_ "SignalLongName" SG_ 1984 SCAPDOpnMaxTrvlCstAvlFlg5 "Side Closure Access Power Door Open Maximum Travel Customization Availability Flag 5";
BA_ "SignalType" SG_ 1984 SCAPDOpnMaxTrvlCstAvlFlg4 "ENM";
BA_ "SignalLongName" SG_ 1984 SCAPDOpnMaxTrvlCstAvlFlg4 "Side Closure Access Power Door Open Maximum Travel Customization Availability Flag 4";
BA_ "SignalType" SG_ 1984 SCAPDOpnMaxTrvlCstAvlFlg3 "ENM";
BA_ "SignalLongName" SG_ 1984 SCAPDOpnMaxTrvlCstAvlFlg3 "Side Closure Access Power Door Open Maximum Travel Customization Availability Flag 3";
BA_ "SignalType" SG_ 1984 SCAPDOpnMaxTrvlCstAvlFlg2 "ENM";
BA_ "SignalLongName" SG_ 1984 SCAPDOpnMaxTrvlCstAvlFlg2 "Side Closure Access Power Door Open Maximum Travel Customization Availability Flag 2";
BA_ "SignalType" SG_ 1984 SCAPDOpnMaxTrvlCstAvlFlg1 "ENM";
BA_ "SignalLongName" SG_ 1984 SCAPDOpnMaxTrvlCstAvlFlg1 "Side Closure Access Power Door Open Maximum Travel Customization Availability Flag 1";
BA_ "SignalType" SG_ 1984 DMPDClsOutofPrkLFCstCurrSetVal "ENM";
BA_ "SignalLongName" SG_ 1984 DMPDClsOutofPrkLFCstCurrSetVal "Delivery Mode Power Door Close Out of Park Left Front Customization Current Setting Value";
BA_ "SignalType" SG_ 1984 DMPDAutoClsTmLFCstCurrSetVal "ENM";
BA_ "SignalLongName" SG_ 1984 DMPDAutoClsTmLFCstCurrSetVal "Delivery Mode Power Door Auto Close Time Left Front Customization Current Setting Value";
BA_ "SignalType" SG_ 1984 SCAPwrDrMtnLFVirtCtlAval "ENM";
BA_ "SignalLongName" SG_ 1984 SCAPwrDrMtnLFVirtCtlAval "Side Closure Access Power Door Motion Left Front Virtual Control Available";
BA_ "SignalType" SG_ 1060 PwrSdClsrLFBlckdIndOn "ENM";
BA_ "SignalLongName" SG_ 1060 PwrSdClsrLFBlckdIndOn "Power Side Closure Left Front Blocked Indication On";
BA_ "SignalType" SG_ 1060 PwrSdClsrLFServIndOn "ENM";
BA_ "SignalLongName" SG_ 1060 PwrSdClsrLFServIndOn "Power Side Closure Left Front Service Indication On";
BA_ "SignalType" SG_ 1059 PwrSdClsrLRBlckdIndOn "ENM";
BA_ "SignalLongName" SG_ 1059 PwrSdClsrLRBlckdIndOn "Power Side Closure Left Rear Blocked Indication On";
BA_ "SignalType" SG_ 1059 PwrSdClsrLRServIndOn "ENM";
BA_ "SignalLongName" SG_ 1059 PwrSdClsrLRServIndOn "Power Side Closure Left Rear Service Indication On";
BA_ "SignalLongName" SG_ 1188 DEFWVSL_S1SpdLmt "Diesel Exhaust Fluid Warning Vehicle Speed Limit : Stage 1 Vehicle Speed Limit";
BA_ "SignalLongName" SG_ 1188 DEFWVSL_S2SpdLmt "Diesel Exhaust Fluid Warning Vehicle Speed Limit : Stage 2 Vehicle Speed Limit";
BA_ "SignalLongName" SG_ 1188 DEFWVSL_S3SpdLmt "Diesel Exhaust Fluid Warning Vehicle Speed Limit : Stage 3 Vehicle Speed Limit";
BA_ "SignalLongName" SG_ 1188 FuelTotCap "Fuel Total Capacity";
BA_ "SignalLongName" SG_ 1188 FuelTotCapTnk2 "Fuel Total Capacity Tank 2";
BA_ "SignalLongName" SG_ 1188 EngOilTmp "Engine Oil Temperature";
BA_ "SignalType" SG_ 1188 EngOilTmp_Inv "ENM";
BA_ "SignalLongName" SG_ 1188 EngOilTmp_Inv "Engine Oil Temperature Invalid";
BA_ "SignalType" SG_ 1188 FuelConsmpHvyIndReq "ENM";
BA_ "SignalLongName" SG_ 1188 FuelConsmpHvyIndReq "Fuel Consumption Heavy Indication Request";
BA_ "SignalType" SG_ 1792 DslExFldTpWrngIndRq "ENM";
BA_ "SignalLongName" SG_ 1792 DslExFldTpWrngIndRq "Diesel Exhaust Information : Diesel Exhaust Fluid Tampering Warning Indication Request";
BA_ "SignalType" SG_ 1792 DslExFldCnWrngIndRq "ENM";
BA_ "SignalLongName" SG_ 1792 DslExFldCnWrngIndRq "Diesel Exhaust Information : Diesel Exhaust Fluid Consumption Monitoring Warning Indication Request";
BA_ "SignalType" SG_ 1792 DslExhFldQlyWrngIReq "ENM";
BA_ "SignalLongName" SG_ 1792 DslExhFldQlyWrngIReq "Diesel Exhaust Information : Diesel Exhaust Fluid Quality Warning Indication Request";
BA_ "SignalType" SG_ 1792 DslExNxEmWrngIndRq "ENM";
BA_ "SignalLongName" SG_ 1792 DslExNxEmWrngIndRq "Diesel Exhaust Information : Diesel Exhaust NOx Emissions Too High Warning Indication Request";
BA_ "SignalLongName" SG_ 1792 DslExhFldRmnDist "Diesel Exhaust Information : Diesel Exhaust Fluid Remaining Distance";
BA_ "SignalType" SG_ 1792 DslExhFldRmnDist_Inv "ENM";
BA_ "SignalLongName" SG_ 1792 DslExhFldRmnDist_Inv "Diesel Exhaust Information : Diesel Exhaust Fluid Remaining Distance Invalid";
BA_ "SignalLongName" SG_ 1792 DslExhFluidDistTIndcmt "Diesel Exhaust Information : Diesel Exhaust Fluid Distance To Inducement";
BA_ "SignalType" SG_ 1792 DslExhFldWrngIdRqER "ENM";
BA_ "SignalLongName" SG_ 1792 DslExhFldWrngIdRqER "Diesel Exhaust Information : Diesel Exhaust Fluid Level Warning Indication Request Extended Range";
BA_ "SignalType" SG_ 1792 ASIRI_Ind05 "ENM";
BA_ "SignalLongName" SG_ 1792 ASIRI_Ind05 "Auto Stop Inhibit Reason Indication : Indication 5";
BA_ "SignalType" SG_ 1792 ASIRI_Ind04 "ENM";
BA_ "SignalLongName" SG_ 1792 ASIRI_Ind04 "Auto Stop Inhibit Reason Indication : Indication 4";
BA_ "SignalType" SG_ 1792 ASIRI_Ind03 "ENM";
BA_ "SignalLongName" SG_ 1792 ASIRI_Ind03 "Auto Stop Inhibit Reason Indication : Indication 3";
BA_ "SignalType" SG_ 1792 ASIRI_Ind02 "ENM";
BA_ "SignalLongName" SG_ 1792 ASIRI_Ind02 "Auto Stop Inhibit Reason Indication : Indication 2";
BA_ "SignalType" SG_ 1792 ASIRI_Ind01 "ENM";
BA_ "SignalLongName" SG_ 1792 ASIRI_Ind01 "Auto Stop Inhibit Reason Indication : Indication 1";
BA_ "SignalType" SG_ 1792 FstIdlModeIndReq "ENM";
BA_ "SignalLongName" SG_ 1792 FstIdlModeIndReq "Fast Idle Mode Indication Request";
BA_ "SignalType" SG_ 1792 CkFlFilrCapIO "ENM";
BA_ "SignalLongName" SG_ 1792 CkFlFilrCapIO "Check Fuel Filler Cap Indication On";
BA_ "SignalType" SG_ 1792 CbnHtrWrmUpIndOn "ENM";
BA_ "SignalLongName" SG_ 1792 CbnHtrWrmUpIndOn "Cabin Heater Warm Up Indication On";
BA_ "SignalType" SG_ 1792 AppCltchAutSrtIO "ENM";
BA_ "SignalLongName" SG_ 1792 AppCltchAutSrtIO "Apply Clutch For Automatic Start Indication On";
BA_ "SignalType" SG_ 1792 ASIRI_Ind08 "ENM";
BA_ "SignalLongName" SG_ 1792 ASIRI_Ind08 "Auto Stop Inhibit Reason Indication : Indication 8";
BA_ "SignalType" SG_ 1792 ASIRI_Ind07 "ENM";
BA_ "SignalLongName" SG_ 1792 ASIRI_Ind07 "Auto Stop Inhibit Reason Indication : Indication 7";
BA_ "SignalType" SG_ 1792 ASIRI_Ind06 "ENM";
BA_ "SignalLongName" SG_ 1792 ASIRI_Ind06 "Auto Stop Inhibit Reason Indication : Indication 6";
BA_ "SignalType" SG_ 1273 PTOSet1SpdCstCurrSetVal "ENM";
BA_ "SignalLongName" SG_ 1273 PTOSet1SpdCstCurrSetVal "Power Take Off Set 1 Speed Customization Current Setting Value";
BA_ "SignalType" SG_ 1273 PTOEngRunTmrCstCurrSetVal "ENM";
BA_ "SignalLongName" SG_ 1273 PTOEngRunTmrCstCurrSetVal "Power Take Off Engine Run Timer Customization Current Setting Value";
BA_ "SignalType" SG_ 1273 MnlTrnsIndReq "ENM";
BA_ "SignalLongName" SG_ 1273 MnlTrnsIndReq "Manual Transmission Indication Request";
BA_ "SignalType" SG_ 1273 EngAirFiltMonSts "ENM";
BA_ "SignalLongName" SG_ 1273 EngAirFiltMonSts "Engine Air Filter Monitor Status";
BA_ "SignalType" SG_ 1273 PTOSet2SpdCstCurrSetVal "ENM";
BA_ "SignalLongName" SG_ 1273 PTOSet2SpdCstCurrSetVal "Power Take Off Set 2 Speed Customization Current Setting Value";
BA_ "SignalType" SG_ 1273 PTOTpStpSpdCstCurrSetVal "ENM";
BA_ "SignalLongName" SG_ 1273 PTOTpStpSpdCstCurrSetVal "Power Take Off Tap Step Speed Customization Current Setting Value";
BA_ "SignalType" SG_ 1273 PTOStndbySpdCstCurrSetVal "ENM";
BA_ "SignalLongName" SG_ 1273 PTOStndbySpdCstCurrSetVal "Power Take Off Standby Speed Customization Current Setting Value";
BA_ "SignalType" SG_ 1273 EngHtStpEngIO "ENM";
BA_ "SignalLongName" SG_ 1273 EngHtStpEngIO "Engine Hot / Stop Engine Indication On";
BA_ "SignalType" SG_ 1273 EngHtFlEnrchmntIO "ENM";
BA_ "SignalLongName" SG_ 1273 EngHtFlEnrchmntIO "Engine Hot Fuel Enrichment Indication On";
BA_ "SignalType" SG_ 1273 PTOModeCstCurrSetVal "ENM";
BA_ "SignalLongName" SG_ 1273 PTOModeCstCurrSetVal "Power Take Off Mode Customization Current Setting Value";
BA_ "SignalType" SG_ 1273 PTOEngmntStsInd "ENM";
BA_ "SignalLongName" SG_ 1273 PTOEngmntStsInd "Power Take Off Engagement Status Indication";
BA_ "SignalType" SG_ 1273 PTOEngSpdTypCstCurrSetVal "ENM";
BA_ "SignalLongName" SG_ 1273 PTOEngSpdTypCstCurrSetVal "Power Take Off Engine Speed Type Customization Current Setting Value";
BA_ "SignalType" SG_ 1273 EngWtrInFlIO "ENM";
BA_ "SignalLongName" SG_ 1273 EngWtrInFlIO "Engine Water In Fuel Indication On";
BA_ "SignalType" SG_ 1273 EngSpdLmtnMdAct "ENM";
BA_ "SignalLongName" SG_ 1273 EngSpdLmtnMdAct "Engine Speed Limitation Mode Active";
BA_ "SignalType" SG_ 1273 EngShtdwnPndgIO "ENM";
BA_ "SignalLongName" SG_ 1273 EngShtdwnPndgIO "Engine Shutdown Pending Indication On";
BA_ "SignalType" SG_ 1273 EngOilStrvtnIO "ENM";
BA_ "SignalLongName" SG_ 1273 EngOilStrvtnIO "Engine Oil Starvation Indication On";
BA_ "SignalType" SG_ 1273 EngOilPrsLwIO "ENM";
BA_ "SignalLongName" SG_ 1273 EngOilPrsLwIO "Engine Oil Pressure Low Indication On";
BA_ "SignalType" SG_ 1273 EngOilLvlLwIO "ENM";
BA_ "SignalLongName" SG_ 1273 EngOilLvlLwIO "Engine Oil Level Low Indication On";
BA_ "SignalType" SG_ 1273 EngOilHotIO "ENM";
BA_ "SignalLongName" SG_ 1273 EngOilHotIO "Engine Oil Hot Indication On";
BA_ "SignalType" SG_ 1273 EngOilChngIO "ENM";
BA_ "SignalLongName" SG_ 1273 EngOilChngIO "Engine Oil Change Indication On";
BA_ "SignalType" SG_ 1273 PTOMblModeTransInGrIndOn "ENM";
BA_ "SignalLongName" SG_ 1273 PTOMblModeTransInGrIndOn "Power Take Off Mobile Mode Transmission In Gear Indication On";
BA_ "SignalType" SG_ 1273 PTOEngUpnBrkRelIndOn "ENM";
BA_ "SignalLongName" SG_ 1273 PTOEngUpnBrkRelIndOn "Power Take Off Engage Upon Brake Release Indication On";
BA_ "SignalType" SG_ 1273 PTOEngSpdTypCstSetAval "ENM";
BA_ "SignalLongName" SG_ 1273 PTOEngSpdTypCstSetAval "Power Take Off Engine Speed Type Customization Setting Available";
BA_ "SignalType" SG_ 1273 PTOEngRunTmrCstSetAval "ENM";
BA_ "SignalLongName" SG_ 1273 PTOEngRunTmrCstSetAval "Power Take Off Engine Run Timer Customization Setting Available";
BA_ "SignalType" SG_ 1273 PTODisengCruzCtlIndOn "ENM";
BA_ "SignalLongName" SG_ 1273 PTODisengCruzCtlIndOn "Power Take Off Disengage Cruise Control Indication On";
BA_ "SignalType" SG_ 1273 PTOAccelUpnBrkRelIndOn "ENM";
BA_ "SignalLongName" SG_ 1273 PTOAccelUpnBrkRelIndOn "Power Take Off Acceleration Upon Brake Release Indication On";
BA_ "SignalType" SG_ 1273 PTExPrtclFltrWrnIO "ENM";
BA_ "SignalLongName" SG_ 1273 PTExPrtclFltrWrnIO "Powertrain Exhaust Particle Filter Warning Indication On";
BA_ "SignalType" SG_ 1273 PTExPrtclFltrWrn2IO "ENM";
BA_ "SignalLongName" SG_ 1273 PTExPrtclFltrWrn2IO "Powertrain Exhaust Particle Filter Warning 2 Indication On";
BA_ "SignalType" SG_ 1273 PTOSet2SpdCstSetAval "ENM";
BA_ "SignalLongName" SG_ 1273 PTOSet2SpdCstSetAval "Power Take Off Set 2 Speed Customization Setting Available";
BA_ "SignalType" SG_ 1273 PTOSet1SpdCstSetAval "ENM";
BA_ "SignalLongName" SG_ 1273 PTOSet1SpdCstSetAval "Power Take Off Set 1 Speed Customization Setting Available";
BA_ "SignalType" SG_ 1273 PTOServIndOn "ENM";
BA_ "SignalLongName" SG_ 1273 PTOServIndOn "Power Take Off Service Indication On";
BA_ "SignalType" SG_ 1273 PTORelBrkPedIndOn "ENM";
BA_ "SignalLongName" SG_ 1273 PTORelBrkPedIndOn "Power Take Off Release Brake Pedal Indication On";
BA_ "SignalType" SG_ 1273 PTORelAccelPedIndOn "ENM";
BA_ "SignalLongName" SG_ 1273 PTORelAccelPedIndOn "Power Take Off Release Accelerator Pedal Indication On";
BA_ "SignalType" SG_ 1273 PTORdcEngSpdIndOn "ENM";
BA_ "SignalLongName" SG_ 1273 PTORdcEngSpdIndOn "Power Take Off Reduce Engine Speed Indication On";
BA_ "SignalType" SG_ 1273 PTOPrssAndRelBrkPedIndOn "ENM";
BA_ "SignalLongName" SG_ 1273 PTOPrssAndRelBrkPedIndOn "Power Take Off Press And Release Brake Pedal Indication On";
BA_ "SignalType" SG_ 1273 PTOModeCstSetAval "ENM";
BA_ "SignalLongName" SG_ 1273 PTOModeCstSetAval "Power Take Off Mode Customization Setting Available";
BA_ "SignalType" SG_ 1273 TrnsSkpShftIO "ENM";
BA_ "SignalLongName" SG_ 1273 TrnsSkpShftIO "Transmission Skip Shift Indication On";
BA_ "SignalType" SG_ 1273 ServFuelSysTrnsfrPmpIO "ENM";
BA_ "SignalLongName" SG_ 1273 ServFuelSysTrnsfrPmpIO "Service Fuel System Transfer Pump Indication On";
BA_ "SignalType" SG_ 1273 PTWrmgWtToShftIO "ENM";
BA_ "SignalLongName" SG_ 1273 PTWrmgWtToShftIO "Powertrain Warming Wait to Shift Indication On";
BA_ "SignalType" SG_ 1273 PTOTransInGrIndOn "ENM";
BA_ "SignalLongName" SG_ 1273 PTOTransInGrIndOn "Power Take Off Transmission In Gear Indication On";
BA_ "SignalType" SG_ 1273 PTOTpStpSpdCstSetAval "ENM";
BA_ "SignalLongName" SG_ 1273 PTOTpStpSpdCstSetAval "Power Take Off Tap Step Speed Customization Setting Available";
BA_ "SignalType" SG_ 1273 PTOStndbySpdCstSetAval "ENM";
BA_ "SignalLongName" SG_ 1273 PTOStndbySpdCstSetAval "Power Take Off Standby Speed Customization Setting Available";
BA_ "SignalType" SG_ 1273 PTOSetPrkBrkIndOn "ENM";
BA_ "SignalLongName" SG_ 1273 PTOSetPrkBrkIndOn "Power Take Off Set Park Brake Indication On";
BA_ "SignalType" SG_ 1187 OTARC_RejCrdntnECP_X1 "ENM";
BA_ "SignalLongName" SG_ 1187 OTARC_RejCrdntnECP_X1 "Over The Air Reject Coordination : Reject Coordination ECP_X1";
BA_ "SignalType" SG_ 1187 OTARC_RejCrdntnECP_S "ENM";
BA_ "SignalLongName" SG_ 1187 OTARC_RejCrdntnECP_S "Over The Air Reject Coordination : Reject Coordination ECP_S";
BA_ "SignalType" SG_ 1187 OTARC_RejCrdntnECP_MC "ENM";
BA_ "SignalLongName" SG_ 1187 OTARC_RejCrdntnECP_MC "Over The Air Reject Coordination : Reject Coordination ECP_MC";
BA_ "SignalType" SG_ 1187 OTARC_RejCrdntnECM "ENM";
BA_ "SignalLongName" SG_ 1187 OTARC_RejCrdntnECM "Over The Air Reject Coordination : Reject Coordination ECM";
BA_ "SignalType" SG_ 1187 OTARC_RejCrdntnEBCM "ENM";
BA_ "SignalLongName" SG_ 1187 OTARC_RejCrdntnEBCM "Over The Air Reject Coordination : Reject Coordination EBCM";
BA_ "SignalType" SG_ 1187 OTARC_RejCrdntnBSM_MH "ENM";
BA_ "SignalLongName" SG_ 1187 OTARC_RejCrdntnBSM_MH "Over The Air Reject Coordination : Reject Coordination BSM_MH";
BA_ "SignalType" SG_ 1187 OTARC_RejCrdntnBSM "ENM";
BA_ "SignalLongName" SG_ 1187 OTARC_RejCrdntnBSM "Over The Air Reject Coordination : Reject Coordination BSM";
BA_ "SignalType" SG_ 1187 OTARC_RejCrdntnBCM "ENM";
BA_ "SignalLongName" SG_ 1187 OTARC_RejCrdntnBCM "Over The Air Reject Coordination : Reject Coordination BCM";
BA_ "SignalType" SG_ 1187 OTARC_RejCrdntnLIB_48V "ENM";
BA_ "SignalLongName" SG_ 1187 OTARC_RejCrdntnLIB_48V "Over The Air Reject Coordination : Reject Coordination LIB_48V";
BA_ "SignalType" SG_ 1187 OTARC_RejCrdntnECP_E "ENM";
BA_ "SignalLongName" SG_ 1187 OTARC_RejCrdntnECP_E "Over The Air Reject Coordination : Reject Coordination ECP_E";
BA_ "SignalType" SG_ 1187 OTARC_RejCrdntnVECM "ENM";
BA_ "SignalLongName" SG_ 1187 OTARC_RejCrdntnVECM "Over The Air Reject Coordination : Reject Coordination VECM";
BA_ "SignalType" SG_ 1187 OTARC_RejCrdntnECP_S2 "ENM";
BA_ "SignalLongName" SG_ 1187 OTARC_RejCrdntnECP_S2 "Over The Air Reject Coordination : Reject Coordination ECP_S2";
BA_ "SignalType" SG_ 1187 OTARC_RejCrdntnVICM "ENM";
BA_ "SignalLongName" SG_ 1187 OTARC_RejCrdntnVICM "Over The Air Reject Coordination : Reject Coordination VICM";
BA_ "SignalType" SG_ 1187 OTARC_RejCrdntnSBM "ENM";
BA_ "SignalLongName" SG_ 1187 OTARC_RejCrdntnSBM "Over The Air Reject Coordination : Reject Coordination SBM";
BA_ "SignalType" SG_ 1187 OTARC_RejCrdntnCGM "ENM";
BA_ "SignalLongName" SG_ 1187 OTARC_RejCrdntnCGM "Over The Air Reject Coordination : Reject Coordination CGM";
BA_ "SignalType" SG_ 1187 OTARC_RejCrdntnECP_X2 "ENM";
BA_ "SignalLongName" SG_ 1187 OTARC_RejCrdntnECP_X2 "Over The Air Reject Coordination : Reject Coordination ECP_X2";
BA_ "SignalType" SG_ 1187 OTARC_RejCrdntnECU_27 "ENM";
BA_ "SignalLongName" SG_ 1187 OTARC_RejCrdntnECU_27 "Over The Air Reject Coordination : Reject Coordination ECU_27";
BA_ "SignalType" SG_ 1187 OTARC_RejCrdntnECU_26 "ENM";
BA_ "SignalLongName" SG_ 1187 OTARC_RejCrdntnECU_26 "Over The Air Reject Coordination : Reject Coordination ECU_26";
BA_ "SignalType" SG_ 1187 OTARC_RejCrdntnECU_25 "ENM";
BA_ "SignalLongName" SG_ 1187 OTARC_RejCrdntnECU_25 "Over The Air Reject Coordination : Reject Coordination ECU_25";
BA_ "SignalType" SG_ 1187 OTARC_RejCrdntnECU_24 "ENM";
BA_ "SignalLongName" SG_ 1187 OTARC_RejCrdntnECU_24 "Over The Air Reject Coordination : Reject Coordination ECU_24";
BA_ "SignalType" SG_ 1187 OTARC_RejCrdntnECU_23 "ENM";
BA_ "SignalLongName" SG_ 1187 OTARC_RejCrdntnECU_23 "Over The Air Reject Coordination : Reject Coordination ECU_23";
BA_ "SignalType" SG_ 1187 OTARC_RejCrdntnECU_22 "ENM";
BA_ "SignalLongName" SG_ 1187 OTARC_RejCrdntnECU_22 "Over The Air Reject Coordination : Reject Coordination ECU_22";
BA_ "SignalType" SG_ 1187 OTARC_RejCrdntnECU_21 "ENM";
BA_ "SignalLongName" SG_ 1187 OTARC_RejCrdntnECU_21 "Over The Air Reject Coordination : Reject Coordination ECU_21";
BA_ "SignalType" SG_ 1187 OTARC_RejCrdntnECU_20 "ENM";
BA_ "SignalLongName" SG_ 1187 OTARC_RejCrdntnECU_20 "Over The Air Reject Coordination : Reject Coordination ECU_20";
BA_ "SignalType" SG_ 1187 OTARC_RejCrdntnTCM "ENM";
BA_ "SignalLongName" SG_ 1187 OTARC_RejCrdntnTCM "Over The Air Reject Coordination : Reject Coordination TCM";
BA_ "SignalType" SG_ 1187 OTARC_RejCrdntnICCM "ENM";
BA_ "SignalLongName" SG_ 1187 OTARC_RejCrdntnICCM "Over The Air Reject Coordination : Reject Coordination ICCM";
BA_ "SignalType" SG_ 1187 OTARC_RejCrdntnFICM "ENM";
BA_ "SignalLongName" SG_ 1187 OTARC_RejCrdntnFICM "Over The Air Reject Coordination : Reject Coordination FICM";
BA_ "SignalType" SG_ 1187 OTARC_RejCrdntnECU_32 "ENM";
BA_ "SignalLongName" SG_ 1187 OTARC_RejCrdntnECU_32 "Over The Air Reject Coordination : Reject Coordination ECU_32";
BA_ "SignalType" SG_ 1187 OTARC_RejCrdntnECU_31 "ENM";
BA_ "SignalLongName" SG_ 1187 OTARC_RejCrdntnECU_31 "Over The Air Reject Coordination : Reject Coordination ECU_31";
BA_ "SignalType" SG_ 1187 OTARC_RejCrdntnECU_30 "ENM";
BA_ "SignalLongName" SG_ 1187 OTARC_RejCrdntnECU_30 "Over The Air Reject Coordination : Reject Coordination ECU_30";
BA_ "SignalType" SG_ 1187 OTARC_RejCrdntnECU_29 "ENM";
BA_ "SignalLongName" SG_ 1187 OTARC_RejCrdntnECU_29 "Over The Air Reject Coordination : Reject Coordination ECU_29";
BA_ "SignalType" SG_ 1187 OTARC_RejCrdntnECU_28 "ENM";
BA_ "SignalLongName" SG_ 1187 OTARC_RejCrdntnECU_28 "Over The Air Reject Coordination : Reject Coordination ECU_28";
BA_ "SignalLongName" SG_ 720 PrplDispBatPwr "Propulsion Display Battery Power";
BA_ "SignalLongName" SG_ 720 PrplDispEngPwr "Propulsion Display Engine Power";
BA_ "SignalType" SG_ 720 PrplDispBatPwr_Inv "ENM";
BA_ "SignalLongName" SG_ 720 PrplDispBatPwr_Inv "Propulsion Display Battery Power Invalid";
BA_ "SignalType" SG_ 720 PrplDispBatPwr_DuD "ENM";
BA_ "SignalLongName" SG_ 720 PrplDispBatPwr_DuD "Propulsion Display Battery Power Don't Use Data";
BA_ "SignalLongName" SG_ 720 PrplDispBatTrq "Propulsion Display Battery Torque";
BA_ "SignalType" SG_ 720 PrplDispEngPwr_Inv "ENM";
BA_ "SignalLongName" SG_ 720 PrplDispEngPwr_Inv "Propulsion Display Engine Power Invalid";
BA_ "SignalType" SG_ 720 PrplDispEngPwr_DuD "ENM";
BA_ "SignalLongName" SG_ 720 PrplDispEngPwr_DuD "Propulsion Display Engine Power Don't Use Data";
BA_ "SignalLongName" SG_ 720 BatPrplDispTrqLvlPct "Battery Propulsion Display Torque Level Percent";
BA_ "SignalType" SG_ 720 BatPrplDispTrqLvlPct_DuD "ENM";
BA_ "SignalLongName" SG_ 720 BatPrplDispTrqLvlPct_DuD "Battery Propulsion Display Torque Level Percent Don't Use Data";
BA_ "SignalType" SG_ 720 PrplDispBatTrq_Inv "ENM";
BA_ "SignalLongName" SG_ 720 PrplDispBatTrq_Inv "Propulsion Display Battery Torque Invalid";
BA_ "SignalType" SG_ 720 PrplDispBatTrq_DuD "ENM";
BA_ "SignalLongName" SG_ 720 PrplDispBatTrq_DuD "Propulsion Display Battery Torque Don't Use Data";
BA_ "SignalLongName" SG_ 720 InstDrvEff "Instantaneous Drive Efficiency";
BA_ "SignalLongName" SG_ 1797 CustNonUsblSOC "Customer Non Usable State of Charge";
BA_ "SignalLongName" SG_ 1797 CustUsblSOC "Customer Usable State of Charge";
BA_ "SignalType" SG_ 1797 CustNonUsblSOC_Inv "ENM";
BA_ "SignalLongName" SG_ 1797 CustNonUsblSOC_Inv "Customer Non Usable State of Charge Invalid";
BA_ "SignalType" SG_ 1797 CustNonUsblSOC_DuD "ENM";
BA_ "SignalLongName" SG_ 1797 CustNonUsblSOC_DuD "Customer Non Usable State of Charge Don't Use Data";
BA_ "SignalLongName" SG_ 1797 CustNonUsblSOCDispLvl "Customer Non Usable State of Charge Display Level";
BA_ "SignalType" SG_ 1797 CustUsblSOC_Inv "ENM";
BA_ "SignalLongName" SG_ 1797 CustUsblSOC_Inv "Customer Usable State of Charge Invalid";
BA_ "SignalType" SG_ 1797 CustUsblSOC_DuD "ENM";
BA_ "SignalLongName" SG_ 1797 CustUsblSOC_DuD "Customer Usable State of Charge Don't Use Data";
BA_ "SignalLongName" SG_ 1797 BatPrplDispPwrLvlPct "Battery Propulsion Display Power Level Percent";
BA_ "SignalType" SG_ 1797 BatPrplDispPwrLvlPct_DuD "ENM";
BA_ "SignalLongName" SG_ 1797 BatPrplDispPwrLvlPct_DuD "Battery Propulsion Display Power Level Percent Don't Use Data";
BA_ "SignalLongName" SG_ 1497 EAWDMPTR_Secs "Electric All Wheel Drive Maximum Power Time Remaining : Seconds";
BA_ "SignalLongName" SG_ 1497 EAWDMPTR_Mins "Electric All Wheel Drive Maximum Power Time Remaining : Minutes";
BA_ "SignalLongName" SG_ 1497 ElecMtrATach "Electric Motor A Tachometer";
BA_ "SignalType" SG_ 1497 ElecMtrATach_Inv "ENM";
BA_ "SignalLongName" SG_ 1497 ElecMtrATach_Inv "Electric Motor A Tachometer Invalid";
BA_ "SignalType" SG_ 1497 ElecMtrATach_DuD "ENM";
BA_ "SignalLongName" SG_ 1497 ElecMtrATach_DuD "Electric Motor A Tachometer Don't Use Data";
BA_ "SignalType" SG_ 1497 HiVltgBatAvgTemp_DuD "ENM";
BA_ "SignalLongName" SG_ 1497 HiVltgBatAvgTemp_DuD "High Voltage Battery Average Temperature Don't Use Data";
BA_ "SignalLongName" SG_ 1497 HiVltgBatAvgTemp "High Voltage Battery Average Temperature";
BA_ "SignalLongName" SG_ 1497 DischrgPwrLtdDispPct "Discharge Power Limited Display Percent";
BA_ "SignalType" SG_ 1497 HiVltgBatAvgTemp_Inv "ENM";
BA_ "SignalLongName" SG_ 1497 HiVltgBatAvgTemp_Inv "High Voltage Battery Average Temperature Invalid";
BA_ "SignalLongName" SG_ 1497 EngPrplDispPwrLvlPct "Engine Propulsion Display Power Level Percent";
BA_ "SignalType" SG_ 1497 EngPrplDispPwrLvlPct_DuD "ENM";
BA_ "SignalLongName" SG_ 1497 EngPrplDispPwrLvlPct_DuD "Engine Propulsion Display Power Level Percent Don't Use Data";
BA_ "SignalLongName" SG_ 1497 EstdEleclPrplCpblty "Estimated Electrical Propulsion Capability";
BA_ "SignalType" SG_ 1497 EngRnngDueToVehSpdIndOn "ENM";
BA_ "SignalLongName" SG_ 1497 EngRnngDueToVehSpdIndOn "Engine Running Due to Vehicle Speed Indication On";
BA_ "SignalType" SG_ 1497 ElecAllWhlDrvIndOn "ENM";
BA_ "SignalLongName" SG_ 1497 ElecAllWhlDrvIndOn "Electric All Wheel Drive Indication On";
BA_ "SignalType" SG_ 1497 DischrgPwrLtdIndOn "ENM";
BA_ "SignalLongName" SG_ 1497 DischrgPwrLtdIndOn "Discharge Power Limited Indication On";
BA_ "SignalType" SG_ 1497 DischrgPwrLtdDispPctVsbl "ENM";
BA_ "SignalLongName" SG_ 1497 DischrgPwrLtdDispPctVsbl "Discharge Power Limited Display Percent Visible";
BA_ "SignalType" SG_ 1497 HiVltgBatLmtnDueToTempInd "ENM";
BA_ "SignalLongName" SG_ 1497 HiVltgBatLmtnDueToTempInd "High Voltage Battery Limitation Due to Temperature Indication";
BA_ "SignalLongName" SG_ 1268 HTD1_DistTrvld "Hybrid Trip Data 1 : Distance Traveled";
BA_ "SignalLongName" SG_ 1268 HTD1_FuelAvdd "Hybrid Trip Data 1 : Fuel Avoided";
BA_ "SignalType" SG_ 1268 HybModeDisp "ENM";
BA_ "SignalLongName" SG_ 1268 HybModeDisp "Hybrid Mode Display";
BA_ "SignalType" SG_ 1268 HTD1_FuelAvdd_DuD "ENM";
BA_ "SignalLongName" SG_ 1268 HTD1_FuelAvdd_DuD "Hybrid Trip Data 1 : Fuel Avoided Don't Use Data";
BA_ "SignalType" SG_ 1268 InstnsFuelEconHybOvrrdReq "ENM";
BA_ "SignalLongName" SG_ 1268 InstnsFuelEconHybOvrrdReq "Instantaneous Fuel Economy Hybrid Override Request";
BA_ "SignalType" SG_ 1268 HybModeDispVehCfg "ENM";
BA_ "SignalLongName" SG_ 1268 HybModeDispVehCfg "Hybrid Mode Display Vehicle Configuration";
BA_ "SignalType" SG_ 1268 HiVltgChrgrSysSts "ENM";
BA_ "SignalLongName" SG_ 1268 HiVltgChrgrSysSts "High Voltage Charger System Status";
BA_ "SignalType" SG_ 1268 HybShfToPrkIndOn "ENM";
BA_ "SignalLongName" SG_ 1268 HybShfToPrkIndOn "Hybrid Shift to Park Indication On";
BA_ "SignalType" SG_ 1268 HiVltgSysDsbld "ENM";
BA_ "SignalLongName" SG_ 1268 HiVltgSysDsbld "High Voltage System Disabled";
BA_ "SignalType" SG_ 1268 JmpStrtSts "ENM";
BA_ "SignalLongName" SG_ 1268 JmpStrtSts "Jump Start Status";
BA_ "SignalLongName" SG_ 1798 HTD2_BatEngyDplyd "Hybrid Trip Data 2 : Battery Energy Deployed";
BA_ "SignalLongName" SG_ 1798 HTD2_BatEngyRegntd "Hybrid Trip Data 2 : Battery Energy Regenerated";
BA_ "SignalLongName" SG_ 1798 PrplDispTotPwr "Propulsion Display Total Power";
BA_ "SignalType" SG_ 1798 PrplDispTotPwr_DuD "ENM";
BA_ "SignalLongName" SG_ 1798 PrplDispTotPwr_DuD "Propulsion Display Total Power Don't Use Data";
BA_ "SignalLongName" SG_ 1798 PrplCpbltyDispOprtgPstn "Propulsion Capability Display Operating Position";
BA_ "SignalType" SG_ 1798 PrplDispTotPwr_Inv "ENM";
BA_ "SignalLongName" SG_ 1798 PrplDispTotPwr_Inv "Propulsion Display Total Power Invalid";
BA_ "SignalType" SG_ 1798 ServHybSysIndOn "ENM";
BA_ "SignalLongName" SG_ 1798 ServHybSysIndOn "Service Hybrid System Indication On";
BA_ "SignalType" SG_ 1798 RegenPwrLimdIndOn "ENM";
BA_ "SignalLongName" SG_ 1798 RegenPwrLimdIndOn "Regenerative Power Limited Indication On";
BA_ "SignalType" SG_ 1798 RegenPwrLimdDispPctVsbl "ENM";
BA_ "SignalLongName" SG_ 1798 RegenPwrLimdDispPctVsbl "Regenerative Power Limited Display Percent Visible";
BA_ "SignalType" SG_ 1798 PrplDispTotPwrUntDisp "ENM";
BA_ "SignalLongName" SG_ 1798 PrplDispTotPwrUntDisp "Propulsion Display Total Power Unit Display";
BA_ "SignalType" SG_ 1798 LossOfPrplIndOn "ENM";
BA_ "SignalLongName" SG_ 1798 LossOfPrplIndOn "Loss Of Propulsion Indication On";
BA_ "SignalType" SG_ 1798 ServHiVltgBatIndReq "ENM";
BA_ "SignalLongName" SG_ 1798 ServHiVltgBatIndReq "Service High Voltage Battery Indication Request";
BA_ "SignalLongName" SG_ 1267 BrkPadLifeFrtDistRmn "Brake Pad Life Status Information : Brake Pad Life Front Distance Remaining";
BA_ "SignalLongName" SG_ 1267 BrkPadLifeRrDistRmn "Brake Pad Life Status Information : Brake Pad Life Rear Distance Remaining";
BA_ "SignalType" SG_ 1267 BrkPadLifeFrtDistWrnIndReq "ENM";
BA_ "SignalLongName" SG_ 1267 BrkPadLifeFrtDistWrnIndReq "Brake Pad Life Status Information : Brake Pad Life Front Distance Warning Indication Request";
BA_ "SignalLongName" SG_ 1267 ESCSpdLtdCntdwnVal "Electronic Stability Control Information : Electronic Stability Control Speed Limited Countdown Value";
BA_ "SignalType" SG_ 1267 BrkPadLifeStsIndReq "ENM";
BA_ "SignalLongName" SG_ 1267 BrkPadLifeStsIndReq "Brake Pad Life Status Information : Brake Pad Life Status Indication Request";
BA_ "SignalType" SG_ 1267 BrkPadLifeRrDistWrnIndReq "ENM";
BA_ "SignalLongName" SG_ 1267 BrkPadLifeRrDistWrnIndReq "Brake Pad Life Status Information : Brake Pad Life Rear Distance Warning Indication Request";
BA_ "SignalLongName" SG_ 1267 ESCVehTopSpdLimDispVal "Electronic Stability Control Information : Electronic Stability Control Vehicle Top Speed Limit Display Value";
BA_ "SignalType" SG_ 1267 ESCSpdLtdIndReq "ENM";
BA_ "SignalLongName" SG_ 1267 ESCSpdLtdIndReq "Electronic Stability Control Information : Electronic Stability Control Speed Limited Indication Request";
BA_ "SignalType" SG_ 1267 HillDscntCtlRdcVehSpdIndOn "ENM";
BA_ "SignalLongName" SG_ 1267 HillDscntCtlRdcVehSpdIndOn "Hill Descent Control Information : Hill Descent Control Reduce Vehicle Speed Indication On";
BA_ "SignalType" SG_ 1267 HillDscntCtlDispActvIndOn "ENM";
BA_ "SignalLongName" SG_ 1267 HillDscntCtlDispActvIndOn "Hill Descent Control Information : Hill Descent Control Display Active Indication On";
BA_ "SignalLongName" SG_ 1267 HillDscntCtlTgtSetSpd "Hill Descent Control Information : Hill Descent Control Target Set Speed";
BA_ "SignalType" SG_ 1267 BrkPadLifeFrtCnfrmRplcmtIndOn "ENM";
BA_ "SignalLongName" SG_ 1267 BrkPadLifeFrtCnfrmRplcmtIndOn "Brake Pad Life Front Confirm Replacement Indication On";
BA_ "SignalType" SG_ 1267 BrkOvrhtdIndOn "ENM";
BA_ "SignalLongName" SG_ 1267 BrkOvrhtdIndOn "Brakes Overheated Indication On";
BA_ "SignalType" SG_ 1267 AllWhlDrvRcmndIndOn "ENM";
BA_ "SignalLongName" SG_ 1267 AllWhlDrvRcmndIndOn "All Wheel Drive Recommended Indication On";
BA_ "SignalType" SG_ 1267 CrwlModeDndRsnIndReq "ENM";
BA_ "SignalLongName" SG_ 1267 CrwlModeDndRsnIndReq "Crawl Mode Denied Reason Indication Request";
BA_ "SignalType" SG_ 1267 BrksOvrht "ENM";
BA_ "SignalLongName" SG_ 1267 BrksOvrht "Brakes Overheated";
BA_ "SignalType" SG_ 1267 BrkSysTwoFtdDrvDtdIndOn "ENM";
BA_ "SignalLongName" SG_ 1267 BrkSysTwoFtdDrvDtdIndOn "Brake System Two Footed Driving Detected Indication On";
BA_ "SignalType" SG_ 1267 BrkSysHillStrtAsstAvl "ENM";
BA_ "SignalLongName" SG_ 1267 BrkSysHillStrtAsstAvl "Brake System Hill Start Assist Available";
BA_ "SignalType" SG_ 1267 BrkPadWrnIO "ENM";
BA_ "SignalLongName" SG_ 1267 BrkPadWrnIO "Brake Pad Worn Indication On";
BA_ "SignalType" SG_ 1267 BrkPadLifeRrCnfrmRplcmtIndOn "ENM";
BA_ "SignalLongName" SG_ 1267 BrkPadLifeRrCnfrmRplcmtIndOn "Brake Pad Life Rear Confirm Replacement Indication On";
BA_ "SignalType" SG_ 1799 LnchCtlWhlSlSts "ENM";
BA_ "SignalLongName" SG_ 1799 LnchCtlWhlSlSts "Launch Control Wheel Slip Status";
BA_ "SignalType" SG_ 1799 LnchCtlEngRPMSts "ENM";
BA_ "SignalLongName" SG_ 1799 LnchCtlEngRPMSts "Launch Control Engine RPM Status";
BA_ "SignalLongName" SG_ 1799 LnchCtlBrkPresVal "Launch Control Brake Pressure Value";
BA_ "SignalType" SG_ 1799 DrvModeVisScreenSts "ENM";
BA_ "SignalLongName" SG_ 1799 DrvModeVisScreenSts "Driving Mode Visualization Screen Status";
BA_ "SignalType" SG_ 1799 EngSndPerfModeReq "ENM";
BA_ "SignalLongName" SG_ 1799 EngSndPerfModeReq "Engine Sound Performance Mode Request";
BA_ "SignalLongName" SG_ 1799 LnchCtlLineLckTmrVal "Launch Control Line Lock Timer Value";
BA_ "SignalType" SG_ 1799 PerfTracMgmtMode "ENM";
BA_ "SignalLongName" SG_ 1799 PerfTracMgmtMode "Performance Traction Management Mode";
BA_ "SignalType" SG_ 1799 HillDscntCtlSysSts "ENM";
BA_ "SignalLongName" SG_ 1799 HillDscntCtlSysSts "Hill Descent Control System Status";
BA_ "SignalType" SG_ 1799 SprtModeDrvlineVisDispVal "ENM";
BA_ "SignalLongName" SG_ 1799 SprtModeDrvlineVisDispVal "Sport Mode Driveline Visualization Display Value";
BA_ "SignalType" SG_ 1799 SprtModeBrkPedVisDispVal "ENM";
BA_ "SignalLongName" SG_ 1799 SprtModeBrkPedVisDispVal "Sport Mode Brake Pedal Visualization Display Value";
BA_ "SignalType" SG_ 1799 SprtModeActvAeroVisDispVal "ENM";
BA_ "SignalLongName" SG_ 1799 SprtModeActvAeroVisDispVal "Sport Mode Active Aerodynamics Visualization Display Value";
BA_ "SignalType" SG_ 1799 SprtModeRideHghtVisDispVal "ENM";
BA_ "SignalLongName" SG_ 1799 SprtModeRideHghtVisDispVal "Sport Mode Ride Height Visualization Display Value";
BA_ "SignalType" SG_ 1799 SprtModePwrtrnVisDispVal "ENM";
BA_ "SignalLongName" SG_ 1799 SprtModePwrtrnVisDispVal "Sport Mode Powertrain Visualization Display Value";
BA_ "SignalType" SG_ 1799 SprtModeESCVisDispVal "ENM";
BA_ "SignalLongName" SG_ 1799 SprtModeESCVisDispVal "Sport Mode ESC Visualization Display Value";
BA_ "SignalType" SG_ 1799 SprtModeSpnsnVisDispVal "ENM";
BA_ "SignalLongName" SG_ 1799 SprtModeSpnsnVisDispVal "Sport Mode Suspension Visualization Display Value";
BA_ "SignalType" SG_ 1799 SprtModeSndVisDispVal "ENM";
BA_ "SignalLongName" SG_ 1799 SprtModeSndVisDispVal "Sport Mode Sound Visualization Display Value";
BA_ "SignalType" SG_ 1799 ShfToPrkBfrExtIndOn "ENM";
BA_ "SignalLongName" SG_ 1799 ShfToPrkBfrExtIndOn "Shift To Park Before Exiting Indication On";
BA_ "SignalType" SG_ 1799 HillDscntCtlVirtSwAvl "ENM";
BA_ "SignalLongName" SG_ 1799 HillDscntCtlVirtSwAvl "Hill Descent Control Virtual Switch Available";
BA_ "SignalType" SG_ 1799 WthrSnwModeStrgVisDispVal "ENM";
BA_ "SignalLongName" SG_ 1799 WthrSnwModeStrgVisDispVal "Weather Snow Mode Steering Visualization Display Value";
BA_ "SignalType" SG_ 1799 SprtModeStrgVisDispVal "ENM";
BA_ "SignalLongName" SG_ 1799 SprtModeStrgVisDispVal "Sport Mode Steering Visualization Display Value";
BA_ "SignalType" SG_ 1266 TkModeBrkPedVisDispVal "ENM";
BA_ "SignalLongName" SG_ 1266 TkModeBrkPedVisDispVal "Track Mode Brake Pedal Visualization Display Value";
BA_ "SignalType" SG_ 1266 TkModeActvAeroVisDispVal "ENM";
BA_ "SignalLongName" SG_ 1266 TkModeActvAeroVisDispVal "Track Mode Active Aerodynamics Visualization Display Value";
BA_ "SignalType" SG_ 1266 TireTrdTempSts "ENM";
BA_ "SignalLongName" SG_ 1266 TireTrdTempSts "Tire Tread Temperature Status";
BA_ "SignalType" SG_ 1266 TkModePwrtrnVisDispVal "ENM";
BA_ "SignalLongName" SG_ 1266 TkModePwrtrnVisDispVal "Track Mode Powertrain Visualization Display Value";
BA_ "SignalType" SG_ 1266 TkModeESCVisDispVal "ENM";
BA_ "SignalLongName" SG_ 1266 TkModeESCVisDispVal "Track Mode ESC Visualization Display Value";
BA_ "SignalType" SG_ 1266 TkModeDrvlineVisDispVal "ENM";
BA_ "SignalLongName" SG_ 1266 TkModeDrvlineVisDispVal "Track Mode Driveline Visualization Display Value";
BA_ "SignalType" SG_ 1266 TkModeSndVisDispVal "ENM";
BA_ "SignalLongName" SG_ 1266 TkModeSndVisDispVal "Track Mode Sound Visualization Display Value";
BA_ "SignalType" SG_ 1266 TkModeRideHghtVisDispVal "ENM";
BA_ "SignalLongName" SG_ 1266 TkModeRideHghtVisDispVal "Track Mode Ride Height Visualization Display Value";
BA_ "SignalType" SG_ 1266 TourModeActvAeroVisDispVal "ENM";
BA_ "SignalLongName" SG_ 1266 TourModeActvAeroVisDispVal "Tour Mode Active Aerodynamics Visualization Display Value";
BA_ "SignalType" SG_ 1266 TkModeStrgVisDispVal "ENM";
BA_ "SignalLongName" SG_ 1266 TkModeStrgVisDispVal "Track Mode Steering Visualization Display Value";
BA_ "SignalType" SG_ 1266 TkModeSpnsnVisDispVal "ENM";
BA_ "SignalLongName" SG_ 1266 TkModeSpnsnVisDispVal "Track Mode Suspension Visualization Display Value";
BA_ "SignalType" SG_ 1266 TourModeESCVisDispVal "ENM";
BA_ "SignalLongName" SG_ 1266 TourModeESCVisDispVal "Tour Mode ESC Visualization Display Value";
BA_ "SignalType" SG_ 1266 TourModeDrvlineVisDispVal "ENM";
BA_ "SignalLongName" SG_ 1266 TourModeDrvlineVisDispVal "Tour Mode Driveline Visualization Display Value";
BA_ "SignalType" SG_ 1266 TourModeBrkPedVisDispVal "ENM";
BA_ "SignalLongName" SG_ 1266 TourModeBrkPedVisDispVal "Tour Mode Brake Pedal Visualization Display Value";
BA_ "SignalType" SG_ 1266 TourModeRideHghtVisDispVal "ENM";
BA_ "SignalLongName" SG_ 1266 TourModeRideHghtVisDispVal "Tour Mode Ride Height Visualization Display Value";
BA_ "SignalType" SG_ 1266 TourModePwrtrnVisDispVal "ENM";
BA_ "SignalLongName" SG_ 1266 TourModePwrtrnVisDispVal "Tour Mode Powertrain Visualization Display Value";
BA_ "SignalType" SG_ 1266 TourModeStrgVisDispVal "ENM";
BA_ "SignalLongName" SG_ 1266 TourModeStrgVisDispVal "Tour Mode Steering Visualization Display Value";
BA_ "SignalType" SG_ 1266 TourModeSpnsnVisDispVal "ENM";
BA_ "SignalLongName" SG_ 1266 TourModeSpnsnVisDispVal "Tour Mode Suspension Visualization Display Value";
BA_ "SignalType" SG_ 1266 TourModeSndVisDispVal "ENM";
BA_ "SignalLongName" SG_ 1266 TourModeSndVisDispVal "Tour Mode Sound Visualization Display Value";
BA_ "SignalType" SG_ 1266 TrlrStbAsstActIO "ENM";
BA_ "SignalLongName" SG_ 1266 TrlrStbAsstActIO "TrailerStabilityAssistActiveIndicationOn";
BA_ "SignalType" SG_ 1266 TrcCntrlOnIO "ENM";
BA_ "SignalLongName" SG_ 1266 TrcCntrlOnIO "Traction Control On Indication On";
BA_ "SignalType" SG_ 1266 TrcCntrlOffIO "ENM";
BA_ "SignalLongName" SG_ 1266 TrcCntrlOffIO "Traction Control Off Indication On";
BA_ "SignalType" SG_ 1266 TnDrvTrCtrlOffUnvIndOn "ENM";
BA_ "SignalLongName" SG_ 1266 TnDrvTrCtrlOffUnvIndOn "Teen Driver Traction Control Off Unavailable Indication On";
BA_ "SignalType" SG_ 1266 SrBkLwBkFlDrVisMsgRqOn "ENM";
BA_ "SignalLongName" SG_ 1266 SrBkLwBkFlDrVisMsgRqOn "Service Brakes Low Brake Fluid Driver Visual Message Request On";
BA_ "SignalType" SG_ 1266 TrcStbScrConfig "ENM";
BA_ "SignalLongName" SG_ 1266 TrcStbScrConfig "Traction and Stability Screen Configuration";
BA_ "SignalLongName" SG_ 721 FlInjRlCt "Fuel Injected Rolling Count";
BA_ "SignalLongName" SG_ 721 InstFlCnsmpRt "Instantaneous Fuel Consumption Rate";
BA_ "SignalLongName" SG_ 721 EngIntkArBstPr "Engine Intake Air Boost Pressure";
BA_ "SignalType" SG_ 721 EngIntkArBstPr_Inv "ENM";
BA_ "SignalLongName" SG_ 721 EngIntkArBstPr_Inv "Engine Intake Air Boost Pressure Invalid";
BA_ "SignalLongName" SG_ 721 EngOilRmnLf "Engine Oil Remaining Life";
BA_ "SignalLongName" SG_ 721 FuelFiltRmnLife "Fuel Filter Remaining Life";
BA_ "SignalType" SG_ 721 FlInjRlCtRstOcc "ENM";
BA_ "SignalLongName" SG_ 721 FlInjRlCtRstOcc "Fuel Injected Rolling Count Reset Occurred";
BA_ "SignalType" SG_ 721 EngRcmndDwnsftIndOn "ENM";
BA_ "SignalLongName" SG_ 721 EngRcmndDwnsftIndOn "Engine Recommended Downshift Indication On";
BA_ "SignalType" SG_ 721 EngFuelInjnSysFltIndOn "ENM";
BA_ "SignalLongName" SG_ 721 EngFuelInjnSysFltIndOn "Engine Fuel Injection System Fault Indication On";
BA_ "SignalType" SG_ 721 IdlRecmndToClEngIO "ENM";
BA_ "SignalLongName" SG_ 721 IdlRecmndToClEngIO "Idle Recommended To Cool Engine Indication On";
BA_ "SignalType" SG_ 721 FuelSysNEmsRltMlfActv "ENM";
BA_ "SignalLongName" SG_ 721 FuelSysNEmsRltMlfActv "Fuel System Non Emissions Related Malfunction Active";
BA_ "SignalType" SG_ 721 FuelFiltChgNowIndOn "ENM";
BA_ "SignalLongName" SG_ 721 FuelFiltChgNowIndOn "Fuel Filter Change Now Indication On";
BA_ "SignalLongName" SG_ 1800 ChrgCycBatPrplDistTrvld "Charge Cycle Battery Propulsion Distance Traveled";
BA_ "SignalLongName" SG_ 1800 ChrgCycBrkRegnRng "Charge Cycle Brake Regeneration Range";
BA_ "SignalLongName" SG_ 1800 ChrgCycDrvTm "Charge Cycle Drive Time";
BA_ "SignalLongName" SG_ 1800 TgtChrgLvlMinSetVal "Target Charge Level Minimum Setting Value";
BA_ "SignalType" SG_ 1800 ChrgCordThftAlrtCstSetAval "ENM";
BA_ "SignalLongName" SG_ 1800 ChrgCordThftAlrtCstSetAval "Charge Cord Theft Alert Customization Setting Available";
BA_ "SignalType" SG_ 1800 ChrgCordThftAlrtCstCurrSetVal "ENM";
BA_ "SignalLongName" SG_ 1800 ChrgCordThftAlrtCstCurrSetVal "Charge Cord Theft Alert Customization Current Setting Value";
BA_ "SignalLongName" SG_ 1265 ChrgCycEleclEngyCnsmdRngImp1 "Charge Cycle Electrical Energy Consumed Range Impact 1";
BA_ "SignalLongName" SG_ 1265 ChrgCycEleclEngyCnsmdRngImp2 "Charge Cycle Electrical Energy Consumed Range Impact 2";
BA_ "SignalLongName" SG_ 1265 ChrgCycEleclEngyCnsmdRngImp3 "Charge Cycle Electrical Energy Consumed Range Impact 3";
BA_ "SignalType" SG_ 1265 ChrgPwrLossAlrtCstSetAval "ENM";
BA_ "SignalLongName" SG_ 1265 ChrgPwrLossAlrtCstSetAval "Charge Power Loss Alert Customization Setting Available";
BA_ "SignalType" SG_ 1265 ChrgrSysAudblIndCstCurrSetVal "ENM";
BA_ "SignalLongName" SG_ 1265 ChrgrSysAudblIndCstCurrSetVal "Charger System Audible Indication Customization Current Setting Value";
BA_ "SignalType" SG_ 1265 ChrgPwrLossAlrtCstCurrSetVal "ENM";
BA_ "SignalLongName" SG_ 1265 ChrgPwrLossAlrtCstCurrSetVal "Charge Power Loss Alert Customization Current Setting Value";
BA_ "SignalType" SG_ 1265 ChrgPortDrIndReq "ENM";
BA_ "SignalLongName" SG_ 1265 ChrgPortDrIndReq "Charge Port Door Indication Request";
BA_ "SignalLongName" SG_ 1801 ChrgCycEleclEngyCnsmdRngImpTot "Charge Cycle Electrical Energy Consumed Range Impact Total";
BA_ "SignalLongName" SG_ 1801 ChrgCycEleclEngyCnsmdRngImp4 "Charge Cycle Electrical Energy Consumed Range Impact 4";
BA_ "SignalLongName" SG_ 1801 ChrgCycEleclEngyEcon "Charge Cycle Electrical Energy Economy";
BA_ "SignalLongName" SG_ 1801 PrtblChrgCordLimRdcdChrgCurrLvl "Portable Charge Cord Limit Reduced Charge Current Level";
BA_ "SignalType" SG_ 1801 InsfcntTmtoCmpltChrgIndOn "ENM";
BA_ "SignalLongName" SG_ 1801 InsfcntTmtoCmpltChrgIndOn "Insufficient Time to Complete Charge Indication On";
BA_ "SignalLongName" SG_ 1264 ChrgCycEleclEngyStat1 "Charge Cycle Electrical Energy State 1";
BA_ "SignalLongName" SG_ 1264 ChrgCycEleclEngyStat2 "Charge Cycle Electrical Energy State 2";
BA_ "SignalLongName" SG_ 1264 ChrgCycEleclEngyStat3 "Charge Cycle Electrical Energy State 3";
BA_ "SignalType" SG_ 1264 CntctrsOpnUndrTempIndOn "ENM";
BA_ "SignalLongName" SG_ 1264 CntctrsOpnUndrTempIndOn "Contactors Open Under Temperature Indication On";
BA_ "SignalType" SG_ 1264 ChrgrSysAudblIndCstSetAval "ENM";
BA_ "SignalLongName" SG_ 1264 ChrgrSysAudblIndCstSetAval "Charger System Audible Indication Customization Setting Available";
BA_ "SignalType" SG_ 1264 ChrgStsPeekInScrnActvIndOn "ENM";
BA_ "SignalLongName" SG_ 1264 ChrgStsPeekInScrnActvIndOn "Charge Status Peek In Screen Active Indication On";
BA_ "SignalLongName" SG_ 1802 ChrgCycEleclEngyStat4 "Charge Cycle Electrical Energy State 4";
BA_ "SignalLongName" SG_ 1802 ChrgDatCalcChksm "Charging Data Calculated Checksum";
BA_ "SignalLongName" SG_ 1802 PrtblChrgCordLimMaxChrgCurrLvl "Portable Charge Cord Limit Maximum Charge Current Level";
BA_ "SignalType" SG_ 1802 PrtblChrgCordLimCstSetAval "ENM";
BA_ "SignalLongName" SG_ 1802 PrtblChrgCordLimCstSetAval "Portable Charge Cord Limit Customization Setting Available";
BA_ "SignalType" SG_ 1802 OffBrdChrgStnFltDtd "ENM";
BA_ "SignalLongName" SG_ 1802 OffBrdChrgStnFltDtd "Off Board Charge Station Fault Detected";
BA_ "SignalType" SG_ 1802 NeutCstdwnCertModeActvIndOn "ENM";
BA_ "SignalLongName" SG_ 1802 NeutCstdwnCertModeActvIndOn "DEPRECATED VIP 24 - Neutral Coastdown Certification Mode Active Indication On";
BA_ "SignalType" SG_ 1802 LocBsdChrgCstSetAval "ENM";
BA_ "SignalLongName" SG_ 1802 LocBsdChrgCstSetAval "Location Based Charging Customization Setting Available";
BA_ "SignalType" SG_ 1802 LocBsdChrgCstCurrSetVal "ENM";
BA_ "SignalLongName" SG_ 1802 LocBsdChrgCstCurrSetVal "Location Based Charging Customization Current Setting Value";
BA_ "SignalLongName" SG_ 1263 CCEEC_EngyPct1 "Charge Cycle Electrical Energy Consumed : Energy Percent 1";
BA_ "SignalLongName" SG_ 1263 CCEEC_EngyPct2 "Charge Cycle Electrical Energy Consumed : Energy Percent 2";
BA_ "SignalLongName" SG_ 1263 CCEEC_EngyPct3 "Charge Cycle Electrical Energy Consumed : Energy Percent 3";
BA_ "SignalLongName" SG_ 1263 CCEEC_EngyPct4 "Charge Cycle Electrical Energy Consumed : Energy Percent 4";
BA_ "SignalLongName" SG_ 1263 DCEEC_EngyPct1 "Drive Cycle Electrical Energy Consumed : Energy Percent 1";
BA_ "SignalLongName" SG_ 1263 DCEEC_EngyPct2 "Drive Cycle Electrical Energy Consumed : Energy Percent 2";
BA_ "SignalLongName" SG_ 1263 DCEEC_EngyPct3 "Drive Cycle Electrical Energy Consumed : Energy Percent 3";
BA_ "SignalLongName" SG_ 1263 DCEEC_EngyPct4 "Drive Cycle Electrical Energy Consumed : Energy Percent 4";
BA_ "SignalLongName" SG_ 1803 RtdEleclEngyEcon "Rated Electrical Energy Economy";
BA_ "SignalType" SG_ 1803 LBCPSS_PstnUpdtLoc "ENM";
BA_ "SignalLongName" SG_ 1803 LBCPSS_PstnUpdtLoc "Location Based Charging Position Storage Status : Position Update Location";
BA_ "SignalType" SG_ 1803 LBCCDRR_PstnNumResp "ENM";
BA_ "SignalLongName" SG_ 1803 LBCCDRR_PstnNumResp "Location Based Charging Customer Data Reset Response : Position Number Response";
BA_ "SignalType" SG_ 1803 LBCCDRR_ClrStrdPstnResp "ENM";
BA_ "SignalLongName" SG_ 1803 LBCCDRR_ClrStrdPstnResp "Location Based Charging Customer Data Reset Response : Clear Stored Position Response";
BA_ "SignalType" SG_ 1803 ServHybChrgSysIndOn "ENM";
BA_ "SignalLongName" SG_ 1803 ServHybChrgSysIndOn "Service Hybrid Charging System Indication On";
BA_ "SignalType" SG_ 1803 LBCCF_Loc4PstnStrdIndOn "ENM";
BA_ "SignalLongName" SG_ 1803 LBCCF_Loc4PstnStrdIndOn "Location Based Charging Customer Feedback : Location 4 Position Stored Indication On";
BA_ "SignalType" SG_ 1803 LBCCF_Loc3PstnStrdIndOn "ENM";
BA_ "SignalLongName" SG_ 1803 LBCCF_Loc3PstnStrdIndOn "Location Based Charging Customer Feedback : Location 3 Position Stored Indication On";
BA_ "SignalType" SG_ 1803 LBCCF_Loc2PstnStrdIndOn "ENM";
BA_ "SignalLongName" SG_ 1803 LBCCF_Loc2PstnStrdIndOn "Location Based Charging Customer Feedback : Location 2 Position Stored Indication On";
BA_ "SignalType" SG_ 1803 LBCCF_Loc1PstnStrdIndOn "ENM";
BA_ "SignalLongName" SG_ 1803 LBCCF_Loc1PstnStrdIndOn "Location Based Charging Customer Feedback : Location 1 Position Stored Indication On";
BA_ "SignalType" SG_ 1803 LBCPSS_PstnUpdtSts "ENM";
BA_ "SignalLongName" SG_ 1803 LBCPSS_PstnUpdtSts "Location Based Charging Position Storage Status : Position Update Status";
BA_ "SignalLongName" SG_ 1262 TAI_DistTrvld "Trip A Information : Distance Traveled";
BA_ "SignalLongName" SG_ 1262 TAI_EleclEngy "Trip A Information : Electrical Energy";
BA_ "SignalLongName" SG_ 1262 TAI_EleclEngyEcon "Trip A Information : Electrical Energy Economy";
BA_ "SignalType" SG_ 1262 VehLocSts "ENM";
BA_ "SignalLongName" SG_ 1262 VehLocSts "Vehicle Location Status";
BA_ "SignalType" SG_ 1262 VehLocSts_Inv "ENM";
BA_ "SignalLongName" SG_ 1262 VehLocSts_Inv "Vehicle Location Status Invalid";
BA_ "SignalLongName" SG_ 1804 TODCSR_ChrgSchedHrOfDyResp "Time of Day Charging Setting Response : Charge Schedule Hour of Day Response";
BA_ "SignalType" SG_ 1804 TODCSR_ChrgSchedDyOfWkResp "ENM";
BA_ "SignalLongName" SG_ 1804 TODCSR_ChrgSchedDyOfWkResp "Time of Day Charging Setting Response : Charge Schedule Day of Week Response";
BA_ "SignalType" SG_ 1804 TODCSR_ChrgSchedCstSetVal "ENM";
BA_ "SignalLongName" SG_ 1804 TODCSR_ChrgSchedCstSetVal "Time of Day Charging Setting Response : Charge Schedule Customization Setting Value";
BA_ "SignalLongName" SG_ 1804 TODCSR_ChrgSchedMinOfHrResp "Time of Day Charging Setting Response : Charge Schedule Minute of Hour Response";
BA_ "SignalLongName" SG_ 1804 TODCSR_ERSPrdHrOfDyResp "Time of Day Charging Setting Response : Electric Rate Schedule Period Hour of Day Response";
BA_ "SignalType" SG_ 1804 TODCSR_ERSPrdDyResp "ENM";
BA_ "SignalLongName" SG_ 1804 TODCSR_ERSPrdDyResp "Time of Day Charging Setting Response : Electric Rate Schedule Period Day Response";
BA_ "SignalType" SG_ 1804 TODCSR_ERSCstSetVal "ENM";
BA_ "SignalLongName" SG_ 1804 TODCSR_ERSCstSetVal "Time of Day Charging Setting Response : Electric Rate Schedule Customization Setting Value";
BA_ "SignalLongName" SG_ 1804 TODCSR_ERSPrdMinOfHrResp "Time of Day Charging Setting Response : Electric Rate Schedule Period Minute of Hour Response";
BA_ "SignalType" SG_ 1804 TODCSR_ERSPrdLvlResp "ENM";
BA_ "SignalLongName" SG_ 1804 TODCSR_ERSPrdLvlResp "Time of Day Charging Setting Response : Electric Rate Schedule Period Level Response";
BA_ "SignalType" SG_ 1804 PrtblChrgCordLimCstSetResp "ENM";
BA_ "SignalLongName" SG_ 1804 PrtblChrgCordLimCstSetResp "Time of Day Charging Setting Response : Portable Charge Cord Limit Customization Setting Response";
BA_ "SignalType" SG_ 1804 TODCSR_ERSPrfResp "ENM";
BA_ "SignalLongName" SG_ 1804 TODCSR_ERSPrfResp "Time of Day Charging Setting Response : Electric Rate Schedule Preference Response";
BA_ "SignalType" SG_ 1804 TODCCbnPrcndtngSetResp "ENM";
BA_ "SignalLongName" SG_ 1804 TODCCbnPrcndtngSetResp "Time of Day Charging Setting Response : Time of Day Charging Cabin Preconditioning Setting Response";
BA_ "SignalType" SG_ 1804 TODCSR_LocNumResp "ENM";
BA_ "SignalLongName" SG_ 1804 TODCSR_LocNumResp "Time of Day Charging Setting Response : Location Number Response";
BA_ "SignalType" SG_ 1804 TODCSR_LocChrgPwrLvlResp "ENM";
BA_ "SignalLongName" SG_ 1804 TODCSR_LocChrgPwrLvlResp "Time of Day Charging Setting Response : Location Charging Power Level Response";
BA_ "SignalType" SG_ 1804 UtlChrgIntfrIndOn "ENM";
BA_ "SignalLongName" SG_ 1804 UtlChrgIntfrIndOn "Utility Charging Interference Indication On";
BA_ "SignalLongName" SG_ 1804 TODCSR_TgtChrgLvlResp "Time of Day Charging Setting Response : Target Charge Level Response";
BA_ "SignalLongName" SG_ 1261 TODCNP_DprtrHrOfDy "Time of Day Charging Next Planned : Departure Hour of Day";
BA_ "SignalType" SG_ 1261 TODCNP_DprtrDyOfWk "ENM";
BA_ "SignalLongName" SG_ 1261 TODCNP_DprtrDyOfWk "Time of Day Charging Next Planned : Departure Day of Week";
BA_ "SignalType" SG_ 1261 TODCNP_Chrg "ENM";
BA_ "SignalLongName" SG_ 1261 TODCNP_Chrg "Time of Day Charging Next Planned : Charge";
BA_ "SignalLongName" SG_ 1261 TODCNP_DprtrMinOfHr "Time of Day Charging Next Planned : Departure Minute of Hour";
BA_ "SignalLongName" SG_ 1261 TODCNP_TgtChrgLvl "Time of Day Charging Next Planned : Target Charge Level";
BA_ "SignalType" SG_ 1261 TODCNP_PCCLCstCurrSetVal "ENM";
BA_ "SignalLongName" SG_ 1261 TODCNP_PCCLCstCurrSetVal "Time of Day Charging Next Planned : Portable Charge Cord Limit Customization Current Setting Value";
BA_ "SignalLongName" SG_ 1261 RngGaindThisChrg "Range Gained This Charge";
BA_ "SignalLongName" SG_ 1261 RngPerHrGaindThisChrg "Range Per Hour Gained This Charge";
BA_ "SignalLongName" SG_ 1261 TgtChrgLvlStopChrgSetVal "Target Charge Level Stop Charging Setting Value";
BA_ "SignalType" SG_ 1261 TmOfDyChrgInvHMIEntIndReqd "ENM";
BA_ "SignalLongName" SG_ 1261 TmOfDyChrgInvHMIEntIndReqd "Time of Day Charging Invalid HMI Entry Indication Requested";
BA_ "SignalType" SG_ 1261 PrtblChrgCordLimSetExpIndOn "ENM";
BA_ "SignalLongName" SG_ 1261 PrtblChrgCordLimSetExpIndOn "Portable Charge Cord Limit Setting Expiration Indication On";
BA_ "SignalType" SG_ 1261 RngPerHrGaindThisChrg_DuD "ENM";
BA_ "SignalLongName" SG_ 1261 RngPerHrGaindThisChrg_DuD "Range Per Hour Gained This Charge Don't Use Data";
BA_ "SignalType" SG_ 1261 RngGaindThisChrg_DuD "ENM";
BA_ "SignalLongName" SG_ 1261 RngGaindThisChrg_DuD "Range Gained This Charge Don't Use Data";
BA_ "SignalType" SG_ 1261 TODCNextPlndCbnPrcndtngSetResp "ENM";
BA_ "SignalLongName" SG_ 1261 TODCNextPlndCbnPrcndtngSetResp "Time of Day Charging Next Planned : Time of Day Charging Next Planned Cabin Preconditioning Setting Response";
BA_ "SignalLongName" SG_ 1805 LifetmBatPrplDistTrvld "Lifetime Battery Propulsion Distance Traveled";
BA_ "SignalLongName" SG_ 1805 DrvCycBrkRegnRng "Drive Cycle Brake Regeneration Range";
BA_ "SignalLongName" SG_ 1805 DrvCycDrvTm "Drive Cycle Drive Time";
BA_ "SignalLongName" SG_ 1260 LifetmEleclEngyUsd "Lifetime Electrical Energy Used";
BA_ "SignalLongName" SG_ 1260 LifetmWallEngyUsd "Lifetime Wall Energy Used";
BA_ "SignalLongName" SG_ 1260 HiVltgBatBulkSOC "High Voltage Battery Bulk State of Charge";
BA_ "SignalType" SG_ 1260 EngyEconMeasUnt "ENM";
BA_ "SignalLongName" SG_ 1260 EngyEconMeasUnt "Energy Economy Measurement Unit";
BA_ "SignalLongName" SG_ 1806 DrvCycEleclEngyStat4 "Drive Cycle Electrical Energy State 4";
BA_ "SignalLongName" SG_ 1806 ECHG_CurrEcon "Energy Consumption History Graph : Current Economy";
BA_ "SignalType" SG_ 1806 ECHG_CurrEconRdy "ENM";
BA_ "SignalLongName" SG_ 1806 ECHG_CurrEconRdy "Energy Consumption History Graph : Current Economy Ready";
BA_ "SignalLongName" SG_ 1806 DrvCycEleclEngyUsd "Drive Cycle Electrical Energy Used";
BA_ "SignalType" SG_ 1806 HiVltgChrgAbrtRsn "ENM";
BA_ "SignalLongName" SG_ 1806 HiVltgChrgAbrtRsn "High Voltage Charge Abort Reason";
BA_ "SignalType" SG_ 1806 HiVltgChrgSysSplyFltIndOn "ENM";
BA_ "SignalLongName" SG_ 1806 HiVltgChrgSysSplyFltIndOn "High Voltage Charging System Supply Fault Indication On";
BA_ "SignalType" SG_ 1806 HiVltgBatStopChrgBtnVsbl "ENM";
BA_ "SignalLongName" SG_ 1806 HiVltgBatStopChrgBtnVsbl "High Voltage Battery Stop Charging Button Visible";
BA_ "SignalType" SG_ 1806 HiVltgBatChrgCordCnctdIndOn "ENM";
BA_ "SignalLongName" SG_ 1806 HiVltgBatChrgCordCnctdIndOn "High Voltage Battery Charge Cord Connected Indication On";
BA_ "SignalType" SG_ 1806 HiVltgBatBulkChrgCmplt "ENM";
BA_ "SignalLongName" SG_ 1806 HiVltgBatBulkChrgCmplt "High Voltage Battery Bulk Charge Complete";
BA_ "SignalType" SG_ 1806 ElecPrplMtrOvrSpdIndOn "ENM";
BA_ "SignalLongName" SG_ 1806 ElecPrplMtrOvrSpdIndOn "Electric Propulsion Motor Over Speed Indication On";
BA_ "SignalType" SG_ 1806 HiVltgChrgInhbRsn "ENM";
BA_ "SignalLongName" SG_ 1806 HiVltgChrgInhbRsn "High Voltage Charge Inhibit Reason";
BA_ "SignalType" SG_ 1806 DrvCycEleclEngyUsd_DuD "ENM";
BA_ "SignalLongName" SG_ 1806 DrvCycEleclEngyUsd_DuD "Drive Cycle Electrical Energy Used Don't Use Data";
BA_ "SignalLongName" SG_ 1259 HiVltgBatPrplRng "High Voltage Battery Propulsion Range";
BA_ "SignalLongName" SG_ 1259 HiVltgBatPrplRngPrjtd "High Voltage Battery Propulsion Range Projected";
BA_ "SignalType" SG_ 1259 HiVltgBatPrplRng_Inv "ENM";
BA_ "SignalLongName" SG_ 1259 HiVltgBatPrplRng_Inv "High Voltage Battery Propulsion Range Invalid";
BA_ "SignalType" SG_ 1259 HiVltgBatPrplRng_DuD "ENM";
BA_ "SignalLongName" SG_ 1259 HiVltgBatPrplRng_DuD "High Voltage Battery Propulsion Range Don't Use Data";
BA_ "SignalLongName" SG_ 1259 HiVltgBatRmnUsblEngy "High Voltage Battery Remaining Usable Energy";
BA_ "SignalType" SG_ 1259 HiVltgBatRmnUsblEngy_Inv "ENM";
BA_ "SignalLongName" SG_ 1259 HiVltgBatRmnUsblEngy_Inv "High Voltage Battery Remaining Usable Energy Invalid";
BA_ "SignalType" SG_ 1259 HiVltgBatRmnUsblEngy_DuD "ENM";
BA_ "SignalLongName" SG_ 1259 HiVltgBatRmnUsblEngy_DuD "High Voltage Battery Remaining Usable Energy Don't Use Data";
BA_ "SignalLongName" SG_ 1807 DrvCycEleclEngyCnsmdRngImp1 "Drive Cycle Electrical Energy Consumed Range Impact 1";
BA_ "SignalLongName" SG_ 1807 DrvCycEleclEngyCnsmdRngImp2 "Drive Cycle Electrical Energy Consumed Range Impact 2";
BA_ "SignalLongName" SG_ 1807 DrvCycEleclEngyCnsmdRngImp3 "Drive Cycle Electrical Energy Consumed Range Impact 3";
BA_ "SignalLongName" SG_ 1807 DrvCycEleclEngyCnsmdRngImp4 "Drive Cycle Electrical Energy Consumed Range Impact 4";
BA_ "SignalType" SG_ 1807 DispHiVltgBatChrgCmpltInfo "ENM";
BA_ "SignalLongName" SG_ 1807 DispHiVltgBatChrgCmpltInfo "Display High Voltage Battery Charging Complete Information";
BA_ "SignalLongName" SG_ 1258 DrvCycEleclEngyCnsmdRngImpTot "Drive Cycle Electrical Energy Consumed Range Impact Total";
BA_ "SignalLongName" SG_ 1258 DrvCycEleclEngyStat1 "Drive Cycle Electrical Energy State 1";
BA_ "SignalLongName" SG_ 1258 DrvCycEleclEngyEcon "Drive Cycle Electrical Energy Economy";
BA_ "SignalLongName" SG_ 1258 DrvCycBatPrplDistTrvld "Drive Cycle Battery Propulsion Distance Traveled";
BA_ "SignalLongName" SG_ 1808 DrvCycEleclEngyStat2 "Drive Cycle Electrical Energy State 2";
BA_ "SignalLongName" SG_ 1808 DrvCycEleclEngyStat3 "Drive Cycle Electrical Energy State 3";
BA_ "SignalLongName" SG_ 1808 HiVltgBatTotUsblEngy "High Voltage Battery Total Usable Energy";
BA_ "SignalLongName" SG_ 1808 ElecRateSchedSsnStrtDyResp "Electric Rate Season Settings Response : Electric Rate Schedule Season Start Day Response";
BA_ "SignalType" SG_ 1808 ElecRateSchedSsnResp "ENM";
BA_ "SignalLongName" SG_ 1808 ElecRateSchedSsnResp "Electric Rate Season Settings Response : Electric Rate Schedule Season Response";
BA_ "SignalType" SG_ 1808 HiVltgBatTotUsblEngy_Inv "ENM";
BA_ "SignalLongName" SG_ 1808 HiVltgBatTotUsblEngy_Inv "High Voltage Battery Total Usable Energy Invalid";
BA_ "SignalType" SG_ 1808 HiVltgBatTotUsblEngy_DuD "ENM";
BA_ "SignalLongName" SG_ 1808 HiVltgBatTotUsblEngy_DuD "High Voltage Battery Total Usable Energy Don't Use Data";
BA_ "SignalType" SG_ 1808 ElecRateSchedSsnStrtMthResp "ENM";
BA_ "SignalLongName" SG_ 1808 ElecRateSchedSsnStrtMthResp "Electric Rate Season Settings Response : Electric Rate Schedule Season Start Month Response";
BA_ "SignalLongName" SG_ 1257 TBI_DistTrvld "Trip B Information : Distance Traveled";
BA_ "SignalLongName" SG_ 1257 TBI_EleclEngy "Trip B Information : Electrical Energy";
BA_ "SignalLongName" SG_ 1257 TBI_EleclEngyEcon "Trip B Information : Electrical Energy Economy";
BA_ "SignalLongName" SG_ 941 ACCTOSHiThrtLicVehTmToClsn1 "Adaptive Cruise Control Target Object Selection High Threat Licensable Vehicle Time to Collision 1";
BA_ "SignalLongName" SG_ 941 ACCTOSHiThrtLicVehTmToClsn10 "Adaptive Cruise Control Target Object Selection High Threat Licensable Vehicle Time to Collision 10";
BA_ "SignalLongName" SG_ 941 ACCTOSHiThrtLicVehTmToClsn2 "Adaptive Cruise Control Target Object Selection High Threat Licensable Vehicle Time to Collision 2";
BA_ "SignalLongName" SG_ 941 ACCTOSHiThrtLicVehTmToClsn3 "Adaptive Cruise Control Target Object Selection High Threat Licensable Vehicle Time to Collision 3";
BA_ "SignalLongName" SG_ 942 ACCTOSHiThrtLicVehTmToClsn4 "Adaptive Cruise Control Target Object Selection High Threat Licensable Vehicle Time to Collision 4";
BA_ "SignalLongName" SG_ 942 ACCTOSHiThrtLicVehTmToClsn5 "Adaptive Cruise Control Target Object Selection High Threat Licensable Vehicle Time to Collision 5";
BA_ "SignalLongName" SG_ 942 ACCTOSHiThrtLicVehTmToClsn6 "Adaptive Cruise Control Target Object Selection High Threat Licensable Vehicle Time to Collision 6";
BA_ "SignalLongName" SG_ 942 ACCTOSHiThrtLicVehTmToClsn7 "Adaptive Cruise Control Target Object Selection High Threat Licensable Vehicle Time to Collision 7";
BA_ "SignalLongName" SG_ 943 ACCTOSHiThrtLicVehTmToClsn8 "Adaptive Cruise Control Target Object Selection High Threat Licensable Vehicle Time to Collision 8";
BA_ "SignalLongName" SG_ 943 ACCTOSHiThrtLicVehTmToClsn9 "Adaptive Cruise Control Target Object Selection High Threat Licensable Vehicle Time to Collision 9";
BA_ "SignalLongName" SG_ 943 LnFllwgTOSHiThrtLicVehLngDist1 "Lane Following Target Object Selection High Threat Licensable Vehicle Longitudinal Distance 1";
BA_ "SignalLongName" SG_ 943 LnFllwgTOSHiThrtLicVehLngDist2 "Lane Following Target Object Selection High Threat Licensable Vehicle Longitudinal Distance 2";
BA_ "SignalLongName" SG_ 944 LnFllwgTOSHiThrtLicVehLngDist3 "Lane Following Target Object Selection High Threat Licensable Vehicle Longitudinal Distance 3";
BA_ "SignalLongName" SG_ 944 LnFllwgTOSHiThrtLicVehLngDist4 "Lane Following Target Object Selection High Threat Licensable Vehicle Longitudinal Distance 4";
BA_ "SignalLongName" SG_ 944 LnFllwgTOSHiThrtLicVehLngDist5 "Lane Following Target Object Selection High Threat Licensable Vehicle Longitudinal Distance 5";
BA_ "SignalLongName" SG_ 944 LnFllwgTOSHiThrtLicVehLngDist6 "Lane Following Target Object Selection High Threat Licensable Vehicle Longitudinal Distance 6";
BA_ "SignalType" SG_ 944 StrgWhlTchSnsHndsOnStat "ENM";
BA_ "SignalLongName" SG_ 944 StrgWhlTchSnsHndsOnStat "Steering Wheel Touch Sense Hands On State";
VAL_ 1416 TrffcLgtAsstWrnChmEvntStat 0 "NO_ACTION" 1 "ACTIVE" 2 "CANCEL_CHIME" 3 "RESERVED_1" ;
VAL_ 1416 TrffcLgtAsstCstCurrSetVal 0 "SETTING_UNKNOWN" 1 "OFF" 2 "ALERT" 3 "RESERVED_3" 4 "RESERVED_4" 5 "RESERVED_5" 6 "RESERVED_6" 7 "RESERVED_7" ;
VAL_ 1416 GlrFrHgBmRspTypCstCurSetVal 0 "SETTING_UNKNOWN" 1 "AUTOMATIC_HIGH_BEAM" 2 "GLARE_FREE_HIGH_BEAM" 3 "RESERVED_3" 4 "\?? RESERVED_4" 5 "RESERVED_5" 6 "RESERVED_6" 7 "RESERVED_7" ;
VAL_ 1416 GlrFrHgBmRspTypCstAvlFlg7 0 "FALSE" 1 "TRUE" ;
VAL_ 1416 GlrFrHgBmRspTypCstAvlFlg6 0 "FALSE" 1 "TRUE" ;
VAL_ 1416 GlrFrHgBmRspTypCstAvlFlg5 0 "FALSE" 1 "TRUE" ;
VAL_ 1416 GlrFrHgBmRspTypCstAvlFlg4 0 "FALSE" 1 "TRUE" ;
VAL_ 1416 GlrFrHgBmRspTypCstAvlFlg3 0 "FALSE" 1 "TRUE" ;
VAL_ 1416 GlrFrHgBmRspTypCstAvlFlg2 0 "FALSE" 1 "TRUE" ;
VAL_ 1416 GlrFrHgBmRspTypCstAvlFlg1 0 "FALSE" 1 "TRUE" ;
VAL_ 1416 AutoHgBmCtrlIO 0 "FALSE" 1 "TRUE" ;
VAL_ 1416 TrffcLgtAsstCstAvlFlg7 0 "FALSE" 1 "TRUE" ;
VAL_ 1416 TrffcLgtAsstCstAvlFlg6 0 "FALSE" 1 "TRUE" ;
VAL_ 1416 TrffcLgtAsstCstAvlFlg5 0 "FALSE" 1 "TRUE" ;
VAL_ 1416 TrffcLgtAsstCstAvlFlg4 0 "FALSE" 1 "TRUE" ;
VAL_ 1416 TrffcLgtAsstCstAvlFlg3 0 "FALSE" 1 "TRUE" ;
VAL_ 1416 TrffcLgtAsstCstAvlFlg2 0 "FALSE" 1 "TRUE" ;
VAL_ 1416 TrffcLgtAsstCstAvlFlg1 0 "FALSE" 1 "TRUE" ;
VAL_ 1416 GlrFrHgBmRspTypCstStAvl 0 "FALSE" 1 "TRUE" ;
VAL_ 1416 TrffcLgtAsstCstSetAval 0 "FALSE" 1 "TRUE" ;
VAL_ 1811 TSMEurDispSgn2Mn 0 "UnKnown" 1 "No Sign Detected" 2 "End of Speed Limit" 3 "End of All Restrictions" 4 "Begin of Motorway" 5 "End of Motorway" 6 "Begin of Expressway" 7 "End of Expressway" 8 "Begin of Play Street Zone" 9 "End of Play Street Zone" 10 "Begin of Passing Restriction" 11 "End of Passing Restriction" 12 "No Entry" 13 "Begin of City Limits" 14 "End of City Limits" 15 "Speed Limit 5" 16 "Speed Limit 10" 17 "Speed Limit 15" 18 "Speed Limit 20" 19 "Speed Limit 25" 20 "Speed Limit 30" 21 "Speed Limit 35" 22 "Speed Limit 40" 23 "Speed Limit 45" 24 "Speed Limit 50" 25 "Speed Limit 55" 26 "Speed Limit 60" 27 "Speed Limit 65" 28 "Speed Limit 70" 29 "Speed Limit 75" 30 "Speed Limit 80" 31 "Speed Limit 85" 32 "Speed Limit 90" 33 "Speed Limit 95" 34 "Speed Limit 100" 35 "Speed Limit 105" 36 "Speed Limit 110" 37 "Speed Limit 115" 38 "Speed Limit 120" 39 "Speed Limit 125" 40 "Speed Limit 130" 41 "Speed Limit 135" 42 "Speed Limit 140" 43 "Speed Limit 145" 44 "Speed Limit 150" 45 "Speed Limit 155" 46 "Speed Limit 160" 47 "Speed Limit 165" 48 "Speed Limit 170" 49 "Speed Limit 175" 50 "Speed Limit 180" 51 "Speed Limit 185" 52 "Speed Limit 190" 53 "Speed Limit 195" 54 "Speed Limit 200" ;
VAL_ 1811 TSMEurDispSgn1Mn 0 "UnKnown" 1 "No Sign Detected" 2 "End of Speed Limit" 3 "End of All Restrictions" 4 "Begin of Motorway" 5 "End of Motorway" 6 "Begin of Expressway" 7 "End of Expressway" 8 "Begin of Play Street Zone" 9 "End of Play Street Zone" 10 "Begin of Passing Restriction" 11 "End of Passing Restriction" 12 "No Entry" 13 "Begin of City Limits" 14 "End of City Limits" 15 "Speed Limit 5" 16 "Speed Limit 10" 17 "Speed Limit 15" 18 "Speed Limit 20" 19 "Speed Limit 25" 20 "Speed Limit 30" 21 "Speed Limit 35" 22 "Speed Limit 40" 23 "Speed Limit 45" 24 "Speed Limit 50" 25 "Speed Limit 55" 26 "Speed Limit 60" 27 "Speed Limit 65" 28 "Speed Limit 70" 29 "Speed Limit 75" 30 "Speed Limit 80" 31 "Speed Limit 85" 32 "Speed Limit 90" 33 "Speed Limit 95" 34 "Speed Limit 100" 35 "Speed Limit 105" 36 "Speed Limit 110" 37 "Speed Limit 115" 38 "Speed Limit 120" 39 "Speed Limit 125" 40 "Speed Limit 130" 41 "Speed Limit 135" 42 "Speed Limit 140" 43 "Speed Limit 145" 44 "Speed Limit 150" 45 "Speed Limit 155" 46 "Speed Limit 160" 47 "Speed Limit 165" 48 "Speed Limit 170" 49 "Speed Limit 175" 50 "Speed Limit 180" 51 "Speed Limit 185" 52 "Speed Limit 190" 53 "Speed Limit 195" 54 "Speed Limit 200" ;
VAL_ 1811 TSMUSAndCADispSgn1Mn 0 "UnKnown" 1 "No Sign Detected" 2 "Begin of Passing Restriction US" 3 "End of Passing Restriction US" 4 "Begin of Passing Restriction Canada" 5 "End of Passing Restriction Canada" 6 "Speed Limit 5" 7 "Speed Limit 10" 8 "Speed Limit 15" 9 "Speed Limit 20" 10 "Speed Limit 25" 11 "Speed Limit 30" 12 "Speed Limit 35" 13 "Speed Limit 40" 14 "Speed Limit 45" 15 "Speed Limit 50" 16 "Speed Limit 55" 17 "Speed Limit 60" 18 "Speed Limit 65" 19 "Speed Limit 70" 20 "Speed Limit 75" 21 "Speed Limit 80" 22 "Speed Limit 85" 23 "Speed Limit 90" 24 "Speed Limit 95" 25 "Speed Limit 100" 26 "Speed Limit 105" 27 "Speed Limit 110" 28 "Speed Limit 115" 29 "Speed Limit 120" 30 "Speed Limit 125" 31 "Speed Limit 130" 32 "Speed Limit 135" 33 "Speed Limit 140" 34 "Speed Limit 145" 35 "Speed Limit 150" 36 "Speed Limit 155" 37 "Speed Limit 160" 38 "Speed Limit 165" 39 "Speed Limit 170" 40 "Speed Limit 175" 41 "Speed Limit 180" 42 "Speed Limit 185" 43 "Speed Limit 190" 44 "Speed Limit 195" 45 "Speed Limit 200" ;
VAL_ 1811 TSMUSAndCADispSgn2Mn 0 "UnKnown" 1 "No Sign Detected" 2 "Begin of Passing Restriction US" 3 "End of Passing Restriction US" 4 "Begin of Passing Restriction Canada" 5 "End of Passing Restriction Canada" 6 "Speed Limit 5" 7 "Speed Limit 10" 8 "Speed Limit 15" 9 "Speed Limit 20" 10 "Speed Limit 25" 11 "Speed Limit 30" 12 "Speed Limit 35" 13 "Speed Limit 40" 14 "Speed Limit 45" 15 "Speed Limit 50" 16 "Speed Limit 55" 17 "Speed Limit 60" 18 "Speed Limit 65" 19 "Speed Limit 70" 20 "Speed Limit 75" 21 "Speed Limit 80" 22 "Speed Limit 85" 23 "Speed Limit 90" 24 "Speed Limit 95" 25 "Speed Limit 100" 26 "Speed Limit 105" 27 "Speed Limit 110" 28 "Speed Limit 115" 29 "Speed Limit 120" 30 "Speed Limit 125" 31 "Speed Limit 130" 32 "Speed Limit 135" 33 "Speed Limit 140" 34 "Speed Limit 145" 35 "Speed Limit 150" 36 "Speed Limit 155" 37 "Speed Limit 160" 38 "Speed Limit 165" 39 "Speed Limit 170" 40 "Speed Limit 175" 41 "Speed Limit 180" 42 "Speed Limit 185" 43 "Speed Limit 190" 44 "Speed Limit 195" 45 "Speed Limit 200" ;
VAL_ 1811 TSMEurDispSgn2AddOn 0 "UnKnown" 1 "None" 2 "Supp Sign Generic" 3 "Rain" 4 "Snow" 5 "Snow Rain" 6 "Rain Cloud" 7 "Fog" 8 "Time" 9 "Wet Conditions" 10 "Trailer" 11 "Tractor Passable" 12 "Arrow Left" 13 "Arrow Right" 14 "Distance Arrow" 15 "School" ;
VAL_ 1811 TSMEurDispSgn1AddOn 0 "UnKnown" 1 "None" 2 "Supp Sign Generic" 3 "Rain" 4 "Snow" 5 "Snow Rain" 6 "Rain Cloud" 7 "Fog" 8 "Time" 9 "Wet Conditions" 10 "Trailer" 11 "Tractor Passable" 12 "Arrow Left" 13 "Arrow Right" 14 "Distance Arrow" 15 "School" ;
VAL_ 1811 FrwdVsFlDtcnIndOn 0 "FALSE" 1 "TRUE" ;
VAL_ 1811 FrwdVsAdvWthrIndOn 0 "FALSE" 1 "TRUE" ;
VAL_ 1811 TSMUSAndCADispSgn2AddOn 0 "None" 1 "Supp Sign Generic" 2 "School" 3 "School When Flashing" 4 "End of Speed Limit" 5 "Where Workers Present" ;
VAL_ 1811 TSMUSAndCADispSgn1AddOn 0 "None" 1 "Supp Sign Generic" 2 "School" 3 "School When Flashing" 4 "End of Speed Limit" 5 "Where Workers Present" ;
VAL_ 1811 TrffcLgtAsstHUDWrnIndOn 0 "FALSE" 1 "TRUE" ;
VAL_ 1811 TrffcLgtAsstClstrWrnIndOn 0 "FALSE" 1 "TRUE" ;
VAL_ 1811 TSMSgnNtfnIndOn 0 "FALSE" 1 "TRUE" ;
VAL_ 1811 TSMPDAMnSgnFlshgReq 0 "FALSE" 1 "TRUE" ;
VAL_ 1811 TSMNoEntryIndOn 0 "FALSE" 1 "TRUE" ;
VAL_ 1811 TSMIcePsblIndOn 0 "FALSE" 1 "TRUE" ;
VAL_ 1811 TSMAddTrfSgnAvIndOn 0 "FALSE" 1 "TRUE" ;
VAL_ 1811 FrwdVsFllBlckIndOn 0 "FALSE" 1 "TRUE" ;
VAL_ 1811 TrffcLgtAsstRLADWrnIndOn 0 "FALSE" 1 "TRUE" ;
VAL_ 1510 SBZALCAVisIndStatLt 0 "FLASHING" 1 "SOLID" 2 "OFF" ;
VAL_ 1511 SBZALCAVisIndStatRt 0 "FLASHING" 1 "SOLID" 2 "OFF" ;
VAL_ 1429 HtchVwAutoElecPrkBrkAppReqd 0 "FALSE" 1 "TRUE" ;
VAL_ 1512 AutoHgBmActReq 0 "FALSE" 1 "TRUE" ;
VAL_ 1417 RrCrsTrfcAlrtLftIndCtrl 0 "ON" 1 "OFF" 2 "FLASH" ;
VAL_ 1417 RrCrsTrfcAlrtCstCrStVal 0 "SETTING_UNKNOWN" 1 "OFF" 2 "ALERT" 3 "ALERT and BRAKE" 4 "RESERVED_4" 5 "RESERVED_5" 6 "RESERVED_6" 7 "RESERVED_7" ;
VAL_ 1417 LnChgAlrtCstCrStVal 0 "SETTING_UNKNOWN" 1 "OFF" 2 "ON" 3 "RESERVED_3" 4 "RESERVED_4" 5 "RESERVED_5" 6 "RESERVED_6" 7 "RESERVED_7" ;
VAL_ 1418 SBZAlrtCstCrStVal 0 "SETTING_UNKNOWN" 1 "OFF" 2 "ON" 3 "RESERVED_3" 4 "RESERVED_4" 5 "RESERVED_5" 6 "RESERVED_6" 7 "RESERVED_7" ;
VAL_ 1418 ByclDtnCstCurrSetVal 0 "Setting Unknown" 1 "Off" 2 "Alert" ;
VAL_ 1418 ByclDtnArbdIndStat 0 "No Indication" 1 "Off" 2 "Right Level 1" 3 "Left Level 1" 4 "Right Level 2" 5 "Left Level 2" 6 "Left and Right Level 1" 7 "Left and Right Level 2" ;
VAL_ 1418 ByclDtnCstAvlFlg1 0 "FALSE" 1 "TRUE" ;
VAL_ 1418 RrCrsTrfcAlrtLtSdChmEvntStat 0 "NO_ACTION" 1 "ACTIVE" 2 "CANCEL_CHIME" ;
VAL_ 1418 ByclDtnArbdLvl2ChmEvntStat 0 "No Action" 1 "Active" 2 "Cancel Chime" ;
VAL_ 1418 ByclDtnArbdLvl1ChmEvntStat 0 "No Action" 1 "Active" 2 "Cancel Chime" ;
VAL_ 1418 LnChgAlrtCstAvlFlg1 0 "FALSE" 1 "TRUE" ;
VAL_ 1418 ByclDtnCstSetAval 0 "FALSE" 1 "TRUE" ;
VAL_ 1418 ByclDtnCstAvlFlg7 0 "FALSE" 1 "TRUE" ;
VAL_ 1418 ByclDtnCstAvlFlg6 0 "FALSE" 1 "TRUE" ;
VAL_ 1418 ByclDtnCstAvlFlg5 0 "FALSE" 1 "TRUE" ;
VAL_ 1418 ByclDtnCstAvlFlg4 0 "FALSE" 1 "TRUE" ;
VAL_ 1418 ByclDtnCstAvlFlg3 0 "FALSE" 1 "TRUE" ;
VAL_ 1418 ByclDtnCstAvlFlg2 0 "FALSE" 1 "TRUE" ;
VAL_ 1418 LnChgAlrtSysOffIndOn 0 "FALSE" 1 "TRUE" ;
VAL_ 1418 LnChgAlrtCstStAvl 0 "FALSE" 1 "TRUE" ;
VAL_ 1418 LnChgAlrtCstAvlFlg7 0 "FALSE" 1 "TRUE" ;
VAL_ 1418 LnChgAlrtCstAvlFlg6 0 "FALSE" 1 "TRUE" ;
VAL_ 1418 LnChgAlrtCstAvlFlg5 0 "FALSE" 1 "TRUE" ;
VAL_ 1418 LnChgAlrtCstAvlFlg4 0 "FALSE" 1 "TRUE" ;
VAL_ 1418 LnChgAlrtCstAvlFlg3 0 "FALSE" 1 "TRUE" ;
VAL_ 1418 LnChgAlrtCstAvlFlg2 0 "FALSE" 1 "TRUE" ;
VAL_ 1418 RrCrsTrfcAlrtCstStAvl 0 "FALSE" 1 "TRUE" ;
VAL_ 1418 RrCrsTrfcAlrtCstAvlFlg7 0 "FALSE" 1 "TRUE" ;
VAL_ 1418 RrCrsTrfcAlrtCstAvlFlg6 0 "FALSE" 1 "TRUE" ;
VAL_ 1418 RrCrsTrfcAlrtCstAvlFlg5 0 "FALSE" 1 "TRUE" ;
VAL_ 1418 RrCrsTrfcAlrtCstAvlFlg4 0 "FALSE" 1 "TRUE" ;
VAL_ 1418 RrCrsTrfcAlrtCstAvlFlg3 0 "FALSE" 1 "TRUE" ;
VAL_ 1418 RrCrsTrfcAlrtCstAvlFlg2 0 "FALSE" 1 "TRUE" ;
VAL_ 1418 RrCrsTrfcAlrtCstAvlFlg1 0 "FALSE" 1 "TRUE" ;
VAL_ 1418 RrCrsTrfcBrkgAutoBrkgRelIndOn 0 "FALSE" 1 "TRUE" ;
VAL_ 1418 RrCrsTrfcAutoBrkgOffIndOn 0 "FALSE" 1 "TRUE" ;
VAL_ 1418 RrCrsTrfcAlrtOffIndOn 0 "FALSE" 1 "TRUE" ;
VAL_ 1419 RrCrsTrfcAlrtRtSdChmEvntStat 0 "NO_ACTION" 1 "ACTIVE" 2 "CANCEL_CHIME" ;
VAL_ 1419 RrCrsTrfcAlrtRgIndCtrl 0 "ON" 1 "OFF" 2 "FLASH" ;
VAL_ 1025 VwgSysUndrbdyCamWshReq 0 "Unknown" 1 "Active" 2 "Inactive" ;
VAL_ 1025 TrlrVidVwCrgLmpReq 0 "No_Action" 1 "On" 2 "Off" ;
VAL_ 1025 TrlrVidVwBoxRailLmpReq 0 "No_Action" 1 "On" 2 "Off" ;
VAL_ 1025 SrrndVwPudlLmpReqd 0 "FALSE" 1 "TRUE" ;
VAL_ 1479 HndsOnLnCntrAsstIndReq 0 "Off" 1 "White" 2 "Green" 3 "Green Flashing" 4 "Amber" 5 "Amber Flashing" 6 "Red" 7 "Red Flashing" ;
VAL_ 1479 HndsOnLnCntrAsstChmEvntStat 0 "No Action" 1 "Active" 2 "Cancel Chime" ;
VAL_ 1479 LnFllwgFtrStat 0 "Off" 1 "Unavailable" 2 "Disabled" 3 "Enabled" 4 "Active" 5 "Cautionary" 6 "Override" 7 "Degraded" 8 "No Return" 9 "Ended" 10 "Non-Responsive Driver" ;
VAL_ 1479 GnrcLnMrkngIndRt 0 "Off" 1 "White" 2 "Green" 3 "Green Flashing" 4 "Amber" 5 "Amber Flashing" 6 "Red" 7 "Red Flashing" ;
VAL_ 1479 GnrcLnMrkngIndLt 0 "Off" 1 "White" 2 "Green" 3 "Green Flashing" 4 "Amber" 5 "Amber Flashing" 6 "Red" 7 "Red Flashing" ;
VAL_ 1479 ADASSetSpdIndReq 0 "Indication Off" 1 "White Indicator" 2 "Green Indicator" 3 "Yellow Indicator" 4 "Red Indicator" 5 "Blue Indicator" ;
VAL_ 1479 SuprRmtPrkActvnPndgIndOn 0 "FALSE" 1 "TRUE" ;
VAL_ 1883 JckKnfDtnCstAvlFlg1 0 "FALSE" 1 "TRUE" ;
VAL_ 1883 CrgBedVwAutoLgtCstAvlFlg7 0 "FALSE" 1 "TRUE" ;
VAL_ 1883 CrgBedVwAutoLgtCstAvlFlg6 0 "FALSE" 1 "TRUE" ;
VAL_ 1883 CrgBedVwAutoLgtCstAvlFlg5 0 "FALSE" 1 "TRUE" ;
VAL_ 1883 CrgBedVwAutoLgtCstAvlFlg4 0 "FALSE" 1 "TRUE" ;
VAL_ 1883 CrgBedVwAutoLgtCstAvlFlg3 0 "FALSE" 1 "TRUE" ;
VAL_ 1883 CrgBedVwAutoLgtCstAvlFlg2 0 "FALSE" 1 "TRUE" ;
VAL_ 1883 CrgBedVwAutoLgtCstAvlFlg1 0 "FALSE" 1 "TRUE" ;
VAL_ 1883 JckKnfDtnCstAvlFlg7 0 "FALSE" 1 "TRUE" ;
VAL_ 1883 JckKnfDtnCstAvlFlg6 0 "FALSE" 1 "TRUE" ;
VAL_ 1883 JckKnfDtnCstAvlFlg5 0 "FALSE" 1 "TRUE" ;
VAL_ 1883 JckKnfDtnCstAvlFlg4 0 "FALSE" 1 "TRUE" ;
VAL_ 1883 JckKnfDtnCstAvlFlg3 0 "FALSE" 1 "TRUE" ;
VAL_ 1883 JckKnfDtnCstAvlFlg2 0 "FALSE" 1 "TRUE" ;
VAL_ 1953 VwgVwprtZmdVarActv 0 "FALSE" 1 "TRUE" ;
VAL_ 1953 DlvryModeVwgCstAvlFlg7 0 "FALSE" 1 "TRUE" ;
VAL_ 1953 DlvryModeVwgCstAvlFlg6 0 "FALSE" 1 "TRUE" ;
VAL_ 1953 DlvryModeVwgCstAvlFlg5 0 "FALSE" 1 "TRUE" ;
VAL_ 1953 DlvryModeVwgCstAvlFlg4 0 "FALSE" 1 "TRUE" ;
VAL_ 1953 DlvryModeVwgCstAvlFlg3 0 "FALSE" 1 "TRUE" ;
VAL_ 1953 DlvryModeVwgCstAvlFlg2 0 "FALSE" 1 "TRUE" ;
VAL_ 1953 DlvryModeVwgCstAvlFlg1 0 "FALSE" 1 "TRUE" ;
VAL_ 1953 VwgVwprtZoomBtnPrsnt 0 "FALSE" 1 "TRUE" ;
VAL_ 1114 VwgCtlBtnPrsncBedHtch 0 "FALSE" 1 "TRUE" ;
VAL_ 1114 VwgCtlBtnAvlUndrBdyFwdStActv 0 "FALSE" 1 "TRUE" ;
VAL_ 1114 VwgCtlBtnAvlUndrBdyFwdRwdStActv 0 "FALSE" 1 "TRUE" ;
VAL_ 1114 VwgCtlBtnAvlTopDnVwActv 0 "FALSE" 1 "TRUE" ;
VAL_ 1114 DlvryModeVwgCstSetAval 0 "FALSE" 1 "TRUE" ;
VAL_ 1114 DlvryModeVwgCstCurrSetVal 0 "Setting Unknown" 1 "Off" 2 "On" ;
VAL_ 1114 VwgCtlBtnPrsncFrtPrspctv 0 "FALSE" 1 "TRUE" ;
VAL_ 1114 VwgCtlBtnPrsncFrtOvrhd 0 "FALSE" 1 "TRUE" ;
VAL_ 1114 VwgCtlBtnPrsncFrtJnctn 0 "FALSE" 1 "TRUE" ;
VAL_ 1114 VwgCtlBtnPrsncDynGdlns 0 "FALSE" 1 "TRUE" ;
VAL_ 1114 VwgCtlBtnPrsncCurbOvrhd 0 "FALSE" 1 "TRUE" ;
VAL_ 1114 VwgCtlBtnPrsncCurb 0 "FALSE" 1 "TRUE" ;
VAL_ 1114 VwgCtlBtnPrsncCrgBed 0 "FALSE" 1 "TRUE" ;
VAL_ 1114 VwgCtlBtnPrsncBowl 0 "FALSE" 1 "TRUE" ;
VAL_ 1114 VwgCtlBtnPrsncSdRwd 0 "FALSE" 1 "TRUE" ;
VAL_ 1114 VwgCtlBtnPrsncSdFwd 0 "FALSE" 1 "TRUE" ;
VAL_ 1114 VwgCtlBtnPrsncRrPrspctv 0 "FALSE" 1 "TRUE" ;
VAL_ 1114 VwgCtlBtnPrsncRrOvrhd 0 "FALSE" 1 "TRUE" ;
VAL_ 1114 VwgCtlBtnPrsncRrJnctn 0 "FALSE" 1 "TRUE" ;
VAL_ 1114 VwgCtlBtnPrsncRrHtch 0 "FALSE" 1 "TRUE" ;
VAL_ 1114 VwgCtlBtnPrsncJP 0 "FALSE" 1 "TRUE" ;
VAL_ 1114 VwgCtlBtnPrsncInvsblTrlr 0 "FALSE" 1 "TRUE" ;
VAL_ 1114 VwgCtlBtnPrsncUndrBdyFwdRwdSt 0 "FALSE" 1 "TRUE" ;
VAL_ 1114 VwgCtlBtnPrsncUndrBdyFwd 0 "FALSE" 1 "TRUE" ;
VAL_ 1114 VwgCtlBtnPrsncTrlrTowMir 0 "FALSE" 1 "TRUE" ;
VAL_ 1114 VwgCtlBtnPrsncTrlrGdlns 0 "FALSE" 1 "TRUE" ;
VAL_ 1114 VwgCtlBtnPrsncTrlrAux1Cmbd 0 "FALSE" 1 "TRUE" ;
VAL_ 1114 VwgCtlBtnPrsncTrlrAux1 0 "FALSE" 1 "TRUE" ;
VAL_ 1114 VwgCtlBtnPrsncTransparentHood 0 "FALSE" 1 "TRUE" ;
VAL_ 1114 VwgCtlBtnPrsncTopDnSrrndVw 0 "FALSE" 1 "TRUE" ;
VAL_ 1114 VwgVwprtStsTopDnVwActv 0 "FALSE" 1 "TRUE" ;
VAL_ 1114 VwgVwprtNtfnActv 0 "FALSE" 1 "TRUE" ;
VAL_ 1114 VwgCtlBtnPrsncTrlrAux2 0 "FALSE" 1 "TRUE" ;
VAL_ 1114 VwgCtlBtnPrsncZmdBowl 0 "FALSE" 1 "TRUE" ;
VAL_ 1114 VwgCtlBtnPrsncUndrBdyRwd 0 "FALSE" 1 "TRUE" ;
VAL_ 1114 VwgCtlBtnPrsncUndrBdyFwdSt 0 "FALSE" 1 "TRUE" ;
VAL_ 1114 TrlrJckKnfVisAlrtReq 0 "Unknown" 1 "No Alert" 2 "Phase 1 Alert" 3 "Phase 2 Alert" ;
VAL_ 1114 TrlrCamCalPrgs_Inv 0 "FALSE" 1 "TRUE" ;
VAL_ 1984 DMPDAutoClsTmLFCstSetAval 0 "FALSE" 1 "TRUE" ;
VAL_ 1984 DMPDAutoClsTmLFCstAvlFlg7 0 "FALSE" 1 "TRUE" ;
VAL_ 1984 DMPDAutoClsTmLFCstAvlFlg6 0 "FALSE" 1 "TRUE" ;
VAL_ 1984 DMPDAutoClsTmLFCstAvlFlg5 0 "FALSE" 1 "TRUE" ;
VAL_ 1984 DMPDAutoClsTmLFCstAvlFlg4 0 "FALSE" 1 "TRUE" ;
VAL_ 1984 DMPDAutoClsTmLFCstAvlFlg3 0 "FALSE" 1 "TRUE" ;
VAL_ 1984 DMPDAutoClsTmLFCstAvlFlg2 0 "FALSE" 1 "TRUE" ;
VAL_ 1984 DMPDAutoClsTmLFCstAvlFlg1 0 "FALSE" 1 "TRUE" ;
VAL_ 1984 DMPDClsOutofPrkLFCstSetAval 0 "FALSE" 1 "TRUE" ;
VAL_ 1984 DMPDClsOutofPrkLFCstAvlFlg7 0 "FALSE" 1 "TRUE" ;
VAL_ 1984 DMPDClsOutofPrkLFCstAvlFlg6 0 "FALSE" 1 "TRUE" ;
VAL_ 1984 DMPDClsOutofPrkLFCstAvlFlg5 0 "FALSE" 1 "TRUE" ;
VAL_ 1984 DMPDClsOutofPrkLFCstAvlFlg4 0 "FALSE" 1 "TRUE" ;
VAL_ 1984 DMPDClsOutofPrkLFCstAvlFlg3 0 "FALSE" 1 "TRUE" ;
VAL_ 1984 DMPDClsOutofPrkLFCstAvlFlg2 0 "FALSE" 1 "TRUE" ;
VAL_ 1984 DMPDClsOutofPrkLFCstAvlFlg1 0 "FALSE" 1 "TRUE" ;
VAL_ 1984 DMPDDOBlkhdDrOpnLFCstSetAval 0 "FALSE" 1 "TRUE" ;
VAL_ 1984 DMPDDOBlkhdDrOpnLFCstAvlFlg7 0 "FALSE" 1 "TRUE" ;
VAL_ 1984 DMPDDOBlkhdDrOpnLFCstAvlFlg6 0 "FALSE" 1 "TRUE" ;
VAL_ 1984 DMPDDOBlkhdDrOpnLFCstAvlFlg5 0 "FALSE" 1 "TRUE" ;
VAL_ 1984 DMPDDOBlkhdDrOpnLFCstAvlFlg4 0 "FALSE" 1 "TRUE" ;
VAL_ 1984 DMPDDOBlkhdDrOpnLFCstAvlFlg3 0 "FALSE" 1 "TRUE" ;
VAL_ 1984 DMPDDOBlkhdDrOpnLFCstAvlFlg2 0 "FALSE" 1 "TRUE" ;
VAL_ 1984 DMPDDOBlkhdDrOpnLFCstAvlFlg1 0 "FALSE" 1 "TRUE" ;
VAL_ 1984 SCAOOAByKeyFobLFCstSetAval 0 "FALSE" 1 "TRUE" ;
VAL_ 1984 SCAOOAByKeyFobLFCstAvlFlg7 0 "FALSE" 1 "TRUE" ;
VAL_ 1984 SCAOOAByKeyFobLFCstAvlFlg6 0 "FALSE" 1 "TRUE" ;
VAL_ 1984 SCAOOAByKeyFobLFCstAvlFlg5 0 "FALSE" 1 "TRUE" ;
VAL_ 1984 SCAOOAByKeyFobLFCstAvlFlg4 0 "FALSE" 1 "TRUE" ;
VAL_ 1984 SCAOOAByKeyFobLFCstAvlFlg3 0 "FALSE" 1 "TRUE" ;
VAL_ 1984 SCAOOAByKeyFobLFCstAvlFlg2 0 "FALSE" 1 "TRUE" ;
VAL_ 1984 SCAOOAByKeyFobLFCstAvlFlg1 0 "FALSE" 1 "TRUE" ;
VAL_ 1984 SCAOOAByVirtKeyLFCstSetAval 0 "FALSE" 1 "TRUE" ;
VAL_ 1984 SCAOOAByVirtKeyLFCstAvlFlg7 0 "FALSE" 1 "TRUE" ;
VAL_ 1984 SCAOOAByVirtKeyLFCstAvlFlg6 0 "FALSE" 1 "TRUE" ;
VAL_ 1984 SCAOOAByVirtKeyLFCstAvlFlg5 0 "FALSE" 1 "TRUE" ;
VAL_ 1984 SCAOOAByVirtKeyLFCstAvlFlg4 0 "FALSE" 1 "TRUE" ;
VAL_ 1984 SCAOOAByVirtKeyLFCstAvlFlg3 0 "FALSE" 1 "TRUE" ;
VAL_ 1984 SCAOOAByVirtKeyLFCstAvlFlg2 0 "FALSE" 1 "TRUE" ;
VAL_ 1984 SCAOOAByVirtKeyLFCstAvlFlg1 0 "FALSE" 1 "TRUE" ;
VAL_ 1984 SCAPDBrktoClsLFCstSetAval 0 "FALSE" 1 "TRUE" ;
VAL_ 1984 SCAPDBrktoClsLFCstAvlFlg7 0 "FALSE" 1 "TRUE" ;
VAL_ 1984 SCAPDBrktoClsLFCstAvlFlg6 0 "FALSE" 1 "TRUE" ;
VAL_ 1984 SCAPDBrktoClsLFCstAvlFlg5 0 "FALSE" 1 "TRUE" ;
VAL_ 1984 SCAPDBrktoClsLFCstAvlFlg4 0 "FALSE" 1 "TRUE" ;
VAL_ 1984 SCAPDBrktoClsLFCstAvlFlg3 0 "FALSE" 1 "TRUE" ;
VAL_ 1984 SCAPDBrktoClsLFCstAvlFlg2 0 "FALSE" 1 "TRUE" ;
VAL_ 1984 SCAPDBrktoClsLFCstAvlFlg1 0 "FALSE" 1 "TRUE" ;
VAL_ 1984 SCAPDOpnMaxTrvlCstSetAval 0 "FALSE" 1 "TRUE" ;
VAL_ 1984 SCAPDOpnMaxTrvlCstAvlFlg7 0 "FALSE" 1 "TRUE" ;
VAL_ 1984 SCAPDOpnMaxTrvlCstAvlFlg6 0 "FALSE" 1 "TRUE" ;
VAL_ 1984 SCAPDOpnMaxTrvlCstAvlFlg5 0 "FALSE" 1 "TRUE" ;
VAL_ 1984 SCAPDOpnMaxTrvlCstAvlFlg4 0 "FALSE" 1 "TRUE" ;
VAL_ 1984 SCAPDOpnMaxTrvlCstAvlFlg3 0 "FALSE" 1 "TRUE" ;
VAL_ 1984 SCAPDOpnMaxTrvlCstAvlFlg2 0 "FALSE" 1 "TRUE" ;
VAL_ 1984 SCAPDOpnMaxTrvlCstAvlFlg1 0 "FALSE" 1 "TRUE" ;
VAL_ 1984 DMPDClsOutofPrkLFCstCurrSetVal 0 "Setting Unknown" 1 "Off" 2 "On" ;
VAL_ 1984 DMPDAutoClsTmLFCstCurrSetVal 0 "Setting Unknown" 1 "Standard" 2 "Extended" 3 "Keep Open" ;
VAL_ 1984 SCAPwrDrMtnLFVirtCtlAval 0 "Not Available" 1 "Available" ;
VAL_ 1060 PwrSdClsrLFBlckdIndOn 0 "FALSE" 1 "TRUE" ;
VAL_ 1060 PwrSdClsrLFServIndOn 0 "FALSE" 1 "TRUE" ;
VAL_ 1059 PwrSdClsrLRBlckdIndOn 0 "FALSE" 1 "TRUE" ;
VAL_ 1059 PwrSdClsrLRServIndOn 0 "FALSE" 1 "TRUE" ;
VAL_ 1188 EngOilTmp_Inv 0 "FALSE" 1 "TRUE" ;
VAL_ 1188 FuelConsmpHvyIndReq 0 "No Indication" 1 "Range" 2 "Low Fuel and Range" ;
VAL_ 1792 DslExFldTpWrngIndRq 0 "No Indication" 1 "Warning Level 1" 2 "Warning Level 2" 3 "Warning Level 3" 4 "Warning Level 4" 5 "Warning Level 5" 6 "Warning Level 6" 7 "Warning Level 7" 8 "Warning Level 8" 9 "Warning Level 9" 10 "Warning Level 10" 11 "Warning Level 11" 12 "Warning Level 12" 13 "Warning Level 13" 14 "Warning Level 14" 15 "Warning Level 15" ;
VAL_ 1792 DslExFldCnWrngIndRq 0 "No Indication" 1 "Warning Level 1" 2 "Warning Level 2" 3 "Warning Level 3" 4 "Warning Level 4" 5 "Warning Level 5" 6 "Warning Level 6" 7 "Warning Level 7" 8 "Warning Level 8" 9 "Warning Level 9" 10 "Warning Level 10" 11 "Warning Level 11" 12 "Warning Level 12" 13 "Warning Level 13" 14 "Warning Level 14" 15 "Warning Level 15" ;
VAL_ 1792 DslExhFldQlyWrngIReq 0 "No Indication" 1 "Warning Level 1" 2 "Warning Level 2" 3 "Warning Level 3" 4 "Warning Level 4" 5 "Warning Level 5" 6 "Warning Level 6" 7 "Warning Level 7" 8 "Warning Level 8" 9 "Warning Level 9" 10 "Warning Level 10" 11 "Warning Level 11" 12 "Warning Level 12" 13 "Warning Level 13" 14 "Warning Level 14" 15 "Warning Level 15" ;
VAL_ 1792 DslExNxEmWrngIndRq 0 "No Indication" 1 "Warning Level 1" 2 "Warning Level 2" 3 "Warning Level 3" 4 "Warning Level 4" 5 "Warning Level 5" 6 "Warning Level 6" 7 "Warning Level 7" 8 "Warning Level 8" 9 "Warning Level 9" 10 "Warning Level 10" 11 "Warning Level 11" 12 "Warning Level 12" 13 "Warning Level 13" 14 "Warning Level 14" 15 "Warning Level 15" ;
VAL_ 1792 DslExhFldRmnDist_Inv 0 "FALSE" 1 "TRUE" ;
VAL_ 1792 DslExhFldWrngIdRqER 0 "No Indication" 1 "Warning Level 1" 2 "Warning Level 2" 3 "Warning Level 3" 4 "Warning Level 4" 5 "Warning Level 5" 6 "Warning Level 6" 7 "Warning Level 7" 8 "Warning Level 8" 9 "Warning Level 9" 10 "Warning Level 10" 11 "Warning Level 11" 12 "Warning Level 12" 13 "Warning Level 13" 14 "Warning Level 14" 15 "Warning Level 15" ;
VAL_ 1792 ASIRI_Ind05 0 "FALSE" 1 "TRUE" ;
VAL_ 1792 ASIRI_Ind04 0 "FALSE" 1 "TRUE" ;
VAL_ 1792 ASIRI_Ind03 0 "FALSE" 1 "TRUE" ;
VAL_ 1792 ASIRI_Ind02 0 "FALSE" 1 "TRUE" ;
VAL_ 1792 ASIRI_Ind01 0 "FALSE" 1 "TRUE" ;
VAL_ 1792 FstIdlModeIndReq 0 "No Indication" 1 "On" 2 "Off" 3 "Unavailable" ;
VAL_ 1792 CkFlFilrCapIO 0 "FALSE" 1 "TRUE" ;
VAL_ 1792 CbnHtrWrmUpIndOn 0 "FALSE" 1 "TRUE" ;
VAL_ 1792 AppCltchAutSrtIO 0 "FALSE" 1 "TRUE" ;
VAL_ 1792 ASIRI_Ind08 0 "FALSE" 1 "TRUE" ;
VAL_ 1792 ASIRI_Ind07 0 "FALSE" 1 "TRUE" ;
VAL_ 1792 ASIRI_Ind06 0 "FALSE" 1 "TRUE" ;
VAL_ 1273 PTOSet1SpdCstCurrSetVal 0 "Setting Unknown" 1 "RPM 1100" 2 "RPM 1200" 3 "RPM 1300" 4 "RPM 1400" 5 "RPM 1500" 6 "RPM 1600" 7 "RPM 1700" 8 "RPM 1800" 9 "RPM 1900" 10 "RPM 2000" 11 "RPM 2100" 12 "RPM 2200" 13 "RPM 2300" 14 "RPM 2400" 15 "RPM 2500" ;
VAL_ 1273 PTOEngRunTmrCstCurrSetVal 0 "Setting Unknown" 1 "Min 10" 2 "Min 30" 3 "Min 90" 4 "Min 120" 5 "Min 150" 6 "Min 180" 7 "Min 210" 8 "Min 240" 9 "Min 270" 10 "Min 300" 11 "Min 330" 12 "Min 360" 13 "Min 390" 14 "Min 420" 15 "Min 450" ;
VAL_ 1273 MnlTrnsIndReq 0 "No Indication" 1 "Indication 1" 2 "Indication 2" 3 "Indication 3" ;
VAL_ 1273 EngAirFiltMonSts 0 "OK" 1 "Replace Air Filter Soon" 2 "Replace Air Filter Now" 3 "Fault Present" 4 "Disabled" 5 "No Action" ;
VAL_ 1273 PTOSet2SpdCstCurrSetVal 0 "Setting Unknown" 1 "RPM 1700" 2 "RPM 1800" 3 "RPM 1900" 4 "RPM 2000" 5 "RPM 2100" 6 "RPM 2200" 7 "RPM 2300" 8 "RPM 2400" 9 "RPM 2500" 10 "RPM 2600" 11 "RPM 2700" 12 "RPM 2800" 13 "RPM 2900" 14 "RPM 3000" 15 "RPM 3100" ;
VAL_ 1273 PTOTpStpSpdCstCurrSetVal 0 "Setting Unknown" 1 "RPM 5" 2 "RPM 10" 3 "RPM 25" 4 "RPM 50" 5 "RPM 100" 6 "RPM 250" 7 "RPM 500" ;
VAL_ 1273 PTOStndbySpdCstCurrSetVal 0 "Setting Unknown" 1 "RPM 900" 2 "RPM 1000" 3 "RPM 1100" 4 "RPM 1200" 5 "RPM 1300" 6 "RPM 1400" 7 "RPM 1500" ;
VAL_ 1273 EngHtStpEngIO 0 "FALSE" 1 "TRUE" ;
VAL_ 1273 EngHtFlEnrchmntIO 0 "FALSE" 1 "TRUE" ;
VAL_ 1273 PTOModeCstCurrSetVal 0 "Setting Unknown" 1 "Standard" 2 "Remote" ;
VAL_ 1273 PTOEngmntStsInd 0 "No Indication" 1 "Continuous Indication" 2 "Slow Flashing Indication" 3 "Fast Flashing Indication" ;
VAL_ 1273 PTOEngSpdTypCstCurrSetVal 0 "Setting Unknown" 1 "Preset" 2 "Variable" ;
VAL_ 1273 EngWtrInFlIO 0 "FALSE" 1 "TRUE" ;
VAL_ 1273 EngSpdLmtnMdAct 0 "FALSE" 1 "TRUE" ;
VAL_ 1273 EngShtdwnPndgIO 0 "FALSE" 1 "TRUE" ;
VAL_ 1273 EngOilStrvtnIO 0 "FALSE" 1 "TRUE" ;
VAL_ 1273 EngOilPrsLwIO 0 "FALSE" 1 "TRUE" ;
VAL_ 1273 EngOilLvlLwIO 0 "FALSE" 1 "TRUE" ;
VAL_ 1273 EngOilHotIO 0 "FALSE" 1 "TRUE" ;
VAL_ 1273 EngOilChngIO 0 "FALSE" 1 "TRUE" ;
VAL_ 1273 PTOMblModeTransInGrIndOn 0 "FALSE" 1 "TRUE" ;
VAL_ 1273 PTOEngUpnBrkRelIndOn 0 "FALSE" 1 "TRUE" ;
VAL_ 1273 PTOEngSpdTypCstSetAval 0 "FALSE" 1 "TRUE" ;
VAL_ 1273 PTOEngRunTmrCstSetAval 0 "FALSE" 1 "TRUE" ;
VAL_ 1273 PTODisengCruzCtlIndOn 0 "FALSE" 1 "TRUE" ;
VAL_ 1273 PTOAccelUpnBrkRelIndOn 0 "FALSE" 1 "TRUE" ;
VAL_ 1273 PTExPrtclFltrWrnIO 0 "FALSE" 1 "TRUE" ;
VAL_ 1273 PTExPrtclFltrWrn2IO 0 "FALSE" 1 "TRUE" ;
VAL_ 1273 PTOSet2SpdCstSetAval 0 "FALSE" 1 "TRUE" ;
VAL_ 1273 PTOSet1SpdCstSetAval 0 "FALSE" 1 "TRUE" ;
VAL_ 1273 PTOServIndOn 0 "FALSE" 1 "TRUE" ;
VAL_ 1273 PTORelBrkPedIndOn 0 "FALSE" 1 "TRUE" ;
VAL_ 1273 PTORelAccelPedIndOn 0 "FALSE" 1 "TRUE" ;
VAL_ 1273 PTORdcEngSpdIndOn 0 "FALSE" 1 "TRUE" ;
VAL_ 1273 PTOPrssAndRelBrkPedIndOn 0 "FALSE" 1 "TRUE" ;
VAL_ 1273 PTOModeCstSetAval 0 "FALSE" 1 "TRUE" ;
VAL_ 1273 TrnsSkpShftIO 0 "FALSE" 1 "TRUE" ;
VAL_ 1273 ServFuelSysTrnsfrPmpIO 0 "FALSE" 1 "TRUE" ;
VAL_ 1273 PTWrmgWtToShftIO 0 "FALSE" 1 "TRUE" ;
VAL_ 1273 PTOTransInGrIndOn 0 "FALSE" 1 "TRUE" ;
VAL_ 1273 PTOTpStpSpdCstSetAval 0 "FALSE" 1 "TRUE" ;
VAL_ 1273 PTOStndbySpdCstSetAval 0 "FALSE" 1 "TRUE" ;
VAL_ 1273 PTOSetPrkBrkIndOn 0 "FALSE" 1 "TRUE" ;
VAL_ 1187 OTARC_RejCrdntnECP_X1 0 "FALSE" 1 "TRUE" ;
VAL_ 1187 OTARC_RejCrdntnECP_S 0 "FALSE" 1 "TRUE" ;
VAL_ 1187 OTARC_RejCrdntnECP_MC 0 "FALSE" 1 "TRUE" ;
VAL_ 1187 OTARC_RejCrdntnECM 0 "FALSE" 1 "TRUE" ;
VAL_ 1187 OTARC_RejCrdntnEBCM 0 "FALSE" 1 "TRUE" ;
VAL_ 1187 OTARC_RejCrdntnBSM_MH 0 "FALSE" 1 "TRUE" ;
VAL_ 1187 OTARC_RejCrdntnBSM 0 "FALSE" 1 "TRUE" ;
VAL_ 1187 OTARC_RejCrdntnBCM 0 "FALSE" 1 "TRUE" ;
VAL_ 1187 OTARC_RejCrdntnLIB_48V 0 "FALSE" 1 "TRUE" ;
VAL_ 1187 OTARC_RejCrdntnECP_E 0 "FALSE" 1 "TRUE" ;
VAL_ 1187 OTARC_RejCrdntnVECM 0 "FALSE" 1 "TRUE" ;
VAL_ 1187 OTARC_RejCrdntnECP_S2 0 "FALSE" 1 "TRUE" ;
VAL_ 1187 OTARC_RejCrdntnVICM 0 "FALSE" 1 "TRUE" ;
VAL_ 1187 OTARC_RejCrdntnSBM 0 "FALSE" 1 "TRUE" ;
VAL_ 1187 OTARC_RejCrdntnCGM 0 "FALSE" 1 "TRUE" ;
VAL_ 1187 OTARC_RejCrdntnECP_X2 0 "FALSE" 1 "TRUE" ;
VAL_ 1187 OTARC_RejCrdntnECU_27 0 "FALSE" 1 "TRUE" ;
VAL_ 1187 OTARC_RejCrdntnECU_26 0 "FALSE" 1 "TRUE" ;
VAL_ 1187 OTARC_RejCrdntnECU_25 0 "FALSE" 1 "TRUE" ;
VAL_ 1187 OTARC_RejCrdntnECU_24 0 "FALSE" 1 "TRUE" ;
VAL_ 1187 OTARC_RejCrdntnECU_23 0 "FALSE" 1 "TRUE" ;
VAL_ 1187 OTARC_RejCrdntnECU_22 0 "FALSE" 1 "TRUE" ;
VAL_ 1187 OTARC_RejCrdntnECU_21 0 "FALSE" 1 "TRUE" ;
VAL_ 1187 OTARC_RejCrdntnECU_20 0 "FALSE" 1 "TRUE" ;
VAL_ 1187 OTARC_RejCrdntnTCM 0 "FALSE" 1 "TRUE" ;
VAL_ 1187 OTARC_RejCrdntnICCM 0 "FALSE" 1 "TRUE" ;
VAL_ 1187 OTARC_RejCrdntnFICM 0 "FALSE" 1 "TRUE" ;
VAL_ 1187 OTARC_RejCrdntnECU_32 0 "FALSE" 1 "TRUE" ;
VAL_ 1187 OTARC_RejCrdntnECU_31 0 "FALSE" 1 "TRUE" ;
VAL_ 1187 OTARC_RejCrdntnECU_30 0 "FALSE" 1 "TRUE" ;
VAL_ 1187 OTARC_RejCrdntnECU_29 0 "FALSE" 1 "TRUE" ;
VAL_ 1187 OTARC_RejCrdntnECU_28 0 "FALSE" 1 "TRUE" ;
VAL_ 720 PrplDispBatPwr_Inv 0 "FALSE" 1 "TRUE" ;
VAL_ 720 PrplDispBatPwr_DuD 0 "FALSE" 1 "TRUE" ;
VAL_ 720 PrplDispEngPwr_Inv 0 "FALSE" 1 "TRUE" ;
VAL_ 720 PrplDispEngPwr_DuD 0 "FALSE" 1 "TRUE" ;
VAL_ 720 BatPrplDispTrqLvlPct_DuD 0 "FALSE" 1 "TRUE" ;
VAL_ 720 PrplDispBatTrq_Inv 0 "FALSE" 1 "TRUE" ;
VAL_ 720 PrplDispBatTrq_DuD 0 "FALSE" 1 "TRUE" ;
VAL_ 1797 CustNonUsblSOC_Inv 0 "FALSE" 1 "TRUE" ;
VAL_ 1797 CustNonUsblSOC_DuD 0 "FALSE" 1 "TRUE" ;
VAL_ 1797 CustUsblSOC_Inv 0 "FALSE" 1 "TRUE" ;
VAL_ 1797 CustUsblSOC_DuD 0 "FALSE" 1 "TRUE" ;
VAL_ 1797 BatPrplDispPwrLvlPct_DuD 0 "FALSE" 1 "TRUE" ;
VAL_ 1497 ElecMtrATach_Inv 0 "FALSE" 1 "TRUE" ;
VAL_ 1497 ElecMtrATach_DuD 0 "FALSE" 1 "TRUE" ;
VAL_ 1497 HiVltgBatAvgTemp_DuD 0 "FALSE" 1 "TRUE" ;
VAL_ 1497 HiVltgBatAvgTemp_Inv 0 "FALSE" 1 "TRUE" ;
VAL_ 1497 EngPrplDispPwrLvlPct_DuD 0 "FALSE" 1 "TRUE" ;
VAL_ 1497 EngRnngDueToVehSpdIndOn 0 "FALSE" 1 "TRUE" ;
VAL_ 1497 ElecAllWhlDrvIndOn 0 "FALSE" 1 "TRUE" ;
VAL_ 1497 DischrgPwrLtdIndOn 0 "FALSE" 1 "TRUE" ;
VAL_ 1497 DischrgPwrLtdDispPctVsbl 0 "FALSE" 1 "TRUE" ;
VAL_ 1497 HiVltgBatLmtnDueToTempInd 0 "Normal" 1 "Cold" 2 "Hot" ;
VAL_ 1268 HybModeDisp 0 "No Action" 1 "Battery Power" 2 "Engine Power" 3 "Hybrid Power" 4 "Charging with Engine Off" 5 "Charging with Engine On" 6 "Neutral Engine On" 7 "Neutral Engine Off" 8 "Engine Charging" 9 "Engine Power Rear with Battery Front" 10 "Engine Power Rear with Front Wheel Regen" 11 "Undetermined" 12 "Default and Accessory" 13 "Engine Idle" 14 "Reserved 1" 15 "Reserved 2" 16 "Reserved 3" ;
VAL_ 1268 HTD1_FuelAvdd_DuD 0 "FALSE" 1 "TRUE" ;
VAL_ 1268 InstnsFuelEconHybOvrrdReq 0 "No Action" 1 "Min Fuel Economy" 2 "Max Fuel Economy" 3 "Auto Stop" 4 "EV" ;
VAL_ 1268 HybModeDispVehCfg 0 "No Action" 1 "Not in Motion" 2 "FWD" 3 "RWD" 4 "4WD" ;
VAL_ 1268 HiVltgChrgrSysSts 0 "Default" 1 "Idle" 2 "Initializing" 3 "Active" 4 "Complete" 5 "Aborted" 6 "Utility Override Active" 7 "Utility Override Reduced Power" 8 "Pause Due to Update" 9 "Connection Unpowered" 10 "Unconnected" 11 "Offboard Energy Transfer Active" ;
VAL_ 1268 HybShfToPrkIndOn 0 "FALSE" 1 "TRUE" ;
VAL_ 1268 HiVltgSysDsbld 0 "FALSE" 1 "TRUE" ;
VAL_ 1268 JmpStrtSts 0 "Inactive" 1 "In Progress" 2 "Complete" 3 "Power Mode" 4 "Disabled" ;
VAL_ 1798 PrplDispTotPwr_DuD 0 "FALSE" 1 "TRUE" ;
VAL_ 1798 PrplDispTotPwr_Inv 0 "FALSE" 1 "TRUE" ;
VAL_ 1798 ServHybSysIndOn 0 "FALSE" 1 "TRUE" ;
VAL_ 1798 RegenPwrLimdIndOn 0 "FALSE" 1 "TRUE" ;
VAL_ 1798 RegenPwrLimdDispPctVsbl 0 "FALSE" 1 "TRUE" ;
VAL_ 1798 PrplDispTotPwrUntDisp 0 "kilowatt" 1 "Horsepower" ;
VAL_ 1798 LossOfPrplIndOn 0 "FALSE" 1 "TRUE" ;
VAL_ 1798 ServHiVltgBatIndReq 0 "No Indication" 1 "Shut Down Soon" 2 "No Restart" ;
VAL_ 1267 BrkPadLifeFrtDistWrnIndReq 0 "No Action" 1 "Low" 2 "Display Distance" ;
VAL_ 1267 BrkPadLifeStsIndReq 0 "No Action" 1 "Not Present" 2 "Ok" 3 "Change Soon" 4 "Change Now" 5 "Disabled" 6 "Service" ;
VAL_ 1267 BrkPadLifeRrDistWrnIndReq 0 "No Action" 1 "Low" 2 "Display Distance" ;
VAL_ 1267 ESCSpdLtdIndReq 0 "No Indication" 1 "Countdown" 2 "Limited" ;
VAL_ 1267 HillDscntCtlRdcVehSpdIndOn 0 "FALSE" 1 "TRUE" ;
VAL_ 1267 HillDscntCtlDispActvIndOn 0 "FALSE" 1 "TRUE" ;
VAL_ 1267 BrkPadLifeFrtCnfrmRplcmtIndOn 0 "FALSE" 1 "TRUE" ;
VAL_ 1267 BrkOvrhtdIndOn 0 "FALSE" 1 "TRUE" ;
VAL_ 1267 AllWhlDrvRcmndIndOn 0 "FALSE" 1 "TRUE" ;
VAL_ 1267 CrwlModeDndRsnIndReq 0 "No Indication" 1 "Unavailable" 2 "Brakes Overtemp" 3 "Shift to 4 High" 4 "Reduce Speed" ;
VAL_ 1267 BrksOvrht 0 "FALSE" 1 "TRUE" ;
VAL_ 1267 BrkSysTwoFtdDrvDtdIndOn 0 "FALSE" 1 "TRUE" ;
VAL_ 1267 BrkSysHillStrtAsstAvl 0 "FALSE" 1 "TRUE" ;
VAL_ 1267 BrkPadWrnIO 0 "FALSE" 1 "TRUE" ;
VAL_ 1267 BrkPadLifeRrCnfrmRplcmtIndOn 0 "FALSE" 1 "TRUE" ;
VAL_ 1799 LnchCtlWhlSlSts 0 "No Action" 1 "Five Percent" 2 "Five And A Half Percent" 3 "Six Percent" 4 "Six And A Half Percent" 5 "Seven Percent" 6 "Seven And A Half Percent" 7 "Eight Percent" 8 "Eight And A Half Percent" 9 "Nine Percent" 10 "Nine And A Half Percent" 11 "Ten Percent" 12 "Ten And A Half Percent" 13 "Eleven Percent" 14 "Eleven And a Half Percent" 15 "Twelve Percent" 16 "Twelve And A Half Percent" 17 "Thirteen Percent" 18 "Thirteen And A Half Percent" 19 "Fourteen Percent" 20 "Fourteen And A Half Percent" 21 "Fifteen Percent" ;
VAL_ 1799 LnchCtlEngRPMSts 0 "No Action" 1 "800" 2 "900" 3 "1000" 4 "1100" 5 "1200" 6 "1300" 7 "1400" 8 "1500" 9 "1600" 10 "1700" 11 "1800" 12 "1900" 13 "2000" 14 "2100" 15 "2200" 16 "2300" 17 "2400" 18 "2500" 19 "2600" 20 "2700" 21 "2800" 22 "2900" 23 "3000" 24 "3100" 25 "3200" 26 "3300" 27 "3400" 28 "3500" 29 "3600" 30 "3700" 31 "3800" 32 "3900" 33 "4000" 34 "FlexibleRPM 1" 35 "FlexibleRPM 2" 36 "FlexibleRPM 3" 37 "FlexibleRPM 4" 38 "FlexibleRPM 5" ;
VAL_ 1799 DrvModeVisScreenSts 0 "No_Action" 1 "Custom" 2 "Personal" 3 "Sport" 4 "Snow_Ice" 5 "Weather" 6 "Tour" 7 "Track" 8 "Offroad" 9 "TowHaul" 10 "PerformanceSportPlus" 11 "Terrain" 12 "Baja" 13 "BoatRamp" ;
VAL_ 1799 EngSndPerfModeReq 0 "No Action" 1 "Tour" 2 "Sport_OffRoad" 3 "Track" 4 "Stealth" 5 "Max Power" 6 "Terrain" 7 "Performance Mode 7" ;
VAL_ 1799 PerfTracMgmtMode 0 "Disabled" 1 "Wet" 2 "Dry" 3 "Sport 1" 4 "Sport 2/Race 1" 5 "Race" 6 "Inactive" 7 "Pro" ;
VAL_ 1799 HillDscntCtlSysSts 0 "Unknown" 1 "Normal" 2 "Enabled" 3 "Active" 4 "Failed" ;
VAL_ 1799 SprtModeDrvlineVisDispVal 0 "Setting_Unknown" 1 "Custom_Mode_1" 2 "Custom_Mode_2" 3 "Custom_Mode_3" 4 "Custom_Mode_4" 5 "Custom_Mode_5" 6 "Custom_Mode_6" 7 "Custom_Mode_7" ;
VAL_ 1799 SprtModeBrkPedVisDispVal 0 "Setting_Unknown" 1 "Custom_Mode_1" 2 "Custom_Mode_2" 3 "Custom_Mode_3" 4 "Custom_Mode_4" 5 "Custom_Mode_5" 6 "Custom_Mode_6" 7 "Custom_Mode_7" ;
VAL_ 1799 SprtModeActvAeroVisDispVal 0 "Setting_Unknown" 1 "Custom_Mode_1" 2 "Custom_Mode_2" 3 "Custom_Mode_3" 4 "Custom_Mode_4" 5 "Custom_Mode_5" 6 "Custom_Mode_6" 7 "Custom_Mode_7" ;
VAL_ 1799 SprtModeRideHghtVisDispVal 0 "Setting_Unknown" 1 "Custom_Mode_1" 2 "Custom_Mode_2" 3 "Custom_Mode_3" 4 "Custom_Mode_4" 5 "Custom_Mode_5" 6 "Custom_Mode_6" 7 "Custom_Mode_7" ;
VAL_ 1799 SprtModePwrtrnVisDispVal 0 "Setting_Unknown" 1 "Custom_Mode_1" 2 "Custom_Mode_2" 3 "Custom_Mode_3" 4 "Custom_Mode_4" 5 "Custom_Mode_5" 6 "Custom_Mode_6" 7 "Custom_Mode_7" ;
VAL_ 1799 SprtModeESCVisDispVal 0 "Setting_Unknown" 1 "Custom_Mode_1" 2 "Custom_Mode_2" 3 "Custom_Mode_3" 4 "Custom_Mode_4" 5 "Custom_Mode_5" 6 "Custom_Mode_6" 7 "Custom_Mode_7" ;
VAL_ 1799 SprtModeSpnsnVisDispVal 0 "Setting_Unknown" 1 "Custom_Mode_1" 2 "Custom_Mode_2" 3 "Custom_Mode_3" 4 "Custom_Mode_4" 5 "Custom_Mode_5" 6 "Custom_Mode_6" 7 "Custom_Mode_7" ;
VAL_ 1799 SprtModeSndVisDispVal 0 "Setting_Unknown" 1 "Custom_Mode_1" 2 "Custom_Mode_2" 3 "Custom_Mode_3" 4 "Custom_Mode_4" 5 "Custom_Mode_5" 6 "Custom_Mode_6" 7 "Custom_Mode_7" ;
VAL_ 1799 ShfToPrkBfrExtIndOn 0 "FALSE" 1 "TRUE" ;
VAL_ 1799 HillDscntCtlVirtSwAvl 0 "Not Available" 1 "Available" ;
VAL_ 1799 WthrSnwModeStrgVisDispVal 0 "Setting_Unknown" 1 "Custom_Mode_1" 2 "Custom_Mode_2" 3 "Custom_Mode_3" 4 "Custom_Mode_4" 5 "Custom_Mode_5" 6 "Custom_Mode_6" 7 "Custom_Mode_7" ;
VAL_ 1799 SprtModeStrgVisDispVal 0 "Setting_Unknown" 1 "Custom_Mode_1" 2 "Custom_Mode_2" 3 "Custom_Mode_3" 4 "Custom_Mode_4" 5 "Custom_Mode_5" 6 "Custom_Mode_6" 7 "Custom_Mode_7" ;
VAL_ 1266 TkModeBrkPedVisDispVal 0 "Setting_Unknown" 1 "Custom_Mode_1" 2 "Custom_Mode_2" 3 "Custom_Mode_3" 4 "Custom_Mode_4" 5 "Custom_Mode_5" 6 "Custom_Mode_6" 7 "Custom_Mode_7" ;
VAL_ 1266 TkModeActvAeroVisDispVal 0 "Setting_Unknown" 1 "Custom_Mode_1" 2 "Custom_Mode_2" 3 "Custom_Mode_3" 4 "Custom_Mode_4" 5 "Custom_Mode_5" 6 "Custom_Mode_6" 7 "Custom_Mode_7" ;
VAL_ 1266 TireTrdTempSts 0 "Unknown" 1 "Cold" 2 "Cool" 3 "Normal" 4 "Warm" 5 "Hot" ;
VAL_ 1266 TkModePwrtrnVisDispVal 0 "Setting_Unknown" 1 "Custom_Mode_1" 2 "Custom_Mode_2" 3 "Custom_Mode_3" 4 "Custom_Mode_4" 5 "Custom_Mode_5" 6 "Custom_Mode_6" 7 "Custom_Mode_7" ;
VAL_ 1266 TkModeESCVisDispVal 0 "Setting_Unknown" 1 "Custom_Mode_1" 2 "Custom_Mode_2" 3 "Custom_Mode_3" 4 "Custom_Mode_4" 5 "Custom_Mode_5" 6 "Custom_Mode_6" 7 "Custom_Mode_7" ;
VAL_ 1266 TkModeDrvlineVisDispVal 0 "Setting_Unknown" 1 "Custom_Mode_1" 2 "Custom_Mode_2" 3 "Custom_Mode_3" 4 "Custom_Mode_4" 5 "Custom_Mode_5" 6 "Custom_Mode_6" 7 "Custom_Mode_7" ;
VAL_ 1266 TkModeSndVisDispVal 0 "Setting_Unknown" 1 "Custom_Mode_1" 2 "Custom_Mode_2" 3 "Custom_Mode_3" 4 "Custom_Mode_4" 5 "Custom_Mode_5" 6 "Custom_Mode_6" 7 "Custom_Mode_7" ;
VAL_ 1266 TkModeRideHghtVisDispVal 0 "Setting_Unknown" 1 "Custom_Mode_1" 2 "Custom_Mode_2" 3 "Custom_Mode_3" 4 "Custom_Mode_4" 5 "Custom_Mode_5" 6 "Custom_Mode_6" 7 "Custom_Mode_7" ;
VAL_ 1266 TourModeActvAeroVisDispVal 0 "Setting_Unknown" 1 "Custom_Mode_1" 2 "Custom_Mode_2" 3 "Custom_Mode_3" 4 "Custom_Mode_4" 5 "Custom_Mode_5" 6 "Custom_Mode_6" 7 "Custom_Mode_7" ;
VAL_ 1266 TkModeStrgVisDispVal 0 "Setting_Unknown" 1 "Custom_Mode_1" 2 "Custom_Mode_2" 3 "Custom_Mode_3" 4 "Custom_Mode_4" 5 "Custom_Mode_5" 6 "Custom_Mode_6" 7 "Custom_Mode_7" ;
VAL_ 1266 TkModeSpnsnVisDispVal 0 "Setting_Unknown" 1 "Custom_Mode_1" 2 "Custom_Mode_2" 3 "Custom_Mode_3" 4 "Custom_Mode_4" 5 "Custom_Mode_5" 6 "Custom_Mode_6" 7 "Custom_Mode_7" ;
VAL_ 1266 TourModeESCVisDispVal 0 "Setting_Unknown" 1 "Custom_Mode_1" 2 "Custom_Mode_2" 3 "Custom_Mode_3" 4 "Custom_Mode_4" 5 "Custom_Mode_5" 6 "Custom_Mode_6" 7 "Custom_Mode_7" ;
VAL_ 1266 TourModeDrvlineVisDispVal 0 "Setting_Unknown" 1 "Custom_Mode_1" 2 "Custom_Mode_2" 3 "Custom_Mode_3" 4 "Custom_Mode_4" 5 "Custom_Mode_5" 6 "Custom_Mode_6" 7 "Custom_Mode_7" ;
VAL_ 1266 TourModeBrkPedVisDispVal 0 "Setting_Unknown" 1 "Custom_Mode_1" 2 "Custom_Mode_2" 3 "Custom_Mode_3" 4 "Custom_Mode_4" 5 "Custom_Mode_5" 6 "Custom_Mode_6" 7 "Custom_Mode_7" ;
VAL_ 1266 TourModeRideHghtVisDispVal 0 "Setting_Unknown" 1 "Custom_Mode_1" 2 "Custom_Mode_2" 3 "Custom_Mode_3" 4 "Custom_Mode_4" 5 "Custom_Mode_5" 6 "Custom_Mode_6" 7 "Custom_Mode_7" ;
VAL_ 1266 TourModePwrtrnVisDispVal 0 "Setting_Unknown" 1 "Custom_Mode_1" 2 "Custom_Mode_2" 3 "Custom_Mode_3" 4 "Custom_Mode_4" 5 "Custom_Mode_5" 6 "Custom_Mode_6" 7 "Custom_Mode_7" ;
VAL_ 1266 TourModeStrgVisDispVal 0 "Setting_Unknown" 1 "Custom_Mode_1" 2 "Custom_Mode_2" 3 "Custom_Mode_3" 4 "Custom_Mode_4" 5 "Custom_Mode_5" 6 "Custom_Mode_6" 7 "Custom_Mode_7" ;
VAL_ 1266 TourModeSpnsnVisDispVal 0 "Setting_Unknown" 1 "Custom_Mode_1" 2 "Custom_Mode_2" 3 "Custom_Mode_3" 4 "Custom_Mode_4" 5 "Custom_Mode_5" 6 "Custom_Mode_6" 7 "Custom_Mode_7" ;
VAL_ 1266 TourModeSndVisDispVal 0 "Setting_Unknown" 1 "Custom_Mode_1" 2 "Custom_Mode_2" 3 "Custom_Mode_3" 4 "Custom_Mode_4" 5 "Custom_Mode_5" 6 "Custom_Mode_6" 7 "Custom_Mode_7" ;
VAL_ 1266 TrlrStbAsstActIO 0 "FALSE" 1 "TRUE" ;
VAL_ 1266 TrcCntrlOnIO 0 "FALSE" 1 "TRUE" ;
VAL_ 1266 TrcCntrlOffIO 0 "FALSE" 1 "TRUE" ;
VAL_ 1266 TnDrvTrCtrlOffUnvIndOn 0 "FALSE" 1 "TRUE" ;
VAL_ 1266 SrBkLwBkFlDrVisMsgRqOn 0 "FALSE" 1 "TRUE" ;
VAL_ 1266 TrcStbScrConfig 0 "None" 1 "TCS Only" 2 "TCS and ESC" 3 "TCS ESC and Comp" ;
VAL_ 721 EngIntkArBstPr_Inv 0 "FALSE" 1 "TRUE" ;
VAL_ 721 FlInjRlCtRstOcc 0 "FALSE" 1 "TRUE" ;
VAL_ 721 EngRcmndDwnsftIndOn 0 "FALSE" 1 "TRUE" ;
VAL_ 721 EngFuelInjnSysFltIndOn 0 "FALSE" 1 "TRUE" ;
VAL_ 721 IdlRecmndToClEngIO 0 "FALSE" 1 "TRUE" ;
VAL_ 721 FuelSysNEmsRltMlfActv 0 "FALSE" 1 "TRUE" ;
VAL_ 721 FuelFiltChgNowIndOn 0 "FALSE" 1 "TRUE" ;
VAL_ 1800 ChrgCordThftAlrtCstSetAval 0 "FALSE" 1 "TRUE" ;
VAL_ 1800 ChrgCordThftAlrtCstCurrSetVal 0 "No Action" 1 "Off" 2 "On" ;
VAL_ 1265 ChrgPwrLossAlrtCstSetAval 0 "FALSE" 1 "TRUE" ;
VAL_ 1265 ChrgrSysAudblIndCstCurrSetVal 0 "No Action" 1 "Off" 2 "On" ;
VAL_ 1265 ChrgPwrLossAlrtCstCurrSetVal 0 "No Action" 1 "Off" 2 "On" ;
VAL_ 1265 ChrgPortDrIndReq 0 "Inactive" 1 "Open Park" 2 "Open Moving" 3 "Fault" ;
VAL_ 1801 InsfcntTmtoCmpltChrgIndOn 0 "FALSE" 1 "TRUE" ;
VAL_ 1264 CntctrsOpnUndrTempIndOn 0 "FALSE" 1 "TRUE" ;
VAL_ 1264 ChrgrSysAudblIndCstSetAval 0 "FALSE" 1 "TRUE" ;
VAL_ 1264 ChrgStsPeekInScrnActvIndOn 0 "FALSE" 1 "TRUE" ;
VAL_ 1802 PrtblChrgCordLimCstSetAval 0 "FALSE" 1 "TRUE" ;
VAL_ 1802 OffBrdChrgStnFltDtd 0 "FALSE" 1 "TRUE" ;
VAL_ 1802 NeutCstdwnCertModeActvIndOn 0 "FALSE" 1 "TRUE" ;
VAL_ 1802 LocBsdChrgCstSetAval 0 "FALSE" 1 "TRUE" ;
VAL_ 1802 LocBsdChrgCstCurrSetVal 0 "No Action" 1 "Off" 2 "On" ;
VAL_ 1803 LBCPSS_PstnUpdtLoc 0 "No Action" 1 "Update Position 1" 2 "Update Position 2" 3 "Update Position 3" 4 "Update Position 4" ;
VAL_ 1803 LBCCDRR_PstnNumResp 0 "No Action" 1 "Clear Position 1" 2 "Clear Position 2" 3 "Clear Position 3" 4 "Clear Position 4" ;
VAL_ 1803 LBCCDRR_ClrStrdPstnResp 0 "No Action" 1 "Clear Position Request Acknowledged" 2 "Clear Position Request Performed" ;
VAL_ 1803 ServHybChrgSysIndOn 0 "FALSE" 1 "TRUE" ;
VAL_ 1803 LBCCF_Loc4PstnStrdIndOn 0 "FALSE" 1 "TRUE" ;
VAL_ 1803 LBCCF_Loc3PstnStrdIndOn 0 "FALSE" 1 "TRUE" ;
VAL_ 1803 LBCCF_Loc2PstnStrdIndOn 0 "FALSE" 1 "TRUE" ;
VAL_ 1803 LBCCF_Loc1PstnStrdIndOn 0 "FALSE" 1 "TRUE" ;
VAL_ 1803 LBCPSS_PstnUpdtSts 0 "No Action" 1 "Position Updated" 2 "Position Modified" ;
VAL_ 1262 VehLocSts 0 "Not Within Stored Regions" 1 "Within Stored Region 1" 2 "Within Stored Region 2" 3 "Within Stored Region 3" 4 "Within Stored Region 4" ;
VAL_ 1262 VehLocSts_Inv 0 "FALSE" 1 "TRUE" ;
VAL_ 1804 TODCSR_ChrgSchedDyOfWkResp 0 "No Action" 1 "Sunday" 2 "Monday" 3 "Tuesday" 4 "Wednesday" 5 "Thursday" 6 "Friday" 7 "Saturday" 8 "All Days Same" 9 "Monday to Friday Same" 10 "Saturday and Sunday Same" ;
VAL_ 1804 TODCSR_ChrgSchedCstSetVal 0 "No Action" 1 "Off" 2 "On" ;
VAL_ 1804 TODCSR_ERSPrdDyResp 0 "No Action" 1 "Weekday 1" 2 "Weekday 2" 3 "Weekday 3" 4 "Weekday 4" 5 "Weekday 5" 6 "Weekend 1" 7 "Weekend 2" 8 "Weekend 3" 9 "Weekend 4" 10 "Weekend 5" ;
VAL_ 1804 TODCSR_ERSCstSetVal 0 "No Action" 1 "Off" 2 "On" ;
VAL_ 1804 TODCSR_ERSPrdLvlResp 0 "No Action" 1 "Low Rate" 2 "Medium Rate" 3 "High Rate" 4 "Reserved 1" 5 "Invalid Rate" ;
VAL_ 1804 PrtblChrgCordLimCstSetResp 0 "No Action" 1 "Reduced" 2 "Maximum" ;
VAL_ 1804 TODCSR_ERSPrfResp 0 "No Action" 1 "Low Rate" 2 "Medium Rate" 3 "High Rate" ;
VAL_ 1804 TODCCbnPrcndtngSetResp 0 "No Action" 1 "Off" 2 "On" ;
VAL_ 1804 TODCSR_LocNumResp 0 "No Action" 1 "Not in Stored Location" 2 "Stored Location 1" 3 "Stored Location 2" 4 "Stored Location 3" 5 "Stored Location 4" ;
VAL_ 1804 TODCSR_LocChrgPwrLvlResp 0 "Unknown" 1 "Level 1" 2 "Level 2" 3 "DC" 4 "Wireless" ;
VAL_ 1804 UtlChrgIntfrIndOn 0 "FALSE" 1 "TRUE" ;
VAL_ 1261 TODCNP_DprtrDyOfWk 0 "Unknown" 1 "Sunday" 2 "Monday" 3 "Tuesday" 4 "Wednesday" 5 "Thursday" 6 "Friday" 7 "Saturday" ;
VAL_ 1261 TODCNP_Chrg 0 "No Action" 1 "Charge Now" 2 "Charge Later" 3 "Invalid" ;
VAL_ 1261 TODCNP_PCCLCstCurrSetVal 0 "No Action" 1 "Reduced" 2 "Maximum" ;
VAL_ 1261 TmOfDyChrgInvHMIEntIndReqd 0 "FALSE" 1 "TRUE" ;
VAL_ 1261 PrtblChrgCordLimSetExpIndOn 0 "FALSE" 1 "TRUE" ;
VAL_ 1261 RngPerHrGaindThisChrg_DuD 0 "FALSE" 1 "TRUE" ;
VAL_ 1261 RngGaindThisChrg_DuD 0 "FALSE" 1 "TRUE" ;
VAL_ 1261 TODCNextPlndCbnPrcndtngSetResp 0 "No Action" 1 "Off" 2 "On" ;
VAL_ 1260 EngyEconMeasUnt 0 "Distance Per Electrical Energy" 1 "Distance Per Volume Equivalent" 2 "Electrical Energy Per Distance" 3 "Volume Equivalent Per Distance" 4 "Electrical Energy Per Distance x 100" 5 "Volume Equivalent Per Distance x 100" ;
VAL_ 1806 ECHG_CurrEconRdy 0 "FALSE" 1 "TRUE" ;
VAL_ 1806 HiVltgChrgAbrtRsn 0 "No Action" 1 "Loss of AC" 2 "Unplugged Charging" 3 "Unplugged Delayed" 4 "Charge Failure" 5 "Cordset Fault" 6 "Cordset Delay" ;
VAL_ 1806 HiVltgChrgSysSplyFltIndOn 0 "FALSE" 1 "TRUE" ;
VAL_ 1806 HiVltgBatStopChrgBtnVsbl 0 "FALSE" 1 "TRUE" ;
VAL_ 1806 HiVltgBatChrgCordCnctdIndOn 0 "FALSE" 1 "TRUE" ;
VAL_ 1806 HiVltgBatBulkChrgCmplt 0 "FALSE" 1 "TRUE" ;
VAL_ 1806 ElecPrplMtrOvrSpdIndOn 0 "FALSE" 1 "TRUE" ;
VAL_ 1806 HiVltgChrgInhbRsn 0 "No Action" 1 "Cord Not Fully Inserted" 2 "Cord Lock Not Engaged" 3 "See Charging Station" ;
VAL_ 1806 DrvCycEleclEngyUsd_DuD 0 "FALSE" 1 "TRUE" ;
VAL_ 1259 HiVltgBatPrplRng_Inv 0 "FALSE" 1 "TRUE" ;
VAL_ 1259 HiVltgBatPrplRng_DuD 0 "FALSE" 1 "TRUE" ;
VAL_ 1259 HiVltgBatRmnUsblEngy_Inv 0 "FALSE" 1 "TRUE" ;
VAL_ 1259 HiVltgBatRmnUsblEngy_DuD 0 "FALSE" 1 "TRUE" ;
VAL_ 1807 DispHiVltgBatChrgCmpltInfo 0 "FALSE" 1 "TRUE" ;
VAL_ 1808 ElecRateSchedSsnResp 0 "No Action" 1 "Summer" 2 "Winter" 3 "Yearly" ;
VAL_ 1808 HiVltgBatTotUsblEngy_Inv 0 "FALSE" 1 "TRUE" ;
VAL_ 1808 HiVltgBatTotUsblEngy_DuD 0 "FALSE" 1 "TRUE" ;
VAL_ 1808 ElecRateSchedSsnStrtMthResp 0 "No Action" 1 "January" 2 "February" 3 "March" 4 "April" 5 "May" 6 "June" 7 "July" 8 "August" 9 "September" 10 "October" 11 "November" 12 "December" ;
VAL_ 944 StrgWhlTchSnsHndsOnStat 0 "Hands Off" 1 "Hands On" ;
